VERSION "HNNBNNNYNNNNNNNNNNNNNNNNNNNNNNNNNNNNNNNNNN/4/%%%/4/'%**4NNN///"

NS_ :

BS_:

BU_: BAP_Tester CGS Gateway Gateway_PAG HUD Kombi Kombi_LB Kombi_PAG Waehlhebel_SB

BO_ 1640 Klima_12: 8 Gateway
 SG_ KL_LRH_Taster : 0|1@1+ (1.0,0.0) [0.0|1] ""  Vector__XXX
 SG_ KL_LRH_Stufe : 1|2@1+ (1.0,0.0) [0.0|3] ""  Kombi,Kombi_LB
 SG_ HSH_Taster : 3|2@1+ (1.0,0.0) [0.0|3] ""  Vector__XXX
 SG_ FSH_Taster : 5|1@1+ (1.0,0.0) [0.0|1] ""  Vector__XXX
 SG_ KL_Zuheizer_Freigabe : 6|1@1+ (1.0,0.0) [0.0|1] ""  Vector__XXX
 SG_ KL_Beschlagsgefahr : 7|1@1+ (1.0,0.0) [0.0|1] ""  Vector__XXX
 SG_ KL_SIH_Soll_li : 8|3@1+ (1,0) [0|6] ""  Vector__XXX
 SG_ KL_SIH_Soll_re : 11|3@1+ (1,0) [0|6] ""  Vector__XXX
 SG_ KRH_Soll_li : 14|2@1+ (1.0,0.0) [0.0|3] ""  Vector__XXX
 SG_ KL_SIL_Soll_li : 16|3@1+ (1,0) [0|6] ""  Vector__XXX
 SG_ KL_SIL_Soll_re : 19|3@1+ (1,0) [0|6] ""  Vector__XXX
 SG_ KRH_Soll_re : 22|2@1+ (1.0,0.0) [0.0|3] ""  Vector__XXX
 SG_ KL_Geblspng_Soll : 24|8@1+ (0.05,1.45) [1.50|14.00] "Unit_Volt"  Vector__XXX
 SG_ KL_Geblspng_Fond_Soll : 32|8@1+ (0.05,1.45) [1.50|14.00] "Unit_Volt"  Vector__XXX
 SG_ KL_I_Geblaese : 40|8@1+ (0.25,0) [0.00|63.50] "Unit_Amper"  Vector__XXX
 SG_ KL_Kompressorstrom_soll : 48|10@1+ (1,0) [0|1021] ""  Vector__XXX
 SG_ KL_Umluftklappe_Status : 58|4@1+ (1.0,0.0) [0.0|15] ""  Vector__XXX
 SG_ KL_PTC_Verbauinfo : 62|2@1+ (1.0,0.0) [0.0|3] ""  Vector__XXX

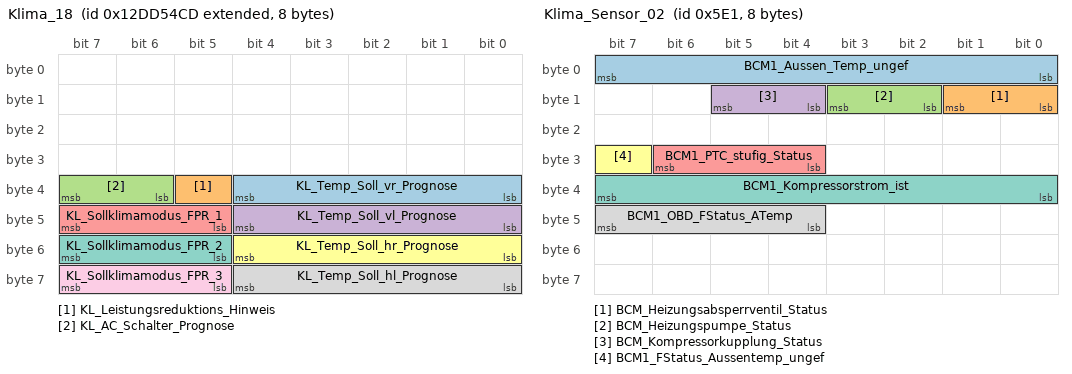
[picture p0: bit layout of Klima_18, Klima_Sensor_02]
BO_ 2463978701 Klima_18: 8 Gateway
 SG_ KL_Temp_Soll_vr_Prognose : 32|5@1+ (0.5,15.5) [15.5|30.0] "Unit_DegreCelsi"  Vector__XXX
 SG_ KL_Leistungsreduktions_Hinweis : 37|1@1+ (1.0,0.0) [0.0|1] ""  Kombi_PAG
 SG_ KL_AC_Schalter_Prognose : 38|2@1+ (1.0,0.0) [0.0|3] ""  Vector__XXX
 SG_ KL_Temp_Soll_vl_Prognose : 40|5@1+ (0.5,15.5) [15.5|30.0] "Unit_DegreCelsi"  Vector__XXX
 SG_ KL_Sollklimamodus_FPR_1 : 45|3@1+ (1.0,0.0) [0.0|7] ""  Vector__XXX
 SG_ KL_Temp_Soll_hr_Prognose : 48|5@1+ (0.5,15.5) [15.5|30.0] "Unit_DegreCelsi"  Vector__XXX
 SG_ KL_Sollklimamodus_FPR_2 : 53|3@1+ (1.0,0.0) [0.0|7] ""  Vector__XXX
 SG_ KL_Temp_Soll_hl_Prognose : 56|5@1+ (0.5,15.5) [15.5|30.0] "Unit_DegreCelsi"  Vector__XXX
 SG_ KL_Sollklimamodus_FPR_3 : 61|3@1+ (1.0,0.0) [0.0|7] ""  Vector__XXX

BO_ 1505 Klima_Sensor_02: 8 Gateway
 SG_ BCM1_Aussen_Temp_ungef : 0|8@1+ (0.5,-50) [-50.0|76.0] "Unit_DegreCelsi"  Kombi,Kombi_LB,Kombi_PAG
 SG_ BCM_Heizungsabsperrventil_Status : 8|2@1+ (1.0,0.0) [0.0|3] ""  Vector__XXX
 SG_ BCM_Heizungspumpe_Status : 10|2@1+ (1.0,0.0) [0.0|3] ""  Vector__XXX
 SG_ BCM_Kompressorkupplung_Status : 12|2@1+ (1.0,0.0) [0.0|3] ""  Vector__XXX
 SG_ BCM1_PTC_stufig_Status : 28|3@1+ (1.0,0.0) [0.0|7] ""  Vector__XXX
 SG_ BCM1_FStatus_Aussentemp_ungef : 31|1@1+ (1.0,0.0) [0.0|1] ""  Kombi,Kombi_LB,Kombi_PAG
 SG_ BCM1_Kompressorstrom_ist : 32|8@1+ (4,0) [0|1000] "Unit_MilliAmper"  Vector__XXX
 SG_ BCM1_OBD_FStatus_ATemp : 44|4@1+ (1.0,0.0) [0.0|15] ""  Vector__XXX

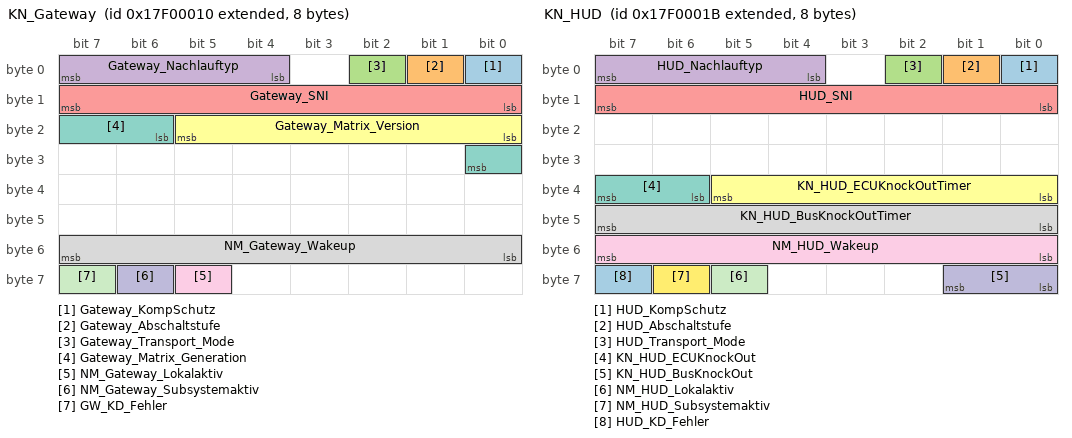
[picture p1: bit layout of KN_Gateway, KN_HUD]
BO_ 2549088272 KN_Gateway: 8 Gateway
 SG_ Gateway_KompSchutz : 0|1@1+ (1.0,0.0) [0.0|1] ""  Vector__XXX
 SG_ Gateway_Abschaltstufe : 1|1@1+ (1.0,0.0) [0.0|1] ""  Vector__XXX
 SG_ Gateway_Transport_Mode : 2|1@1+ (1.0,0.0) [0.0|1] ""  Vector__XXX
 SG_ Gateway_Nachlauftyp : 4|4@1+ (1.0,0.0) [0.0|15] ""  Vector__XXX
 SG_ Gateway_SNI : 8|8@1+ (1.0,0.0) [0.0|255] ""  Vector__XXX
 SG_ Gateway_Matrix_Version : 16|6@1+ (1,0) [0|63] "Unit_None"  Vector__XXX
 SG_ Gateway_Matrix_Generation : 22|3@1+ (1,0) [0|7] "Unit_None"  Vector__XXX
 SG_ NM_Gateway_Wakeup : 48|8@1+ (1.0,0.0) [0.0|255] ""  Vector__XXX
 SG_ NM_Gateway_Lokalaktiv : 61|1@1+ (1.0,0.0) [0.0|1] ""  Vector__XXX
 SG_ NM_Gateway_Subsystemaktiv : 62|1@1+ (1.0,0.0) [0.0|1] ""  Vector__XXX
 SG_ GW_KD_Fehler : 63|1@1+ (1.0,0.0) [0.0|1] ""  Vector__XXX

BO_ 2549088283 KN_HUD: 8 HUD
 SG_ HUD_KompSchutz : 0|1@1+ (1.0,0.0) [0.0|1] ""  Vector__XXX
 SG_ HUD_Abschaltstufe : 1|1@1+ (1.0,0.0) [0.0|1] ""  Vector__XXX
 SG_ HUD_Transport_Mode : 2|1@1+ (1.0,0.0) [0.0|1] ""  Vector__XXX
 SG_ HUD_Nachlauftyp : 4|4@1+ (1.0,0.0) [0.0|15] ""  Gateway,Gateway_PAG
 SG_ HUD_SNI : 8|8@1+ (1.0,0.0) [0.0|255] ""  Gateway,Gateway_PAG
 SG_ KN_HUD_ECUKnockOutTimer : 32|6@1+ (1,0) [0|62] "Unit_Minut"  Gateway,Gateway_PAG
 SG_ KN_HUD_ECUKnockOut : 38|2@1+ (1.0,0.0) [0.0|3] ""  Gateway,Gateway_PAG
 SG_ KN_HUD_BusKnockOutTimer : 40|8@1+ (1,0) [0|254] "Unit_Minut"  Gateway,Gateway_PAG
 SG_ NM_HUD_Wakeup : 48|8@1+ (1.0,0.0) [0.0|255] ""  Vector__XXX
 SG_ KN_HUD_BusKnockOut : 56|2@1+ (1.0,0.0) [0.0|3] ""  Gateway,Gateway_PAG
 SG_ NM_HUD_Lokalaktiv : 61|1@1+ (1.0,0.0) [0.0|1] ""  Gateway,Gateway_PAG
 SG_ NM_HUD_Subsystemaktiv : 62|1@1+ (1.0,0.0) [0.0|1] ""  Vector__XXX
 SG_ HUD_KD_Fehler : 63|1@1+ (1.0,0.0) [0.0|1] ""  Gateway,Gateway_PAG

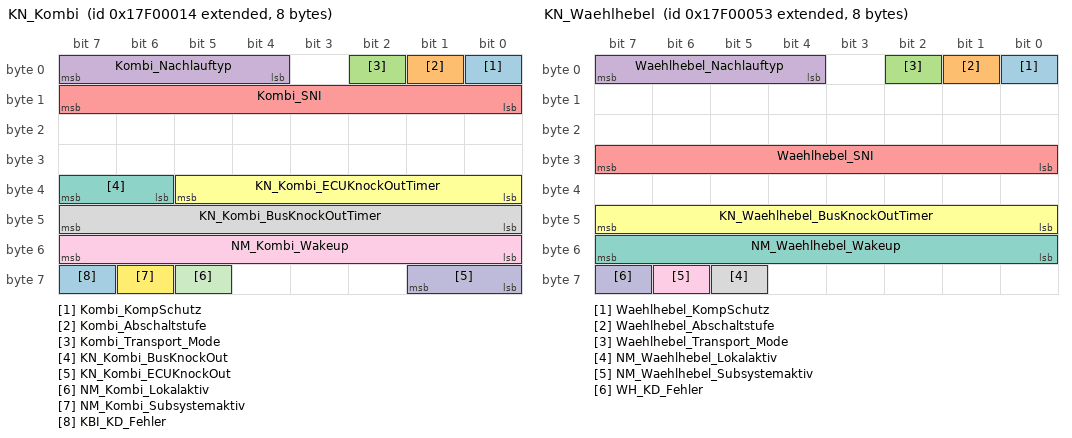
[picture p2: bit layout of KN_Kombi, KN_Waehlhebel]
BO_ 2549088276 KN_Kombi: 8 Kombi
 SG_ Kombi_KompSchutz : 0|1@1+ (1.0,0.0) [0.0|1] ""  Vector__XXX
 SG_ Kombi_Abschaltstufe : 1|1@1+ (1.0,0.0) [0.0|1] ""  Vector__XXX
 SG_ Kombi_Transport_Mode : 2|1@1+ (1.0,0.0) [0.0|1] ""  Vector__XXX
 SG_ Kombi_Nachlauftyp : 4|4@1+ (1.0,0.0) [0.0|15] ""  Gateway,Gateway_PAG
 SG_ Kombi_SNI : 8|8@1+ (1.0,0.0) [0.0|255] ""  Gateway,Gateway_PAG
 SG_ KN_Kombi_ECUKnockOutTimer : 32|6@1+ (1,0) [0|62] "Unit_Minut"  Gateway,Gateway_PAG
 SG_ KN_Kombi_BusKnockOut : 38|2@1+ (1.0,0.0) [0.0|3] ""  Gateway,Gateway_PAG
 SG_ KN_Kombi_BusKnockOutTimer : 40|8@1+ (1,0) [0|254] ""  Gateway,Gateway_PAG
 SG_ NM_Kombi_Wakeup : 48|8@1+ (1.0,0.0) [0.0|255] ""  Vector__XXX
 SG_ KN_Kombi_ECUKnockOut : 56|2@1+ (1.0,0.0) [0.0|3] ""  Gateway,Gateway_PAG
 SG_ NM_Kombi_Lokalaktiv : 61|1@1+ (1.0,0.0) [0.0|1] ""  Gateway,Gateway_PAG
 SG_ NM_Kombi_Subsystemaktiv : 62|1@1+ (1.0,0.0) [0.0|1] ""  Gateway,Gateway_PAG
 SG_ KBI_KD_Fehler : 63|1@1+ (1.0,0.0) [0.0|1] ""  Gateway,Gateway_PAG

BO_ 2549088339 KN_Waehlhebel: 8 CGS
 SG_ Waehlhebel_KompSchutz : 0|1@1+ (1.0,0.0) [0.0|1] ""  Vector__XXX
 SG_ Waehlhebel_Abschaltstufe : 1|1@1+ (1.0,0.0) [0.0|1] ""  Vector__XXX
 SG_ Waehlhebel_Transport_Mode : 2|1@1+ (1.0,0.0) [0.0|1] ""  Vector__XXX
 SG_ Waehlhebel_Nachlauftyp : 4|4@1+ (1.0,0.0) [0.0|15] ""  Gateway,Gateway_PAG
 SG_ Waehlhebel_SNI : 24|8@1+ (1.0,0.0) [0.0|255] ""  Gateway,Gateway_PAG
 SG_ KN_Waehlhebel_BusKnockOutTimer : 40|8@1+ (1,0) [0|254] ""  Gateway,Gateway_PAG
 SG_ NM_Waehlhebel_Wakeup : 48|8@1+ (1.0,0.0) [0.0|255] ""  Vector__XXX
 SG_ NM_Waehlhebel_Lokalaktiv : 61|1@1+ (1.0,0.0) [0.0|1] ""  Gateway,Gateway_PAG
 SG_ NM_Waehlhebel_Subsystemaktiv : 62|1@1+ (1.0,0.0) [0.0|1] ""  Vector__XXX
 SG_ WH_KD_Fehler : 63|1@1+ (1.0,0.0) [0.0|1] ""  Gateway,Gateway_PAG

BO_ 779 Kombi_01: 8 Kombi
 SG_ KBI_ABS_Lampe : 0|1@1+ (1.0,0.0) [0.0|1] ""  Gateway,Gateway_PAG
 SG_ KBI_ESP_Lampe : 1|1@1+ (1.0,0.0) [0.0|1] ""  Gateway,Gateway_PAG
 SG_ KBI_BKL_Lampe : 2|1@1+ (1.0,0.0) [0.0|1] ""  Gateway,Gateway_PAG
 SG_ KBI_Airbag_Lampe : 3|1@1+ (1.0,0.0) [0.0|1] ""  Gateway,Gateway_PAG
 SG_ KBI_SILA_gueltig : 4|1@1+ (1.0,0.0) [0.0|1] ""  Gateway,Gateway_PAG
 SG_ KBI_Lenkung_Lampe : 5|1@1+ (1,0) [0|1] ""  Gateway,Gateway_PAG
 SG_ KBI_Vorglueh_System_Lampe : 6|1@1+ (1.0,0.0) [0.0|1] ""  Gateway,Gateway_PAG
 SG_ KBI_NV_in_Anzeige : 7|1@1+ (1.0,0.0) [0.0|1] ""  Gateway,Gateway_PAG
 SG_ Kombi_01_BZ : 8|4@1+ (1,0) [0|15] ""  Gateway,Gateway_PAG
 SG_ KBI_Anzeigestatus_ACC : 12|1@1+ (1.0,0.0) [0.0|1] ""  Gateway,Gateway_PAG,HUD
 SG_ KBI_Anzeigestatus_GRA : 13|2@1+ (1.0,0.0) [0.0|3] ""  Gateway,Gateway_PAG
 SG_ KBI_Tankwarnung : 16|1@1+ (1.0,0.0) [0.0|1] ""  Gateway,Gateway_PAG
 SG_ KBI_MFA_v_Einheit_01 : 17|1@1+ (1.0,0.0) [0.0|1] ""  Gateway,Gateway_PAG,HUD
 SG_ KBI_im_Stellgliedtest : 18|1@1+ (1.0,0.0) [0.0|1] ""  Gateway,Gateway_PAG
 SG_ KBI_Anzeigefehler_LDW : 19|2@1+ (1.0,0.0) [0.0|3] ""  Gateway,Gateway_PAG
 SG_ KBI_Tankwarnung_ungueltig : 21|1@1+ (1.0,0.0) [0.0|1] ""  Gateway,Gateway_PAG
 SG_ KBI_Handbremse : 23|1@1+ (1.0,0.0) [0.0|1] ""  Gateway,Gateway_PAG
 SG_ KBI_V_Digital : 24|9@1+ (1,0) [0|511] ""  Gateway,Gateway_PAG,HUD
 SG_ KBI_PLA_in_Anzeige : 33|1@1+ (1.0,0.0) [0.0|1] ""  Gateway,Gateway_PAG
 SG_ KBI_Anzeigefehler_NV : 34|1@1+ (1.0,0.0) [0.0|1] ""  Gateway,Gateway_PAG
 SG_ KBI_Anzeigestatus_LIM : 35|2@1+ (1.0,0.0) [0.0|3] ""  Gateway,Gateway_PAG
 SG_ KBI_ARA_in_Anzeige : 37|1@1+ (1.0,0.0) [0.0|1] ""  Gateway,Gateway_PAG
 SG_ KBI_Taster_Lift : 38|1@1+ (1.0,0.0) [0.0|1] ""  Gateway,Gateway_PAG
 SG_ KBI_Taster_Fahrwerk : 39|1@1+ (1.0,0.0) [0.0|1] ""  Gateway,Gateway_PAG
 SG_ KBI_GRA_Hauptschalter : 40|2@1+ (1.0,0.0) [0.0|3] ""  Gateway,Gateway_PAG
 SG_ KBI_Bestaetigung_ESP_Off : 42|2@1+ (1.0,0.0) [0.0|3] ""  Gateway,Gateway_PAG
 SG_ KBI_angez_Geschw : 48|10@1+ (0.32,0) [0.00|325.12] "Unit_KiloMeterPerHour"  Gateway,Gateway_PAG
 SG_ KBI_Einheit_Tacho : 58|1@1+ (1.0,0.0) [0.0|1] ""  Gateway,Gateway_PAG
 SG_ KBI_Konsistenz_ACC : 59|1@1+ (1.0,0.0) [0.0|1] ""  Gateway,Gateway_PAG
 SG_ KBI_Fehler_Anzeige_ACC : 60|1@1+ (1.0,0.0) [0.0|1] ""  Gateway,Gateway_PAG
 SG_ KBI_Anzeigefehler_SWA : 61|2@1+ (1.0,0.0) [0.0|3] ""  Gateway,Gateway_PAG
 SG_ KBI_Systemstatus : 63|1@1+ (1.0,0.0) [0.0|1] ""  Gateway,Gateway_PAG

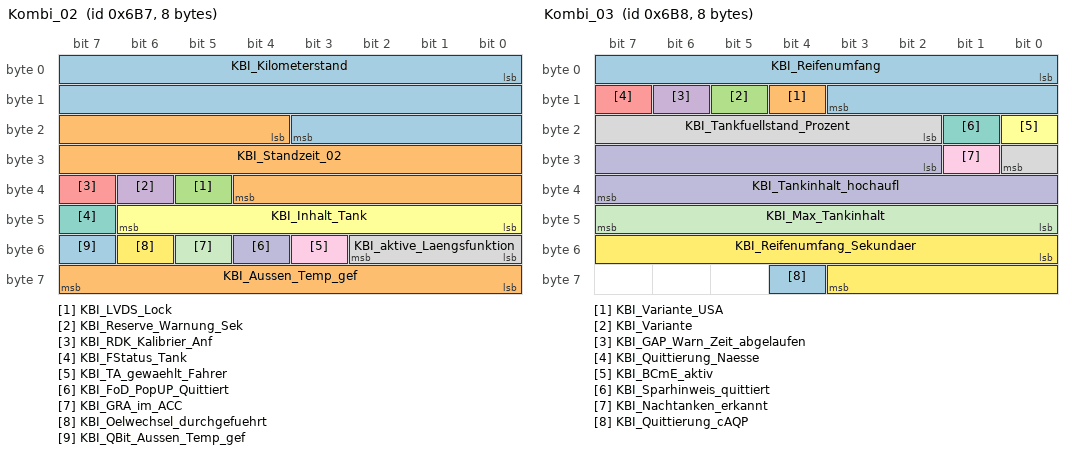
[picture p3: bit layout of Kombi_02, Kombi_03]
BO_ 1719 Kombi_02: 8 Kombi
 SG_ KBI_Kilometerstand : 0|20@1+ (1,0) [0|1048573] "Unit_KiloMeter"  Gateway,Gateway_PAG
 SG_ KBI_Standzeit_02 : 20|17@1+ (1,0) [0|131068] "Unit_Secon"  Gateway,Gateway_PAG
 SG_ KBI_LVDS_Lock : 37|1@1+ (1.0,0.0) [0.0|1] ""  Gateway,Gateway_PAG
 SG_ KBI_Reserve_Warnung_Sek : 38|1@1+ (1.0,0.0) [0.0|1] ""  Gateway,Gateway_PAG
 SG_ KBI_RDK_Kalibrier_Anf : 39|1@1+ (1.0,0.0) [0.0|1] ""  Gateway,Gateway_PAG
 SG_ KBI_Inhalt_Tank : 40|7@1+ (1,0) [0|125] "Unit_Liter"  Gateway,Gateway_PAG
 SG_ KBI_FStatus_Tank : 47|1@1+ (1.0,0.0) [0.0|1] ""  Gateway,Gateway_PAG
 SG_ KBI_aktive_Laengsfunktion : 48|3@1+ (1.0,0.0) [0.0|7] ""  Gateway,Gateway_PAG,HUD
 SG_ KBI_TA_gewaehlt_Fahrer : 51|1@1+ (1.0,0.0) [0.0|1] ""  Gateway,Gateway_PAG
 SG_ KBI_FoD_PopUP_Quittiert : 52|1@1+ (1.0,0.0) [0.0|1] ""  Gateway,Gateway_PAG
 SG_ KBI_GRA_im_ACC : 53|1@1+ (1.0,0.0) [0.0|1] ""  Gateway,Gateway_PAG
 SG_ KBI_Oelwechsel_durchgefuehrt : 54|1@1+ (1.0,0.0) [0.0|1] ""  Gateway,Gateway_PAG
 SG_ KBI_QBit_Aussen_Temp_gef : 55|1@1+ (1.0,0.0) [0.0|1] ""  Gateway,Gateway_PAG
 SG_ KBI_Aussen_Temp_gef : 56|8@1+ (0.5,-50) [-50.0|75.0] "Unit_DegreCelsi"  Gateway,Gateway_PAG

BO_ 1720 Kombi_03: 8 Kombi
 SG_ KBI_Reifenumfang : 0|12@1+ (1,0) [0|4095] "Unit_MilliMeter"  Gateway,Gateway_PAG
 SG_ KBI_Variante_USA : 12|1@1+ (1.0,0.0) [0.0|1] ""  Gateway,Gateway_PAG,HUD
 SG_ KBI_Variante : 13|1@1+ (1.0,0.0) [0.0|1] ""  Gateway,Gateway_PAG,HUD
 SG_ KBI_GAP_Warn_Zeit_abgelaufen : 14|1@1+ (1.0,0.0) [0.0|1] ""  Gateway,Gateway_PAG
 SG_ KBI_Quittierung_Naesse : 15|1@1+ (1.0,0.0) [0.0|1] ""  Gateway,Gateway_PAG
 SG_ KBI_BCmE_aktiv : 16|1@1+ (1.0,0.0) [0.0|1] ""  Gateway,Gateway_PAG
 SG_ KBI_Sparhinweis_quittiert : 17|1@1+ (1.0,0.0) [0.0|1] ""  Gateway,Gateway_PAG
 SG_ KBI_Tankfuellstand_Prozent : 18|7@1+ (1,0) [0|100] "Unit_PerCent"  Gateway,Gateway_PAG
 SG_ KBI_Nachtanken_erkannt : 25|1@1+ (1.0,0.0) [0.0|1] ""  Gateway,Gateway_PAG
 SG_ KBI_Tankinhalt_hochaufl : 26|14@1+ (0.01,0) [0.00|163.81] "Unit_Liter"  Gateway,Gateway_PAG
 SG_ KBI_Max_Tankinhalt : 40|8@1+ (0.5,0) [0.0|126.5] ""  Gateway,Gateway_PAG
 SG_ KBI_Reifenumfang_Sekundaer : 48|12@1+ (1,0) [0|4095] "Unit_MilliMeter"  Gateway,Gateway_PAG
 SG_ KBI_Quittierung_cAQP : 60|1@1+ (1.0,0.0) [0.0|1] ""  Gateway,Gateway_PAG

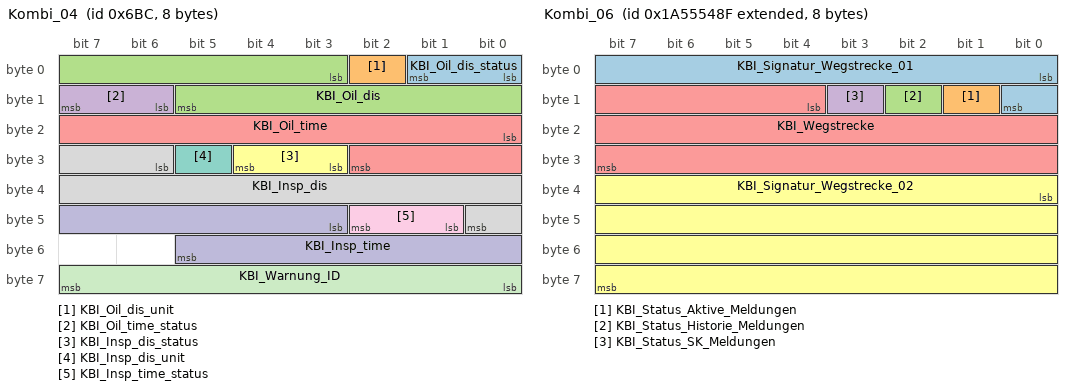
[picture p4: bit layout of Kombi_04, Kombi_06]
BO_ 1724 Kombi_04: 8 Kombi
 SG_ KBI_Oil_dis_status : 0|2@1+ (1.0,0.0) [0.0|3] ""  Gateway,Gateway_PAG
 SG_ KBI_Oil_dis_unit : 2|1@1+ (1.0,0.0) [0.0|1] ""  Gateway,Gateway_PAG
 SG_ KBI_Oil_dis : 3|11@1+ (100,0) [0|204700] ""  Gateway,Gateway_PAG
 SG_ KBI_Oil_time_status : 14|2@1+ (1.0,0.0) [0.0|3] ""  Gateway,Gateway_PAG
 SG_ KBI_Oil_time : 16|11@1+ (1,0) [0|2047] ""  Gateway,Gateway_PAG
 SG_ KBI_Insp_dis_status : 27|2@1+ (1.0,0.0) [0.0|3] ""  Gateway,Gateway_PAG
 SG_ KBI_Insp_dis_unit : 29|1@1+ (1.0,0.0) [0.0|1] ""  Gateway,Gateway_PAG
 SG_ KBI_Insp_dis : 30|11@1+ (100,0) [0|204700] ""  Gateway,Gateway_PAG
 SG_ KBI_Insp_time_status : 41|2@1+ (1.0,0.0) [0.0|3] ""  Gateway,Gateway_PAG
 SG_ KBI_Insp_time : 43|11@1+ (1,0) [0|2047] ""  Gateway,Gateway_PAG
 SG_ KBI_Warnung_ID : 56|8@1+ (1,0) [0|255] ""  Gateway,Gateway_PAG

BO_ 2589283471 Kombi_06: 8 Kombi
 SG_ KBI_Signatur_Wegstrecke_01 : 0|9@1+ (1.0,0.0) [0.0|511] ""  Gateway,Gateway_PAG
 SG_ KBI_Status_Aktive_Meldungen : 9|1@1+ (1.0,0.0) [0.0|1] ""  Gateway,Gateway_PAG
 SG_ KBI_Status_Historie_Meldungen : 10|1@1+ (1.0,0.0) [0.0|1] ""  Gateway,Gateway_PAG
 SG_ KBI_Status_SK_Meldungen : 11|1@1+ (1.0,0.0) [0.0|1] ""  Gateway,Gateway_PAG
 SG_ KBI_Wegstrecke : 12|20@1+ (1.0,0.0) [0.0|1048575] ""  Gateway,Gateway_PAG
 SG_ KBI_Signatur_Wegstrecke_02 : 32|32@1+ (1.0,0.0) [0.0|4294967295] ""  Gateway,Gateway_PAG

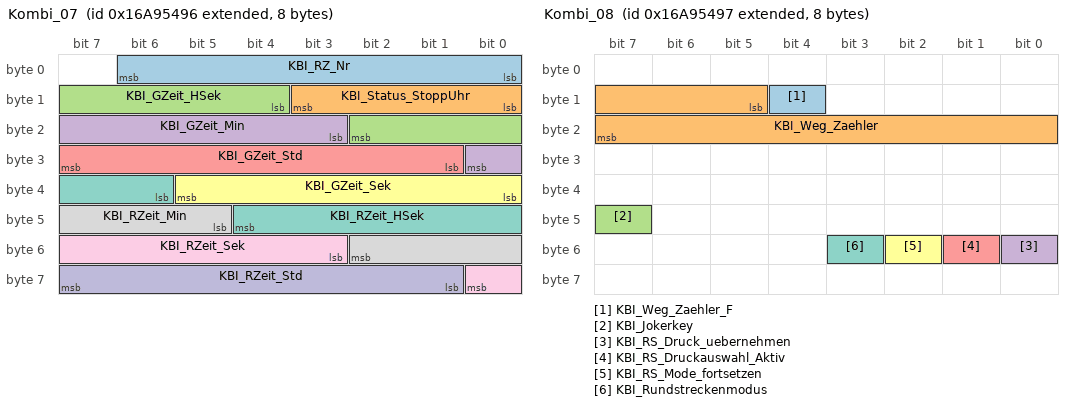
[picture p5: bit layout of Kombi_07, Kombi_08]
BO_ 2527679638 Kombi_07: 8 Kombi
 SG_ KBI_RZ_Nr : 0|7@1+ (1,0) [0|99] ""  Gateway,Gateway_PAG,HUD
 SG_ KBI_Status_StoppUhr : 8|4@1+ (1.0,0.0) [0.0|15] ""  Gateway,Gateway_PAG,HUD
 SG_ KBI_GZeit_HSek : 12|7@1+ (1,0) [0|99] "Unit_MilliSecon"  Gateway,Gateway_PAG,HUD
 SG_ KBI_GZeit_Min : 19|6@1+ (1,0) [0|59] "Unit_Minut"  Gateway,Gateway_PAG,HUD
 SG_ KBI_GZeit_Std : 25|7@1+ (1,0) [0|99] "Unit_Hours"  Gateway,Gateway_PAG,HUD
 SG_ KBI_GZeit_Sek : 32|6@1+ (1,0) [0|59] "Unit_Secon"  Gateway,Gateway_PAG,HUD
 SG_ KBI_RZeit_HSek : 38|7@1+ (1,0) [0|99] ""  Gateway,Gateway_PAG,HUD
 SG_ KBI_RZeit_Min : 45|6@1+ (1,0) [0|59] "Unit_Minut"  Gateway,Gateway_PAG,HUD
 SG_ KBI_RZeit_Sek : 51|6@1+ (1,0) [0|59] "Unit_Secon"  Gateway,Gateway_PAG,HUD
 SG_ KBI_RZeit_Std : 57|7@1+ (1,0) [0|99] "Unit_Hours"  Gateway,Gateway_PAG,HUD

BO_ 2527679639 Kombi_08: 8 Kombi
 SG_ KBI_Weg_Zaehler_F : 12|1@1+ (1.0,0.0) [0.0|1] ""  Gateway,Gateway_PAG
 SG_ KBI_Weg_Zaehler : 13|11@1+ (1,0) [0|2047] "Unit_Meter"  Gateway,Gateway_PAG
 SG_ KBI_Jokerkey : 47|1@1+ (1.0,0.0) [0.0|1] ""  Gateway,Gateway_PAG
 SG_ KBI_RS_Druck_uebernehmen : 48|1@1+ (1.0,0.0) [0.0|1] ""  Gateway,Gateway_PAG
 SG_ KBI_RS_Druckauswahl_Aktiv : 49|1@1+ (1.0,0.0) [0.0|1] ""  Gateway,Gateway_PAG
 SG_ KBI_RS_Mode_fortsetzen : 50|1@1+ (1.0,0.0) [0.0|1] ""  Gateway,Gateway_PAG
 SG_ KBI_Rundstreckenmodus : 51|1@1+ (1.0,0.0) [0.0|1] ""  Gateway,Gateway_PAG

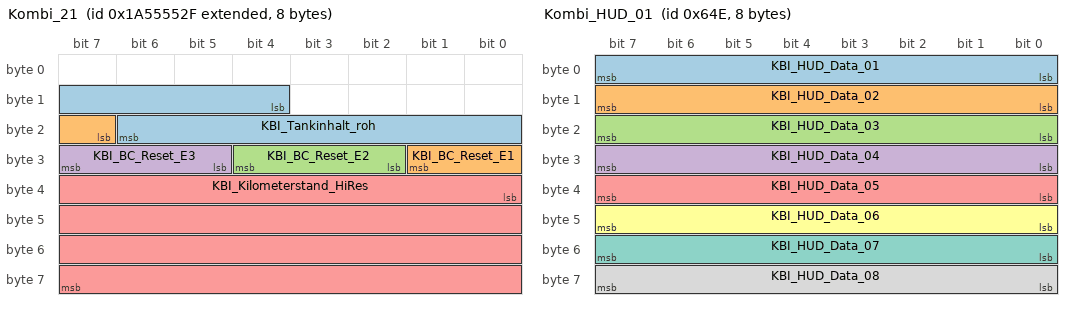
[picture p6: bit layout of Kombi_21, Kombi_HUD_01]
BO_ 2589283631 Kombi_21: 8 Kombi
 SG_ KBI_Tankinhalt_roh : 12|11@1+ (0.1,0) [0.0|204.5] "Unit_Liter"  Gateway,Gateway_PAG
 SG_ KBI_BC_Reset_E1 : 23|3@1+ (1.0,0.0) [0.0|7] ""  Gateway,Gateway_PAG
 SG_ KBI_BC_Reset_E2 : 26|3@1+ (1.0,0.0) [0.0|7] ""  Gateway,Gateway_PAG
 SG_ KBI_BC_Reset_E3 : 29|3@1+ (1.0,0.0) [0.0|7] ""  Gateway,Gateway_PAG
 SG_ KBI_Kilometerstand_HiRes : 32|32@1+ (0.1,0) [0.0|429496729.5] "Unit_KiloMeter"  Gateway,Gateway_PAG

BO_ 2527679656 Kombi_23: 8 Kombi
 SG_ KBI_StartupAnimation : 61|3@1+ (1.0,0.0) [0.0|7] ""  Gateway,Gateway_PAG

BO_ 1614 Kombi_HUD_01: 8 Kombi
 SG_ KBI_HUD_Data_01 : 0|8@1+ (1.0,0.0) [0.0|255] ""  Gateway,Gateway_PAG,HUD
 SG_ KBI_HUD_Data_02 : 8|8@1+ (1.0,0.0) [0.0|255] ""  Gateway,Gateway_PAG,HUD
 SG_ KBI_HUD_Data_03 : 16|8@1+ (1.0,0.0) [0.0|255] ""  Gateway,Gateway_PAG,HUD
 SG_ KBI_HUD_Data_04 : 24|8@1+ (1.0,0.0) [0.0|255] ""  Gateway,Gateway_PAG,HUD
 SG_ KBI_HUD_Data_05 : 32|8@1+ (1.0,0.0) [0.0|255] ""  Gateway,Gateway_PAG,HUD
 SG_ KBI_HUD_Data_06 : 40|8@1+ (1.0,0.0) [0.0|255] ""  Gateway,Gateway_PAG,HUD
 SG_ KBI_HUD_Data_07 : 48|8@1+ (1.0,0.0) [0.0|255] ""  Gateway,Gateway_PAG,HUD
 SG_ KBI_HUD_Data_08 : 56|8@1+ (1.0,0.0) [0.0|255] ""  Gateway,Gateway_PAG,HUD

BO_ 2549874964 KS_Kombi_Req: 8 Gateway
 SG_ KS_Kombi_Req_Data : 0|64@1+ (1.0,0.0) [0.0|18446744073709551615] ""  Kombi,Kombi_LB,Kombi_PAG

BO_ 2550006036 KS_Kombi_Resp: 8 Kombi
 SG_ KS_Kombi_Resp_Data : 0|64@1+ (1.0,0.0) [0.0|18446744073709551615] ""  Gateway,Gateway_PAG

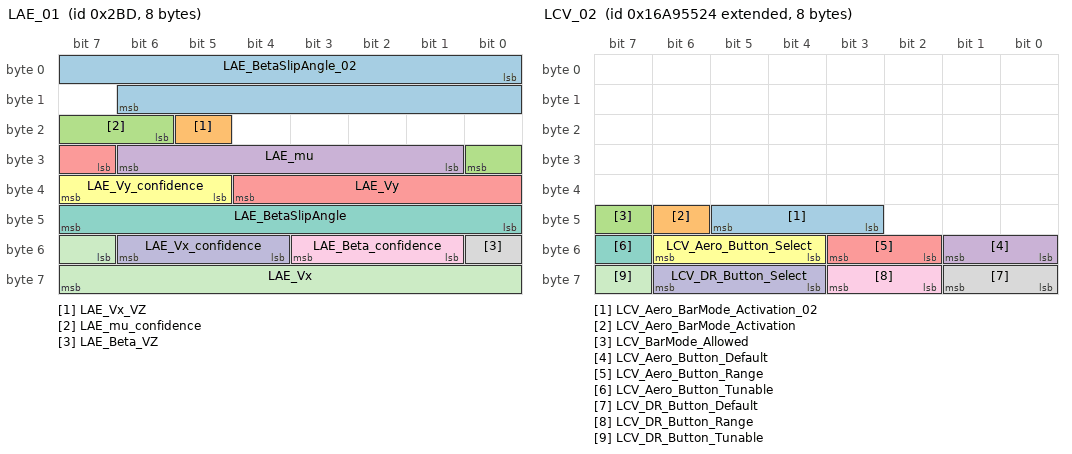
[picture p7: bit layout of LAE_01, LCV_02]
BO_ 701 LAE_01: 8 Gateway
 SG_ LAE_BetaSlipAngle_02 : 0|15@1+ (0.01,0) [0.00|327.65] "Unit_DegreOfArc"  Kombi_LB
 SG_ LAE_Vx_VZ : 21|1@1+ (1.0,0.0) [0.0|1] ""  Kombi_LB
 SG_ LAE_mu_confidence : 22|3@1+ (1.0,0.0) [0.0|7] ""  Kombi_LB
 SG_ LAE_mu : 25|6@1+ (0.05,0) [0.00|3.05] "Unit_None"  Kombi_LB
 SG_ LAE_Vy : 31|6@1+ (0.491803,0) [0.000000|29.999983] "Unit_MeterPerSecon"  Kombi_LB
 SG_ LAE_Vy_confidence : 37|3@1+ (1.0,0.0) [0.0|7] ""  Kombi_LB
 SG_ LAE_BetaSlipAngle : 40|8@1+ (0.711462451,0) [0E-9|180.000000103] "Unit_DegreOfArc"  Kombi_LB
 SG_ LAE_Beta_VZ : 48|1@1+ (1.0,0.0) [0.0|1] ""  Kombi_LB
 SG_ LAE_Beta_confidence : 49|3@1+ (1.0,0.0) [0.0|7] ""  Kombi_LB
 SG_ LAE_Vx_confidence : 52|3@1+ (1.0,0.0) [0.0|7] ""  Kombi_LB
 SG_ LAE_Vx : 55|9@1+ (0.25540275,0) [0E-8|129.99999975] "Unit_MeterPerSecon"  Kombi_LB

BO_ 2463978818 LCV_01: 8 Gateway
 SG_ LCV_01_CRC : 0|8@1+ (1,0) [0|255] ""  Kombi_LB
 SG_ LCV_01_BZ : 8|4@1+ (1,0) [0|15] ""  Kombi_LB
 SG_ LCV_ESP_Zuschaltung : 12|1@1+ (1.0,0.0) [0.0|1] ""  Kombi_LB
 SG_ LCV_BrakeGongTemp : 13|1@1+ (1.0,0.0) [0.0|1] ""  Kombi_LB
 SG_ BTM_BrakeSystem_Status : 14|4@1+ (1.0,0.0) [0.0|15] ""  Kombi_LB
 SG_ BTM_BrakeSystem_Text : 18|4@1+ (1.0,0.0) [0.0|15] ""  Kombi_LB
 SG_ BTM_BrakeSystem_Warnlampe : 22|1@1+ (1.0,0.0) [0.0|1] ""  Kombi_LB
 SG_ LCV_Aero_EngineBay_Cooling : 23|1@1+ (1.0,0.0) [0.0|1] ""  Kombi_LB
 SG_ LCV_Aero_Front_System_Status : 24|3@1+ (1.0,0.0) [0.0|7] ""  Kombi_LB
 SG_ LCV_Aero_Rear_System_Status : 27|3@1+ (1.0,0.0) [0.0|7] ""  Kombi_LB
 SG_ LCV_DR_Systemstatus : 30|3@1+ (1.0,0.0) [0.0|7] ""  Kombi_LB
 SG_ LCV_DR_Text : 33|3@1+ (1.0,0.0) [0.0|7] ""  Kombi_LB
 SG_ LCV_DR_Warnlampe : 36|2@1+ (1.0,0.0) [0.0|3] ""  Kombi_LB
 SG_ LCV_Lift_Status : 38|4@1+ (1.0,0.0) [0.0|15] ""  Kombi_LB
 SG_ LCV_Lift_Text : 42|3@1+ (1.0,0.0) [0.0|7] ""  Kombi_LB
 SG_ LCV_Lift_Warnlampe_Status : 45|2@1+ (1.0,0.0) [0.0|3] ""  Kombi_LB
 SG_ LCV_Aero_Perf_Limit_Speed : 47|8@1+ (1,100) [100|353] "Unit_KiloMeterPerHour"  Kombi_LB
 SG_ LCV_Aero_Perf_Limit : 55|1@1+ (1.0,0.0) [0.0|1] ""  Kombi_LB
 SG_ LCV_HD_offen : 56|1@1+ (1.0,0.0) [0.0|1] ""  Kombi_LB
 SG_ LCV_Aero_Text : 57|3@1+ (1.0,0.0) [0.0|7] ""  Kombi_LB

BO_ 2527679780 LCV_02: 8 Gateway
 SG_ LCV_Aero_BarMode_Activation_02 : 43|3@1+ (1.0,0.0) [0.0|7] ""  Kombi_LB
 SG_ LCV_Aero_BarMode_Activation : 46|1@1+ (1.0,0.0) [0.0|1] ""  Vector__XXX
 SG_ LCV_BarMode_Allowed : 47|1@1+ (1.0,0.0) [0.0|1] ""  Kombi_LB
 SG_ LCV_Aero_Button_Default : 48|2@1+ (1.0,0.0) [0.0|3] ""  Kombi_LB
 SG_ LCV_Aero_Button_Range : 50|2@1+ (1.0,0.0) [0.0|3] ""  Kombi_LB
 SG_ LCV_Aero_Button_Select : 52|3@1+ (1.0,0.0) [0.0|7] ""  Kombi_LB
 SG_ LCV_Aero_Button_Tunable : 55|1@1+ (1.0,0.0) [0.0|1] ""  Kombi_LB
 SG_ LCV_DR_Button_Default : 56|2@1+ (1.0,0.0) [0.0|3] ""  Kombi_LB
 SG_ LCV_DR_Button_Range : 58|2@1+ (1.0,0.0) [0.0|3] ""  Kombi_LB
 SG_ LCV_DR_Button_Select : 60|3@1+ (1.0,0.0) [0.0|7] ""  Kombi_LB
 SG_ LCV_DR_Button_Tunable : 63|1@1+ (1.0,0.0) [0.0|1] ""  Kombi_LB

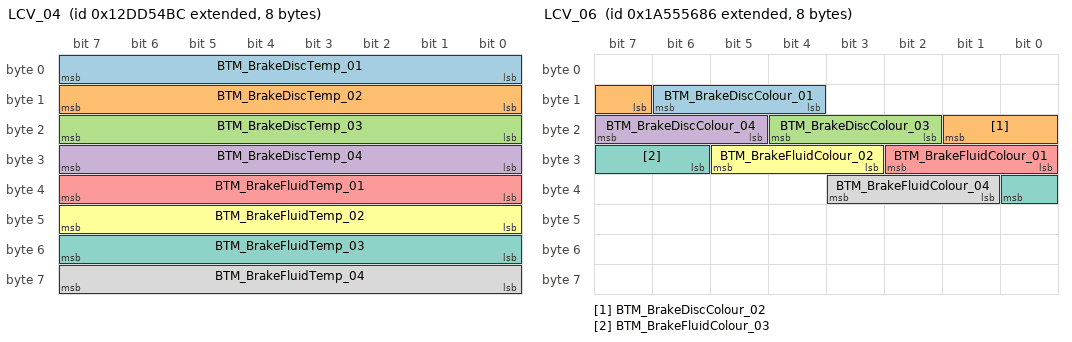
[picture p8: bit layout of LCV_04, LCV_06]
BO_ 2463978684 LCV_04: 8 Gateway
 SG_ BTM_BrakeDiscTemp_01 : 0|8@1+ (10,-30) [-30|2500] "Unit_DegreCelsi"  Kombi_LB
 SG_ BTM_BrakeDiscTemp_02 : 8|8@1+ (10,-30) [-30|2500] "Unit_DegreCelsi"  Kombi_LB
 SG_ BTM_BrakeDiscTemp_03 : 16|8@1+ (10,-30) [-30|2500] "Unit_DegreCelsi"  Kombi_LB
 SG_ BTM_BrakeDiscTemp_04 : 24|8@1+ (10,-30) [-30|2500] "Unit_DegreCelsi"  Kombi_LB
 SG_ BTM_BrakeFluidTemp_01 : 32|8@1+ (2,-30) [-30|476] "Unit_DegreCelsi"  Kombi_LB
 SG_ BTM_BrakeFluidTemp_02 : 40|8@1+ (2,-30) [-30|476] "Unit_DegreCelsi"  Kombi_LB
 SG_ BTM_BrakeFluidTemp_03 : 48|8@1+ (2,-30) [-30|476] "Unit_DegreCelsi"  Kombi_LB
 SG_ BTM_BrakeFluidTemp_04 : 56|8@1+ (2,-30) [-30|476] "Unit_DegreCelsi"  Kombi_LB

BO_ 548 LCV_05: 8 Gateway
 SG_ LCV_Aero_Front_Ratio : 12|7@1+ (1,0) [0|125] "Unit_None"  Kombi_LB
 SG_ LCV_Aero_Long_Ratio : 19|7@1+ (1,0) [0|125] "Unit_None"  Kombi_LB

BO_ 2589283974 LCV_06: 8 Gateway
 SG_ BTM_BrakeDiscColour_01 : 12|3@1+ (1.0,0.0) [0.0|7] ""  Kombi_LB
 SG_ BTM_BrakeDiscColour_02 : 15|3@1+ (1.0,0.0) [0.0|7] ""  Kombi_LB
 SG_ BTM_BrakeDiscColour_03 : 18|3@1+ (1.0,0.0) [0.0|7] ""  Kombi_LB
 SG_ BTM_BrakeDiscColour_04 : 21|3@1+ (1.0,0.0) [0.0|7] ""  Kombi_LB
 SG_ BTM_BrakeFluidColour_01 : 24|3@1+ (1.0,0.0) [0.0|7] ""  Kombi_LB
 SG_ BTM_BrakeFluidColour_02 : 27|3@1+ (1.0,0.0) [0.0|7] ""  Kombi_LB
 SG_ BTM_BrakeFluidColour_03 : 30|3@1+ (1.0,0.0) [0.0|7] ""  Kombi_LB
 SG_ BTM_BrakeFluidColour_04 : 33|3@1+ (1.0,0.0) [0.0|7] ""  Kombi_LB

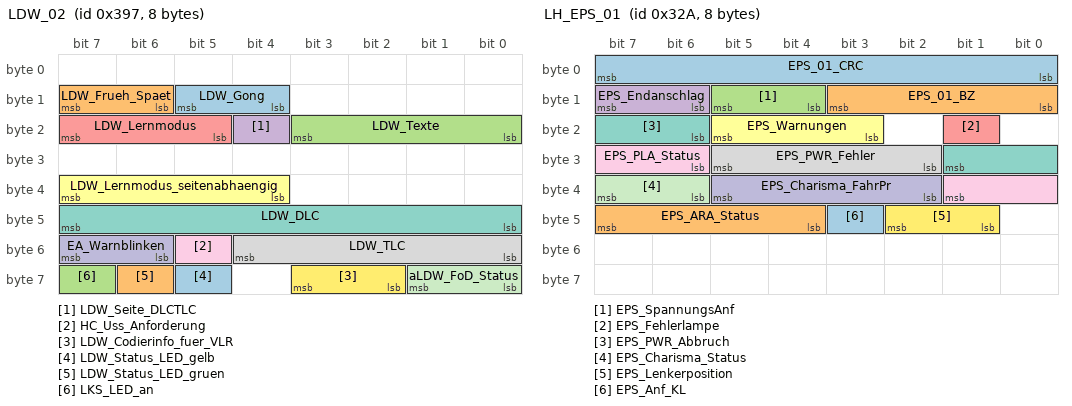
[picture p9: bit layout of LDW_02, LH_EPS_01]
BO_ 919 LDW_02: 8 Gateway
 SG_ LDW_Gong : 12|2@1+ (1.0,0.0) [0.0|3] ""  Kombi,Kombi_LB,Kombi_PAG
 SG_ LDW_Frueh_Spaet : 14|2@1+ (1.0,0.0) [0.0|3] ""  Vector__XXX
 SG_ LDW_Texte : 16|4@1+ (1.0,0.0) [0.0|15] ""  HUD,Kombi,Kombi_LB,Kombi_PAG
 SG_ LDW_Seite_DLCTLC : 20|1@1+ (1.0,0.0) [0.0|1] ""  Vector__XXX
 SG_ LDW_Lernmodus : 21|3@1+ (1.0,0.0) [0.0|7] ""  HUD,Kombi,Kombi_LB,Kombi_PAG
 SG_ LDW_Lernmodus_seitenabhaengig : 36|4@1+ (1.0,0.0) [0.0|15] ""  HUD,Kombi,Kombi_LB,Kombi_PAG
 SG_ LDW_DLC : 40|8@1+ (0.01,-1.25) [-1.25|1.25] "Unit_Meter"  Vector__XXX
 SG_ LDW_TLC : 48|5@1+ (0.1,0) [0.0|3.0] "Unit_Secon"  Vector__XXX
 SG_ HC_Uss_Anforderung : 53|1@1+ (1.0,0.0) [0.0|1] ""  Vector__XXX
 SG_ EA_Warnblinken : 54|2@1+ (1.0,0.0) [0.0|3] ""  Vector__XXX
 SG_ aLDW_FoD_Status : 56|2@1+ (1.0,0.0) [0.0|3] ""  HUD,Kombi,Kombi_LB
 SG_ LDW_Codierinfo_fuer_VLR : 58|2@1+ (1.0,0.0) [0.0|3] ""  Vector__XXX
 SG_ LDW_Status_LED_gelb : 61|1@1+ (1.0,0.0) [0.0|1] ""  HUD,Kombi,Kombi_LB,Kombi_PAG
 SG_ LDW_Status_LED_gruen : 62|1@1+ (1.0,0.0) [0.0|1] ""  HUD,Kombi,Kombi_LB,Kombi_PAG
 SG_ LKS_LED_an : 63|1@1+ (1.0,0.0) [0.0|1] ""  Vector__XXX

BO_ 810 LH_EPS_01: 8 Gateway
 SG_ EPS_01_CRC : 0|8@1+ (1,0) [0|255] ""  Kombi,Kombi_LB,Kombi_PAG
 SG_ EPS_01_BZ : 8|4@1+ (1,0) [0|15] ""  Kombi,Kombi_LB,Kombi_PAG
 SG_ EPS_SpannungsAnf : 12|2@1+ (1.0,0.0) [0.0|3] ""  Vector__XXX
 SG_ EPS_Endanschlag : 14|2@1+ (1.0,0.0) [0.0|3] ""  Vector__XXX
 SG_ EPS_Fehlerlampe : 17|1@1+ (1.0,0.0) [0.0|1] ""  Vector__XXX
 SG_ EPS_Warnungen : 19|3@1+ (1.0,0.0) [0.0|7] ""  Kombi,Kombi_LB,Kombi_PAG
 SG_ EPS_PWR_Abbruch : 22|4@1+ (1.0,0.0) [0.0|15] ""  Vector__XXX
 SG_ EPS_PWR_Fehler : 26|4@1+ (1.0,0.0) [0.0|15] ""  Vector__XXX
 SG_ EPS_PLA_Status : 30|4@1+ (1.0,0.0) [0.0|15] ""  Vector__XXX
 SG_ EPS_Charisma_FahrPr : 34|4@1+ (1.0,0.0) [0.0|15] ""  Kombi_LB
 SG_ EPS_Charisma_Status : 38|2@1+ (1.0,0.0) [0.0|3] ""  Vector__XXX
 SG_ EPS_Lenkerposition : 41|2@1+ (1.0,0.0) [0.0|3] ""  Vector__XXX
 SG_ EPS_Anf_KL : 43|1@1+ (1.0,0.0) [0.0|1] ""  Vector__XXX
 SG_ EPS_ARA_Status : 44|4@1+ (1.0,0.0) [0.0|15] ""  Vector__XXX

BO_ 981 Licht_Anf_01: 8 Gateway
 SG_ Licht_Anf_01_CRC : 0|8@1+ (1,0) [0|255] ""  Kombi_PAG
 SG_ Licht_Anf_01_BZ : 8|4@1+ (1,0) [0|15] ""  Kombi_PAG
 SG_ BCM1_Kurvenlicht_links_Anf : 12|1@1+ (1.0,0.0) [0.0|1] ""  Vector__XXX
 SG_ BCM1_Kurvenlicht_rechts_Anf : 13|1@1+ (1.0,0.0) [0.0|1] ""  Vector__XXX
 SG_ BCM1_Standlicht_Anf : 14|1@1+ (1.0,0.0) [0.0|1] ""  Kombi_PAG
 SG_ BCM1_Abblendlicht_Anf : 15|1@1+ (1.0,0.0) [0.0|1] ""  Kombi_PAG
 SG_ BCM1_Fernlicht_Anf : 16|1@1+ (1.0,0.0) [0.0|1] ""  Vector__XXX
 SG_ BCM1_Nebellicht_Anf : 17|1@1+ (1.0,0.0) [0.0|1] ""  Vector__XXX
 SG_ BCM1_Parklicht_li_Anf : 18|1@1+ (1.0,0.0) [0.0|1] ""  Vector__XXX
 SG_ BCM1_Parklicht_re_Anf : 19|1@1+ (1.0,0.0) [0.0|1] ""  Vector__XXX
 SG_ BCM1_Nebelschluss_Ahg_Anf : 20|1@1+ (1.0,0.0) [0.0|1] ""  Vector__XXX
 SG_ BCM1_Nebelschluss_Fzg_Anf : 21|1@1+ (1.0,0.0) [0.0|1] ""  Kombi
 SG_ BCM1_Schlusslicht_Anf : 22|1@1+ (1.0,0.0) [0.0|1] ""  Kombi
 SG_ BCM_Rueckfahrlicht_Anf : 23|1@1+ (1.0,0.0) [0.0|1] ""  Kombi
 SG_ BCM1_Signaturlicht_Anf : 24|1@1+ (1.0,0.0) [0.0|1] ""  Vector__XXX
 SG_ BCM1_Umfeldleuchten_Anf : 25|1@1+ (1.0,0.0) [0.0|1] ""  Vector__XXX
 SG_ BCM1_Tagfahrlicht_Anf : 26|1@1+ (1.0,0.0) [0.0|1] ""  Kombi
 SG_ BCM1_Regenlicht_Anf : 27|1@1+ (1.0,0.0) [0.0|1] ""  Vector__XXX
 SG_ BCM1_Autobahnlicht_Anf : 28|1@1+ (1.0,0.0) [0.0|1] ""  Vector__XXX
 SG_ BCM1_Touristen_Licht_Anf : 29|1@1+ (1.0,0.0) [0.0|1] ""  Vector__XXX
 SG_ BCM1_CH_aktiv : 30|1@1+ (1.0,0.0) [0.0|1] ""  Vector__XXX
 SG_ BCM1_LH_aktiv : 31|1@1+ (1.0,0.0) [0.0|1] ""  Vector__XXX
 SG_ BCM1_Gleitende_Leuchtw_Anf : 32|1@1+ (1.0,0.0) [0.0|1] ""  Vector__XXX
 SG_ BCM1_GLW_Fernlicht_Anf : 33|1@1+ (1.0,0.0) [0.0|1] ""  Vector__XXX
 SG_ BCM1_Adaptive_Lichtvert_Anf : 34|1@1+ (1.0,0.0) [0.0|1] ""  Vector__XXX
 SG_ BCM1_FoD_Sperrung_WiBli : 35|2@1+ (1.0,0.0) [0.0|3] ""  Vector__XXX
 SG_ BCM1_FOD_Sperrung_Animationen_HL : 37|2@1+ (1.0,0.0) [0.0|3] ""  Vector__XXX
 SG_ BCM1_Animationssperrung : 39|1@1+ (1.0,0.0) [0.0|1] ""  Vector__XXX
 SG_ BCM1_CH_LH_aktiv : 40|1@1+ (1.0,0.0) [0.0|1] ""  Vector__XXX
 SG_ BCM1_Allwetterlicht_Anf : 41|1@1+ (1.0,0.0) [0.0|1] ""  Kombi
 SG_ BCM1_Schlusslicht_Signatur : 60|4@1+ (1.0,0.0) [0.0|15] ""  Vector__XXX

BO_ 982 Licht_hinten_01: 8 Gateway
 SG_ BCM2_Bremsl_durch_ECD : 5|1@1+ (1.0,0.0) [0.0|1] ""  Vector__XXX
 SG_ LH_Aussenlicht_def : 7|1@1+ (1.0,0.0) [0.0|1] ""  Kombi,Kombi_LB,Kombi_PAG
 SG_ LH_Standlicht_H_aktiv : 8|1@1+ (1.0,0.0) [0.0|1] ""  Vector__XXX
 SG_ LH_Parklicht_HL_aktiv : 9|1@1+ (1.0,0.0) [0.0|1] ""  Vector__XXX
 SG_ LH_Parklicht_HR_aktiv : 10|1@1+ (1.0,0.0) [0.0|1] ""  Vector__XXX
 SG_ LH_Bremslicht_H_aktiv : 11|1@1+ (1.0,0.0) [0.0|1] ""  Kombi,Kombi_PAG
 SG_ LH_Nebelschluss_aktiv : 12|1@1+ (1.0,0.0) [0.0|1] ""  Vector__XXX
 SG_ LH_Rueckfahrlicht_aktiv : 13|1@1+ (1.0,0.0) [0.0|1] ""  Vector__XXX
 SG_ LH_Blinker_HL_akt : 14|1@1+ (1.0,0.0) [0.0|1] ""  Vector__XXX
 SG_ LH_Blinker_HR_akt : 15|1@1+ (1.0,0.0) [0.0|1] ""  Kombi,Kombi_LB
 SG_ LH_Blinker_li_def : 16|1@1+ (1.0,0.0) [0.0|1] ""  Kombi,Kombi_LB,Kombi_PAG
 SG_ LH_Bremsl_li_def : 17|1@1+ (1.0,0.0) [0.0|1] ""  Kombi,Kombi_LB,Kombi_PAG
 SG_ LH_Schlusslicht_li_def : 18|1@1+ (1.0,0.0) [0.0|1] ""  Kombi,Kombi_LB,Kombi_PAG
 SG_ LH_Rueckf_li_def : 19|1@1+ (1.0,0.0) [0.0|1] ""  Kombi,Kombi_LB,Kombi_PAG
 SG_ LH_Nebel_li_def : 20|1@1+ (1.0,0.0) [0.0|1] ""  Kombi,Kombi_LB,Kombi_PAG
 SG_ LH_Schluss_Brems_Nebel_li_def : 21|1@1+ (1.0,0.0) [0.0|1] ""  Kombi,Kombi_LB,Kombi_PAG
 SG_ LH_Schluss_Brems_Nebel_re_def : 22|1@1+ (1.0,0.0) [0.0|1] ""  Kombi,Kombi_LB,Kombi_PAG
 SG_ LH_Zusatzschlussl_def : 23|1@1+ (1.0,0.0) [0.0|1] ""  Kombi,Kombi_LB,Kombi_PAG
 SG_ LH_Schluss_Brems_li_def : 24|1@1+ (1.0,0.0) [0.0|1] ""  Kombi,Kombi_LB,Kombi_PAG
 SG_ LH_Schluss_Nebel_li_def : 25|1@1+ (1.0,0.0) [0.0|1] ""  Kombi,Kombi_LB,Kombi_PAG
 SG_ LH_SL_BRL_BLK_li_def : 26|1@1+ (1.0,0.0) [0.0|1] ""  Kombi,Kombi_LB,Kombi_PAG
 SG_ LH_Brems_Blk_li_def : 27|1@1+ (1.0,0.0) [0.0|1] ""  Kombi,Kombi_LB,Kombi_PAG
 SG_ LH_Diag_Status_re_def : 28|1@1+ (1.0,0.0) [0.0|1] ""  Kombi,Kombi_LB,Kombi_PAG
 SG_ LH_Diag_Status_li_def : 29|1@1+ (1.0,0.0) [0.0|1] ""  Kombi,Kombi_LB,Kombi_PAG
 SG_ LH_Diag_LED_li_def : 30|1@1+ (1.0,0.0) [0.0|1] ""  Kombi,Kombi_LB,Kombi_PAG
 SG_ LH_Diag_LED_re_def : 31|1@1+ (1.0,0.0) [0.0|1] ""  Kombi,Kombi_LB,Kombi_PAG
 SG_ LH_Blinker_re_def : 32|1@1+ (1.0,0.0) [0.0|1] ""  Kombi,Kombi_LB,Kombi_PAG
 SG_ LH_Bremsl_re_def : 33|1@1+ (1.0,0.0) [0.0|1] ""  Kombi,Kombi_LB,Kombi_PAG
 SG_ LH_Schlusslicht_re_def : 34|1@1+ (1.0,0.0) [0.0|1] ""  Kombi,Kombi_LB,Kombi_PAG
 SG_ LH_Rueckf_re_def : 35|1@1+ (1.0,0.0) [0.0|1] ""  Kombi,Kombi_LB,Kombi_PAG
 SG_ LH_Nebel_re_def : 36|1@1+ (1.0,0.0) [0.0|1] ""  Kombi,Kombi_LB,Kombi_PAG
 SG_ LH_Schluss_Brems_mi_def : 37|1@1+ (1.0,0.0) [0.0|1] ""  Kombi,Kombi_LB
 SG_ LH_Schluss_Brems_re_def : 40|1@1+ (1.0,0.0) [0.0|1] ""  Kombi,Kombi_LB,Kombi_PAG
 SG_ LH_Schluss_Nebel_re_def : 41|1@1+ (1.0,0.0) [0.0|1] ""  Kombi,Kombi_LB,Kombi_PAG
 SG_ LH_SL_BRL_BLK_re_def : 42|1@1+ (1.0,0.0) [0.0|1] ""  Kombi,Kombi_LB,Kombi_PAG
 SG_ LH_Brems_Blk_re_def : 43|1@1+ (1.0,0.0) [0.0|1] ""  Kombi,Kombi_LB,Kombi_PAG
 SG_ LH_Kennzl_def : 48|1@1+ (1.0,0.0) [0.0|1] ""  Kombi,Kombi_LB,Kombi_PAG
 SG_ LH_3_Bremsl_def : 49|1@1+ (1.0,0.0) [0.0|1] ""  Kombi,Kombi_LB,Kombi_PAG
 SG_ LH_Nebel_mi_def : 50|1@1+ (1.0,0.0) [0.0|1] ""  Kombi,Kombi_LB,Kombi_PAG
 SG_ LH_Rueckf_mi_def : 51|1@1+ (1.0,0.0) [0.0|1] ""  Kombi,Kombi_LB,Kombi_PAG
 SG_ LH_Schlusslicht_mi_def : 52|1@1+ (1.0,0.0) [0.0|1] ""  Kombi,Kombi_LB
 SG_ LH_Bremsl_mi_def : 53|1@1+ (1.0,0.0) [0.0|1] ""  Kombi,Kombi_LB
 SG_ LH_Bremsl_li_ges_def : 54|1@1+ (1.0,0.0) [0.0|1] ""  Kombi,Kombi_LB,Kombi_PAG
 SG_ LH_Bremsl_re_ges_def : 55|1@1+ (1.0,0.0) [0.0|1] ""  Kombi,Kombi_LB,Kombi_PAG

BO_TX_BU_ 1640 :Gateway,Gateway_PAG;
BO_TX_BU_ 2463978701 :Gateway,Gateway_PAG;
BO_TX_BU_ 1505 :Gateway,Gateway_PAG;
BO_TX_BU_ 2549088272 :Gateway,Gateway_PAG;
BO_TX_BU_ 2549088276 :Kombi,Kombi_LB,Kombi_PAG;
BO_TX_BU_ 2549088339 :CGS,Waehlhebel_SB;
BO_TX_BU_ 779 :Kombi,Kombi_LB,Kombi_PAG;
BO_TX_BU_ 1719 :Kombi,Kombi_LB,Kombi_PAG;
BO_TX_BU_ 1720 :Kombi,Kombi_LB,Kombi_PAG;
BO_TX_BU_ 1724 :Kombi,Kombi_LB,Kombi_PAG;
BO_TX_BU_ 2589283471 :Kombi,Kombi_LB,Kombi_PAG;
BO_TX_BU_ 2527679638 :Kombi,Kombi_PAG;
BO_TX_BU_ 2527679639 :Kombi,Kombi_PAG;
BO_TX_BU_ 2589283631 :Kombi,Kombi_LB,Kombi_PAG;
BO_TX_BU_ 2527679656 :Kombi,Kombi_LB,Kombi_PAG;
BO_TX_BU_ 1614 :Kombi,Kombi_PAG;
BO_TX_BU_ 2549874964 :Gateway,Gateway_PAG;
BO_TX_BU_ 2550006036 :Kombi,Kombi_LB,Kombi_PAG;
BO_TX_BU_ 2589283974 :Gateway,Gateway_PAG;
BO_TX_BU_ 919 :Gateway,Gateway_PAG;
BO_TX_BU_ 810 :Gateway,Gateway_PAG;
BO_TX_BU_ 981 :Gateway,Gateway_PAG;
BO_TX_BU_ 982 :Gateway,Gateway_PAG;
CM_ BO_ 1640 "ab MQB IS-4";
CM_ BO_ 1505 "ab MQB 7.3";
CM_ BO_ 779 "MQB";
CM_ BO_ 919 "ab MQB ohne CHK/BZ, LDW_SW_Warnung_links/rechts, KD-Fehler und mit Zyklus 100ms";
CM_ BO_ 810 "MQB: 50ms (für CAN-SG), geändertes Charisma, Entfall KD-Fehler";
CM_ BO_ 982 "MQB";

CM_ SG_ 1640 FSH_Taster "Tasterbetätigung Frontscheibenheizung
";
CM_ SG_ 1640 HSH_Taster "An-/Abforderung Heckscheibenheizung über spezielles Tastersignal
";
CM_ SG_ 1640 KL_Beschlagsgefahr "Beschlagsgefahr auf der Frontscheibe im Bereich des Spiegelfusses. Dient zur präventiven Ansteuerung der  Kamera-Scheibenheizung, um Kamera-Blindheit zu vermeiden
PHEV: volle Leistungsfreigabe 
HV Heizer und HV EKK bei Scheibenbeschlag ";
CM_ SG_ 1640 KL_Geblspng_Fond_Soll "Ausgabe des Sollwertes für die Spannung des Klimagebläsemotores hinten.






";
CM_ SG_ 1640 KL_Geblspng_Soll "Ausgabe des Sollwertes für die Spannung des Klimagebläsemotores vorne.







";
CM_ SG_ 1640 KL_I_Geblaese "Stromaufnahme Gebläse";
CM_ SG_ 1640 KL_Kompressorstrom_soll "Sollvorgabe Klima-Kompressorstrom";
CM_ SG_ 1640 KL_LRH_Stufe "Eingestellte Temperaturstufe der Lenkradheizung";
CM_ SG_ 1640 KL_LRH_Taster "Tasterbetätigung Lenkradheizung";
CM_ SG_ 1640 KL_PTC_Verbauinfo "Im Klima- bzw. Heizungsbedienteil wird der Verbau eines PTCs und dessen elektr. Leistungsklasse codiert";
CM_ SG_ 1640 KL_SIH_Soll_li "Einstellung Sitzheizung Fahrer (0...6)";
CM_ SG_ 1640 KL_SIH_Soll_re "Einstellung Sitzheizung Beifahrer (0...6)";
CM_ SG_ 1640 KL_SIL_Soll_li "Einstellung Sitzlüftung Fahrer (0...6)";
CM_ SG_ 1640 KL_SIL_Soll_re "Einstellung Sitzlüftung Beifahrer (0...6)";
CM_ SG_ 1640 KL_Umluftklappe_Status "Status Umluftklappe";
CM_ SG_ 1640 KL_Zuheizer_Freigabe "Freigabe Zuheizer
";
CM_ SG_ 1640 KRH_Soll_li "Ausgabe des Sollwertes für die Kopfraumheizung links.";
CM_ SG_ 1640 KRH_Soll_re "Ausgabe des Sollwertes für die Kopfraumheizung rechts.";

CM_ SG_ 2463978701 KL_AC_Schalter_Prognose "Erwarteter Zustand des Klimakompressorwunschs bei einem Fahrprogramm-Wechsel";
CM_ SG_ 2463978701 KL_Leistungsreduktions_Hinweis "Signal zum Auslösen der Kombi-Meldung das bei einem Klima Defizit die Leistung der Klimatisierung reduziert wird.";
CM_ SG_ 2463978701 KL_Sollklimamodus_FPR_1 "Ziel Modus der Klimatisierung für ein definierbares Fahrprogramm.";
CM_ SG_ 2463978701 KL_Sollklimamodus_FPR_2 "Ziel Modus der Klimatisierung für ein definierbares Fahrprogramm.";
CM_ SG_ 2463978701 KL_Sollklimamodus_FPR_3 "Ziel Modus der Klimatisierung für ein definierbares Fahrprogramm.";
CM_ SG_ 2463978701 KL_Temp_Soll_hl_Prognose "Solltemperatur (Kundenwunsch) für die Prognose bei einem Fahrprogrammwechsel im BEV";
CM_ SG_ 2463978701 KL_Temp_Soll_hr_Prognose "Solltemperatur hinten rechts (Kundenwunsch) für die Prognose bei einem Fahrprogrammwechsel im BEV";
CM_ SG_ 2463978701 KL_Temp_Soll_vl_Prognose "Solltemperatur vorne links (Kundenwunsch) für die Prognose bei einem Fahrprogrammwechsel im BEV";
CM_ SG_ 2463978701 KL_Temp_Soll_vr_Prognose "Solltemperatur vorne rechts (Kundenwunsch) für die Prognose bei einem Fahrprogrammwechsel im BEV";

CM_ SG_ 1505 BCM1_Aussen_Temp_ungef "ungefilterter Wert des Aussentemperatursensors
";
CM_ SG_ 1505 BCM1_FStatus_Aussentemp_ungef "Fehlerstatus für Aussentemperatur (Kombianzeige)";
CM_ SG_ 1505 BCM1_Kompressorstrom_ist "IST-Strom vom Klima-Kompressor";
CM_ SG_ 1505 BCM1_OBD_FStatus_ATemp "Fehlerstatus Umgebungstemperatursensor (OBD relevanter Sensor)
";
CM_ SG_ 1505 BCM1_PTC_stufig_Status "Status des BCM1-Heizverbrauchers PTC (stufig)";
CM_ SG_ 1505 BCM_Heizungsabsperrventil_Status "Das Signal beschreibt den Zustand des Heizungsabsperrventils, welches als Portexpander vom BCM1 elektrisch angesteuert wird.";
CM_ SG_ 1505 BCM_Heizungspumpe_Status "Das Signal beschreibt den Zustand der Heizungspumpe, welche als Portexpander vom BCM1 elektrisch angesteuert wird.";
CM_ SG_ 1505 BCM_Kompressorkupplung_Status "Das Signal beschreibt den Zustand der Klimakompressorkupplung, welche als Portexpander vom BCM1 elektrisch angesteuert wird.";

CM_ SG_ 2549088272 Gateway_Abschaltstufe "Funktionseinschränkung aufgrund aktiver Abschaltstufe";
CM_ SG_ 2549088272 Gateway_KompSchutz "Funktionseinschränkung aufgrund Komponentenschutz aktiv";
CM_ SG_ 2549088272 Gateway_Matrix_Generation "Signal gibt an welche Matrix-Generation umgesetzt ist";
CM_ SG_ 2549088272 Gateway_Matrix_Version "Signal gibt an welche Matrix-Version des Baukasten umgesetzt ist.
z.B. V.08.xx, das Signal gibt den Wert für xx an";
CM_ SG_ 2549088272 Gateway_Nachlauftyp "Abgebildet wird die von der Hardware vorgegebene Möglichkeit, die Kommunikation nach Klemme 15 = AUS aufrecht zu erhalten. Es wird ein Init-Wert gesendet.";
CM_ SG_ 2549088272 Gateway_SNI "Das Signal beinhaltet den Source Node Identifier (Knotenadresse, die auch in der Abbildungsvorschrift zur CAN-ID für die NM-High Botschaft verwendet wird).";
CM_ SG_ 2549088272 Gateway_Transport_Mode "Funktionseinschränkung aufgrund aktivem Transport Mode und/oder Transport Schutz";
CM_ SG_ 2549088272 GW_KD_Fehler "Kundendienstfehlerbit Gateway zur Anzeige eines im Gateway abgelegten Fehlerspeichereintrages.";
CM_ SG_ 2549088272 NM_Gateway_Lokalaktiv "Zeigt an ob das SG nach Klemme15 AUS und nach entsprechender MAX Aktivzeit noch aktiv war.";
CM_ SG_ 2549088272 NM_Gateway_Subsystemaktiv "Zeigt an ob ein Subsystem des SGs nach Klemme15 AUS und nach entsprechender MAX Aktivzeit noch aktiv war";
CM_ SG_ 2549088272 NM_Gateway_Wakeup "enthält die Weckursache; stehen mehrere Weckursachen parallel an, dann muss der kleinste Wert übertragen werden";

CM_ SG_ 2549088283 HUD_Abschaltstufe "Funktionseinschränkung aufgrund aktiver Abschaltstufe";
CM_ SG_ 2549088283 HUD_KD_Fehler "Bei gesetztem Bit ist mindestens ein Kundendienstfehler eingetragen";
CM_ SG_ 2549088283 HUD_KompSchutz "Funktionseinschränkung aufgrund Komponentenschutz aktiv";
CM_ SG_ 2549088283 HUD_Nachlauftyp "Abgebildet wird die von der Hardware vorgegebene Möglichkeit, die Kommunikation nach Klemme 15 = AUS aufrecht zu erhalten. Es wird ein Init-Wert gesendet.";
CM_ SG_ 2549088283 HUD_SNI "Source Node-Identifier (SNI) identifiziert den Sender der NM-Botschaft (Knotenadresse) eindeutig im Fahrzeug";
CM_ SG_ 2549088283 HUD_Transport_Mode "Funktionseinschränkung aufgrund aktivem Transport Mode und/oder Transport Schutz
";
CM_ SG_ 2549088283 KN_HUD_BusKnockOut "Ausgabe des BusKnockout-Status";
CM_ SG_ 2549088283 KN_HUD_BusKnockOutTimer "Ausgabe des BusKnockOut-Timer";
CM_ SG_ 2549088283 KN_HUD_ECUKnockOut "Ausgabe des ECUKnockout-Status";
CM_ SG_ 2549088283 KN_HUD_ECUKnockOutTimer "Ausgabe des ECUKnockOut-Timer";
CM_ SG_ 2549088283 NM_HUD_Lokalaktiv "Zeigt an ob das SG nach Klemme15 AUS und nach entsprechender MAX Aktivzeit noch aktiv war.";
CM_ SG_ 2549088283 NM_HUD_Subsystemaktiv "Zeigt an ob ein Subsystem des SGs nach Klemme15 AUS und nach entsprechender MAX Aktivzeit noch aktiv war";
CM_ SG_ 2549088283 NM_HUD_Wakeup "enthält die Weckursache; stehen mehrere Weckursachen parallel an, dann muss der kleinste Wert übertragen werden";

CM_ SG_ 2549088276 KN_Kombi_BusKnockOut "Ausgabe des BusKnockout-Status in der Knotenbotschaft";
CM_ SG_ 2549088276 KN_Kombi_BusKnockOutTimer "Ausgabe des BusKnockOut-Timer in der Knotenbotschaft";
CM_ SG_ 2549088276 KN_Kombi_ECUKnockOut "Ausgabe des ECUKnockout-Status in der Knotenbotschaft";
CM_ SG_ 2549088276 KN_Kombi_ECUKnockOutTimer "Ausgabe des ECUKnockOut-Timer in der Knotenbotschaft";
CM_ SG_ 2549088276 Kombi_Abschaltstufe "Funktionseinschränkung aufgrund aktiver Abschaltstufe";
CM_ SG_ 2549088276 Kombi_KompSchutz "Funktionseinschränkung aufgrund Komponentenschutz aktiv";
CM_ SG_ 2549088276 Kombi_Nachlauftyp "Abgebildet wird die von der Hardware vorgegebene Möglichkeit, die Kommunikation nach Klemme 15 = AUS aufrecht zu erhalten. Es wird ein Init-Wert gesendet.";
CM_ SG_ 2549088276 Kombi_SNI "Das Signal beinhaltet den Source Node Identifier (Knotenadresse, die auch in der Abbildungsvorschrift zur CAN-ID für die NM-High Botschaft verwendet wird).";
CM_ SG_ 2549088276 Kombi_Transport_Mode "Funktionseinschränkung aufgrund aktivem Transport Mode und/oder Transport Schutz";
CM_ SG_ 2549088276 NM_Kombi_Lokalaktiv "Zeigt an ob das SG nach Klemme15 AUS und nach entsprechender MAX Aktivzeit noch aktiv war";
CM_ SG_ 2549088276 NM_Kombi_Subsystemaktiv "Zeigt an ob ein Subsystem des SGs nach Klemme15 AUS und nach entsprechender MAX Aktivzeit noch aktiv war";
CM_ SG_ 2549088276 NM_Kombi_Wakeup "enthält die Weckursache; stehen mehrere Weckursachen parallel an, dann muss der kleinste Wert übertragen werden";

CM_ SG_ 2549088339 KN_Waehlhebel_BusKnockOutTimer "Ausgabe des BusKnockOut-Timer";
CM_ SG_ 2549088339 NM_Waehlhebel_Lokalaktiv "Zeigt an ob das SG nach Klemme15 AUS und nach entsprechender MAX Aktivzeit noch aktiv war.";
CM_ SG_ 2549088339 NM_Waehlhebel_Subsystemaktiv "Zeigt an ob ein Subsystem des SGs nach Klemme15 AUS und nach entsprechender MAX Aktivzeit noch aktiv war";
CM_ SG_ 2549088339 NM_Waehlhebel_Wakeup "enthält die Weckursache; stehen mehrere Weckursachen parallel an, dann muss der kleinste Wert übertragen werden";
CM_ SG_ 2549088339 Waehlhebel_Abschaltstufe "Funktionseinschränkung aufgrund aktiver Abschaltstufe";
CM_ SG_ 2549088339 Waehlhebel_KompSchutz "Funktionseinschränkung aufgrund Komponentenschutz aktiv";
CM_ SG_ 2549088339 Waehlhebel_Nachlauftyp "Abgebildet wird die von der Hardware vorgegebene Möglichkeit, die Kommunikation nach Klemme 15 = AUS aufrecht zu erhalten. Es wird ein Init-Wert gesendet.";
CM_ SG_ 2549088339 Waehlhebel_SNI "Source Node-Identifier (SNI) identifiziert den Sender der NM-Botschaft (Knotenadresse) eindeutig im Fahrzeug";
CM_ SG_ 2549088339 Waehlhebel_Transport_Mode "Funktionseinschränkung aufgrund aktivem Transport Mode und/oder Transport Schutz";
CM_ SG_ 2549088339 WH_KD_Fehler "Wählhebel-SG Status Kundendienstfehlerspeichereinträge
";

CM_ SG_ 779 KBI_ABS_Lampe "ABS-Sicherheits-Lampe wurde eingeschaltet.";
CM_ SG_ 779 KBI_Airbag_Lampe "Airbag Sicherheits-Lampe wurde eingeschaltet ";
CM_ SG_ 779 KBI_angez_Geschw "Im Tacho angezeigte Geschwindigkeit inklusive der Voreilung

";
CM_ SG_ 779 KBI_Anzeigefehler_NV "Über dieses Signal teilt das Kombiinstrument dem Nightvision-Steuergerät mit, dass ein Fehler vom Kombiinstrument diagnostiziert wurde, der zur Abschaltung der Nightvision-Funktion führen muss.";
CM_ SG_ 779 KBI_Anzeigefehler_SWA "Signal bezieht sich nur auf die SWA-Lampe, Vorhalt für Kombis mit SWA-Lampe. ";
CM_ SG_ 779 KBI_Anzeigestatus_ACC "Status der ACC-Anzeige im nicht permanenten Displaybereich";
CM_ SG_ 779 KBI_Anzeigestatus_GRA "Anzeigestatus der GRA High Wunschgeschwindigkeitsanzeige im Kombiinstrument.
Bei VW bedeutet 'nicht vorhanden' GRA-low fähig (LED immer verbaut).
0 = nicht vorhanden
1 = Wunschgeschwindigkeits-Anzeigemöglichkeit vorhanden
2 = reserviert
3 = Fehler (B";
CM_ SG_ 779 KBI_Anzeigestatus_LIM "Anzeigestatus der Speedlimiter Wunschgeschwindigkeitsanzeige im Kombiinstrument (permanenter Anzeigebereich)
0 = nicht vorhanden
1 = Wunschgeschwindigkeits-Anzeigemöglichkeit vorhanden
2 = reserviert
3 = Fehler (Botschaftsüberwachung, Timeout, Akustik";
CM_ SG_ 779 KBI_ARA_in_Anzeige "Anzeige von ARA im Kombi aktiv";
CM_ SG_ 779 KBI_Bestaetigung_ESP_Off "ESP Off Bestätigung vom Kombi ans ESC";
CM_ SG_ 779 KBI_BKL_Lampe "Sicherheits-Lampe Bremskontrolle wurde eingeschaltet;
";
CM_ SG_ 779 KBI_Einheit_Tacho "Information, ob es sich um Meilen- oder Kmh-Kombi handelt, Einheit des Tachos entspricht dem Zifferblatt, Grösse ist nicht veränderlich";
CM_ SG_ 779 KBI_ESP_Lampe "ESP-Sicherheits-Lampe wurde eingeschaltet ";
CM_ SG_ 779 KBI_Fehler_Anzeige_ACC "Rückmeldung an ACC, dass mindestens eine der ACC-relevanten Anzeigen -rote Fahrerübernahme, Mitteldisplay, Gong - fehlerhaft sind.";
CM_ SG_ 779 KBI_GRA_Hauptschalter "Hauptschalter der Fahrerassistenzsysteme basierend auf dem FAS-Menu im Kombi.";
CM_ SG_ 779 KBI_Handbremse "Handbremsen-Information vom Kombi.
Das Signal bezieht sich ausschließlich auf den Zustand der konventionellen Handbremse.";
CM_ SG_ 779 KBI_im_Stellgliedtest "Kombi im Stellgliedtest, Signal muss eingelesen werden, um Fehlfunktion aufgrund der Bewegung der Stellglieder (Drehzahlmesser, Tacho) des Kombis zu verhindern";
CM_ SG_ 779 KBI_Konsistenz_ACC "Rückmeldung an ACC, dass die Botschaften zur Ansteuerung von Anzeigen nicht bzw. nicht konsistent empfangen wurden (Timeout-, BZ-, CHK- und DLC-Fehler)                                                                                                        ";
CM_ SG_ 779 KBI_Lenkung_Lampe "Sicherheits-Lampe der Lenkung (Lenkhilfe EPS, Audi-Dynamic-Steering ...) wurde eingeschaltet.

0x0 = Lenkungs-Lampe aus
0x1 = Lenkungs-Lampe ein";
CM_ SG_ 779 KBI_MFA_v_Einheit_01 "Einheit der Geschwindigkeit, die vom Fahrer im Car-Menü gewählt wurde. Veränderliche Grösse, im Gegensatz zur Einheit des Tachokranzes.";
CM_ SG_ 779 KBI_NV_in_Anzeige "Das Bit gibt dem NV die Information, ob NV-Bild im Kombi in der Anzeige ist. (Information ist notwendig um Kontrasverstellungen nur dann zuzulassen, wenn der Fahrer das Feedback über das  Kombidisplay bekommt.)";
CM_ SG_ 779 KBI_PLA_in_Anzeige "Das Signal wird als aktive Rückmeldung genutzt, ob die Info des PLA im Kombi angezeigt wird. Wenn nach Anforderung des Displays das Signal zweimal auf 0 ist, wird der Parkvorgang abgebrochen.
Ein Kombi, dass PLA Anzeige nicht unterstützt, schickt dauerha";
CM_ SG_ 779 KBI_SILA_gueltig "Rückmeldeinformation (Bit 1-6) ist gültig";
CM_ SG_ 779 KBI_Systemstatus "Signalisiert erkannte FuSi-relevante Fehler im Kombi
(keinen Ausfall der Akustik oder des Displays)";
CM_ SG_ 779 KBI_Tankwarnung "Fahrer wird gewarnt, dass er den Reservebereich erreicht hat. Fzg.spezifische Warnschwelle";
CM_ SG_ 779 KBI_Tankwarnung_ungueltig "Validiert den Inhalt des Signales KBI_Tankwarnung";
CM_ SG_ 779 KBI_Taster_Fahrwerk "Betätigung Taster 'Fahrwerk' im Kombi";
CM_ SG_ 779 KBI_Taster_Lift "Betätigung Taster 'Lift' im Kombi J1 zur Verarbeitung im Porsche EFP Steuergerät";
CM_ SG_ 779 KBI_V_Digital "Ausgabe der im Kombi angezeigten digitalen Geschwindigkeit.

Einheit ist im KBI_MFA_v_Einheit_01 definiert";
CM_ SG_ 779 KBI_Vorglueh_System_Lampe "Rückmeldung der Vorglühlampe bzw. Motor Systemlampe (MO_Systemlampe) an den Motor (bei Diesel und Otto!). Hardwaremässig gleiche LED im Kombi (EPC- oder Glühwendel), Unterscheidung nur über Ziffernblatt.";

CM_ SG_ 1719 KBI_aktive_Laengsfunktion "Auswahl, der vom Fahrer gewünschten Laengsregelfunktion";
CM_ SG_ 1719 KBI_FoD_PopUP_Quittiert "Angezeigte FoD-Warnung im Kombi wurde vom Fahrer quittiert; 
Signal wird für die Dauer von 2 Sekunden gesendet";
CM_ SG_ 1719 KBI_FStatus_Tank "Signal wird gesetzt:

a) Während der Fehlerentprellzeit (20 s Entprellung)

b) Bei erkanntem Fehler wird der Tankinhalt während der laufenden KL15-Phase über den 
    Verbrauch zurückgerechnet. In dieser Zeit ist das Bit ebenfalls gesetzt. Nach einem";
CM_ SG_ 1719 KBI_GRA_im_ACC "Gibt den vom Fahrer ausgewählten Modus (ACC oder GRA_im_ACC) an.";
CM_ SG_ 1719 KBI_Inhalt_Tank "Restmenge 2 bzw. 2,5l nicht auflösbar

";
CM_ SG_ 1719 KBI_Kilometerstand "Fehler wird ausgegeben, falls Kilometerstand nicht restaurierbar
";
CM_ SG_ 1719 KBI_LVDS_Lock "Dient zur Synchronisation der Anzeige zwischen Kombi und ZR";
CM_ SG_ 1719 KBI_Oelwechsel_durchgefuehrt "Nach einen Ölwechsel (Service) ist die Ethanol Warmfahrwarnung zu unterdrücken.";
CM_ SG_ 1719 KBI_QBit_Aussen_Temp_gef "0x0 = gültiger Wert
0x1 = Ersatz-, Init- oder Fehlerwert";
CM_ SG_ 1719 KBI_RDK_Kalibrier_Anf "Bei gesetztem Bit soll die RDK die aktuellen Istdrücke zu Solldrücken übernehmen (nur bei Nichtverbau einer Headunit erforderlich).";
CM_ SG_ 1719 KBI_Reserve_Warnung_Sek "Signalisiert die Reservewarnung für die Energiespeicher CNG, LPG, HV-Batterie.
Fahrer wird gewarnt, dass er den Reservebereich erreicht hat. Fzg.spezifische Warnschwelle.";
CM_ SG_ 1719 KBI_Standzeit_02 "Zähler welcher die Standzeit des Motors wiedergibt.
Das Signal beschreibt den Anteil der Motor-Standzeit zwischen Zündung aus und nächstem Motorstart.";
CM_ SG_ 1719 KBI_TA_gewaehlt_Fahrer "Rueckmeldung, dass der TA vom Fahrer gewaehlt wurde";

CM_ SG_ 1720 KBI_BCmE_aktiv "Anzeige BCmE aktiv (BCmE-Screen oder Einsparhinweis in der Anzeige)";
CM_ SG_ 1720 KBI_GAP_Warn_Zeit_abgelaufen "Die Zeit, z.B. 1460 Tage, bis zur finalen Warnstufe der Gasanlagenprüfung wurde berechnet. Berechnung erfolgt auf Basis der aktuellen Uhrzeit mit einem Tageszähler. Keine Berechnung des Zählers bei Kl.30 AUS.";
CM_ SG_ 1720 KBI_Max_Tankinhalt "Mitteilung des maximalen Tankinhalts an das Reichweitenmodul";
CM_ SG_ 1720 KBI_Nachtanken_erkannt "Statusinformation Nachtankmodus";
CM_ SG_ 1720 KBI_Quittierung_cAQP "Quittierungsbestätigung vom Fahrer für Funktion cAQP";
CM_ SG_ 1720 KBI_Quittierung_Naesse "Quittierungsbestätigung vom Fahrer";
CM_ SG_ 1720 KBI_Reifenumfang "Mittlerer Radumfang aus der K-Zahl gerechnet in Millimeter.  Byte 2 Bit 5,4 reserviert, Byte 2 Bit 3..0 und Byte 1 Bit 7..0; Wertebereich 0..4096 mm
";
CM_ SG_ 1720 KBI_Reifenumfang_Sekundaer "Fahrzeuge mit unterschiedlichen Reifenumfängen Vorderachse / Hinterachse:

Primärachse: KBI_Reifenumfang
Sekundärachse: KBI_Reifenumfang_Sekundaer
";
CM_ SG_ 1720 KBI_Sparhinweis_quittiert "angezeigter Sparhinweis ist quittiert. Signal wird nach zwei Sendebotschaften wieder auf '0' gesetzt.";
CM_ SG_ 1720 KBI_Tankfuellstand_Prozent "Tankfüllstand in %";
CM_ SG_ 1720 KBI_Tankinhalt_hochaufl "angezeigter Tankinhalt hochauflösend zur Restreichweitenberechnung";
CM_ SG_ 1720 KBI_Variante "Zeigt an ob es sich um ein konventionelles Zeiger-Kombiinstrument handelt oder um eine Volldisplay-Kombiinstrument";
CM_ SG_ 1720 KBI_Variante_USA "In diesem Signal wird die HW-Variante des Kombis ausgegeben, ACC plausibilisiert auf dieses Signal hin seine US-Codierung";

CM_ SG_ 1724 KBI_Insp_dis "Distanz bis zur Inspektion:

Einheitenloser Wert. Einheit im Signal 'KBI_Inspection_distance_unit'";
CM_ SG_ 1724 KBI_Insp_dis_status "Einheit Distanz bis zur Inspektion:";
CM_ SG_ 1724 KBI_Insp_dis_unit "Einheit Distanz bis zur Inspektion:";
CM_ SG_ 1724 KBI_Insp_time "Zeit bis zur Inspektion:

Angabe in Tagen";
CM_ SG_ 1724 KBI_Insp_time_status "Inspektionsstatus Zeit:";
CM_ SG_ 1724 KBI_Oil_dis "Distanz bis zum Ölwechsel:

Einheitenloser Wert. Einheit im Signal 'KBI_Oil_distance_unit'";
CM_ SG_ 1724 KBI_Oil_dis_status "Ölwechselstatus Distanz:";
CM_ SG_ 1724 KBI_Oil_dis_unit "Einheit Distanz bis zum Ölwechsel:";
CM_ SG_ 1724 KBI_Oil_time "Zeit bis zum Ölwechsel:

Angabe in Tagen";
CM_ SG_ 1724 KBI_Oil_time_status "Ölwechselstatus Zeit:";
CM_ SG_ 1724 KBI_Warnung_ID "ID, die einer Warnung im Kombi entspricht und entsprechend der Anzeige im Kombi gesetzt wird.";

CM_ SG_ 2589283471 KBI_Signatur_Wegstrecke_01 "Signatur_01 der Wegstreckendaten des Kombiinstruments";
CM_ SG_ 2589283471 KBI_Signatur_Wegstrecke_02 "Signatur_02 der Wegstreckendaten des Kombiinstruments";
CM_ SG_ 2589283471 KBI_Status_Aktive_Meldungen "Signalisiert im Kombi eine Änderung im Servicekey 3 Messwerteblock für aktive Meldungen  ";
CM_ SG_ 2589283471 KBI_Status_Historie_Meldungen "Signalisiert im Kombi eine Änderung im Servicekey 3 Messwerteblock für Historie Meldungen  ";
CM_ SG_ 2589283471 KBI_Status_SK_Meldungen "Signalisiert im Kombi eine Änderung im Servicekey 3 Messwerteblock für Servicekey Meldungen  ";
CM_ SG_ 2589283471 KBI_Wegstrecke "Kilometerstand des Kombis zu Wegstreckensicherheitszwecken";

CM_ SG_ 2527679638 KBI_GZeit_HSek "Stoppuhr-Gesamtzeit laufend - 1/100 Sekunden


PAG-Plattform:
Sendeart: Cyclic
Zykluszeit: 20ms

MLBevo_Konzern:
Sendeart: OnChange
Zykluszeit: 1000ms
Inhibitzeit: 100ms";
CM_ SG_ 2527679638 KBI_GZeit_Min "Stoppuhr-Gesamtzeit laufend Minuten

PAG-Plattform:
Sendeart: Cyclic
Zykluszeit: 20ms

MLBevo_Konzern:
Sendeart: OnChange
Zykluszeit: 1000ms
Inhibitzeit: 100ms";
CM_ SG_ 2527679638 KBI_GZeit_Sek "Stoppuhr-Gesamtzeit laufend - Sekunden

PAG-Plattform:
Sendeart: Cyclic
Zykluszeit: 20ms

MLBevo_Konzern:
Sendeart: OnChange
Zykluszeit: 1000ms
Inhibitzeit: 100ms";
CM_ SG_ 2527679638 KBI_GZeit_Std "Stoppuhr-Gesamtzeit laufend - Stunden

PAG-Plattform:
Sendeart: Cyclic
Zykluszeit: 20ms

MLBevo_Konzern:
Sendeart: OnChange
Zykluszeit: 1000ms
Inhibitzeit: 100ms
";
CM_ SG_ 2527679638 KBI_RZ_Nr "Nr. der aktuellen Runde

PAG-Plattform:
Sendeart: Cyclic
Zykluszeit: 250ms

MLBevo_Konzern:
Sendeart: OnChange
Zykluszeit: 1000ms
Inhibitzeit: 100ms";
CM_ SG_ 2527679638 KBI_RZeit_HSek "Stoppuhr -Rundenzeit - 1/100 Sekunden

PAG-Plattform:
Sendeart: Cyclic
Zykluszeit: 250ms

MLBevo_Konzern:
Sendeart: OnChange
Zykluszeit: 1000ms
Inhibitzeit: 100ms
";
CM_ SG_ 2527679638 KBI_RZeit_Min "Stoppuhr - Rundenzeit - Minuten

PAG-Plattform:
Sendeart: Cyclic
Zykluszeit: 250ms

MLBevo_Konzern:
Sendeart: OnChange
Zykluszeit: 1000ms
Inhibitzeit: 100ms
";
CM_ SG_ 2527679638 KBI_RZeit_Sek "Stoppuhr - Rundenzeit - Sekunden

PAG-Plattform:
Sendeart: Cyclic
Zykluszeit: 250ms

MLBevo_Konzern:
Sendeart: OnChange
Zykluszeit: 1000ms
Inhibitzeit: 100ms";
CM_ SG_ 2527679638 KBI_RZeit_Std "Stoppuhr - Rundenzeit - Stunden

PAG-Plattform:
Sendeart: Cyclic
Zykluszeit: 250ms

MLBevo_Konzern:
Sendeart: OnChange
Zykluszeit: 1000ms
Inhibitzeit: 100ms
";
CM_ SG_ 2527679638 KBI_Status_StoppUhr "This signal contains the status of the laptimer.";

CM_ SG_ 2527679639 KBI_Jokerkey "Betaetigung KBI Jokertaste";
CM_ SG_ 2527679639 KBI_RS_Druck_uebernehmen "Druck für Rundstreckenmodus übernehmen";
CM_ SG_ 2527679639 KBI_RS_Druckauswahl_Aktiv "Menue Druckauswahl aktiv";
CM_ SG_ 2527679639 KBI_RS_Mode_fortsetzen "Kombi fordert Fortsetzung des Rundstreckenmodus";
CM_ SG_ 2527679639 KBI_Rundstreckenmodus "Rundstreckenmodus Anforderung";
CM_ SG_ 2527679639 KBI_Weg_Zaehler "Inkrementaler Zähler des Kombis

PAG-Plattform:
Sendeart: Cyclic
Zykluszeit: 100ms

MLBevo_Konzern:
Sendeart: OnChange
Zykluszeit: 1000ms
Inhibitzeit: 100ms
";
CM_ SG_ 2527679639 KBI_Weg_Zaehler_F "Fehlerbit für den Inkrementalzähler Weg

PAG-Plattform:
Sendeart: Cyclic
Zykluszeit: 100ms

MLBevo_Konzern:
Sendeart: OnChange
Zykluszeit: 1000ms
Inhibitzeit: 100ms";

CM_ SG_ 2589283631 KBI_BC_Reset_E1 "Signalisierung BC Reset. Bei jedem BC Reset wird um 1 hochgezaehlt, bei 0x6 erfolgt Ueberlauf auf 0x1. Bei SG-Reset und Datenverlust vom BC wird der Wert SG_Reset angenommen. Während der Init-Phase wird Init gesendet, nach der Init-Phase der letzte gültig";
CM_ SG_ 2589283631 KBI_BC_Reset_E2 "Signalisierung BC Reset. Bei jedem BC Reset wird um 1 hochgezaehlt, 
bei 0x6 erfolgt Ueberlauf auf 0x1. Bei SG-Reset und Datenverlust vom 
BC wird der Wert SG_Reset angenommen. Während der Init-Phase wird Init gesendet, nach der Init-Phase der letzte gü";
CM_ SG_ 2589283631 KBI_BC_Reset_E3 "Signalisierung BC Reset. Bei jedem BC Reset wird um 1 hochgezaehlt, 
bei 0x6 erfolgt Ueberlauf auf 0x1. Bei SG-Reset und Datenverlust vom 
BC wird der Wert SG_Reset angenommen. Während der Init-Phase wird Init gesendet, nach der Init-Phase der letzte gü";
CM_ SG_ 2589283631 KBI_Kilometerstand_HiRes "Aufgrund gesetzlicher Anforderung muß Motor-SG den Kilometerstand an GST Mode$01 ausgeben.
Vgl. SAEJ1979 Festlegung zum PID$A6: Auflösung 0,1km / Bit
4 Byte länge (Doubleword)";
CM_ SG_ 2589283631 KBI_Tankinhalt_roh "Überträgt den ungefilterten und kalibrierten Tankinhalt (incl. Überhub im Vollbereich). Die Bereitstellung des Signale erfolgt nicht nach OBD Richtlinien. Die OBD konforme Verarbeitung erfolgt im Empfänger";

CM_ SG_ 2527679656 KBI_StartupAnimation "Synchronisierung der StartupAnimation zwischen Kombi und MMI.";

CM_ SG_ 1614 KBI_HUD_Data_01 "Kommunikation Kombi zu HUD. Prio.texte zur gleichzeitigen Anzeige im Kombi und HUD.";
CM_ SG_ 1614 KBI_HUD_Data_02 "Kommunikation Kombi zu HUD. Prio.texte zur gleichzeitigen Anzeige im Kombi und HUD.";
CM_ SG_ 1614 KBI_HUD_Data_03 "Kommunikation Kombi zu HUD. Prio.texte zur gleichzeitigen Anzeige im Kombi und HUD.";
CM_ SG_ 1614 KBI_HUD_Data_04 "Kommunikation Kombi zu HUD. Prio.texte zur gleichzeitigen Anzeige im Kombi und HUD.";
CM_ SG_ 1614 KBI_HUD_Data_05 "Kommunikation Kombi zu HUD. Prio.texte zur gleichzeitigen Anzeige im Kombi und HUD.";
CM_ SG_ 1614 KBI_HUD_Data_06 "Kommunikation Kombi zu HUD. Prio.texte zur gleichzeitigen Anzeige im Kombi und HUD.";
CM_ SG_ 1614 KBI_HUD_Data_07 "Kommunikation Kombi zu HUD. Prio.texte zur gleichzeitigen Anzeige im Kombi und HUD.";
CM_ SG_ 1614 KBI_HUD_Data_08 "Kommunikation Kombi zu HUD. Prio.texte zur gleichzeitigen Anzeige im Kombi und HUD.";

CM_ SG_ 2549874964 KS_Kombi_Req_Data "Komponentenschutz (Funktion 01h). Request mit NA des Slaves.";

CM_ SG_ 2550006036 KS_Kombi_Resp_Data "Komponentenschutz (Funktion 01h). Response mit eigener NA.";

CM_ SG_ 701 LAE_Beta_confidence "Confidence factor for Beta";
CM_ SG_ 701 LAE_Beta_VZ "Sign of Beta angle";
CM_ SG_ 701 LAE_BetaSlipAngle "Estimated vehicle side slip angle
by LAE controller";
CM_ SG_ 701 LAE_BetaSlipAngle_02 "Estimated side slip angle by LAE controller";
CM_ SG_ 701 LAE_mu "Estimated grip coefficient
unsigned value";
CM_ SG_ 701 LAE_mu_confidence "Confidence factor for estimated grip
unsigned Value";
CM_ SG_ 701 LAE_Vx "Estimated longitudinal vehicle speed (m/s)";
CM_ SG_ 701 LAE_Vx_confidence "Confidence factor for longitudinal vehicle speed";
CM_ SG_ 701 LAE_Vx_VZ "Sign of longitudinal vehicle speed";
CM_ SG_ 701 LAE_Vy "Estimated lateral vehicle speed (m/s)";
CM_ SG_ 701 LAE_Vy_confidence "Confidence factor for lateral vehicle speed";

CM_ SG_ 2463978818 BTM_BrakeSystem_Status "Brake_system_status for Brake temperature estimation function:
includes status of brake disc and fluid overheating and aged fluid status";
CM_ SG_ 2463978818 BTM_BrakeSystem_Text "Brake temperature management text message to be visualized on kombi";
CM_ SG_ 2463978818 BTM_BrakeSystem_Warnlampe "Activation of warning lamp for brake temperature management";
CM_ SG_ 2463978818 LCV_01_BZ "4bit Botschaftszähler, wird mit jeder Sendebotschaft inkrementiert";
CM_ SG_ 2463978818 LCV_01_CRC "Für MLB:
Berechnung siehe Lastenheft 'Kommunikationsabsicherung für FlexRay und CAN'
Ab MQB und MLBevo:
Berechnung siehe Lastenheft 'End-to-End Kommunikationsabsicherung'

Endwerte siehe Begleitdokument 'S-PDU Kennungsfolgen'";
CM_ SG_ 2463978818 LCV_Aero_EngineBay_Cooling "Status of Engine Bay Cooling strategy";
CM_ SG_ 2463978818 LCV_Aero_Front_System_Status "Status of the front active aerodinamic system";
CM_ SG_ 2463978818 LCV_Aero_Perf_Limit "Status of Performance Limiter strategy";
CM_ SG_ 2463978818 LCV_Aero_Perf_Limit_Speed "Speed value for Performance Limiter strategy";
CM_ SG_ 2463978818 LCV_Aero_Rear_System_Status "Status of the rear active aerodinamic system";
CM_ SG_ 2463978818 LCV_Aero_Text "Display message for Aero LB 74X";
CM_ SG_ 2463978818 LCV_BrakeGongTemp "Brake temperature management gong activation";
CM_ SG_ 2463978818 LCV_DR_Systemstatus "Status of Damper Control system";
CM_ SG_ 2463978818 LCV_DR_Text "Pop-Up Text on Kombi for Damper Control";
CM_ SG_ 2463978818 LCV_DR_Warnlampe "Operative and warning lamps on the Kombi for Damper Control";
CM_ SG_ 2463978818 LCV_ESP_Zuschaltung "Zwangsweise Aktivierung ESP-Funktionalität durch die Dämpferregelung, Anforderung erfolgt auch bei Passivtastung.";
CM_ SG_ 2463978818 LCV_HD_offen "Status Heckdeckel";
CM_ SG_ 2463978818 LCV_Lift_Status "Status of Lifting System";
CM_ SG_ 2463978818 LCV_Lift_Text "Pop-Up Text on Kombi for Lifting System";
CM_ SG_ 2463978818 LCV_Lift_Warnlampe_Status "Operative and warning lamps on the Kombi for Lifting System";

CM_ SG_ 2527679780 LCV_Aero_BarMode_Activation "Status of the Aero Bar Mode";
CM_ SG_ 2527679780 LCV_Aero_BarMode_Activation_02 "Bar Mode Activation Status";
CM_ SG_ 2527679780 LCV_Aero_Button_Default "Default value for aero tuning switch";
CM_ SG_ 2527679780 LCV_Aero_Button_Range "Number of available choices of the Aero switch that shall be active";
CM_ SG_ 2527679780 LCV_Aero_Button_Select "Feedback from LCV to LIMU for button selection of Aero";
CM_ SG_ 2527679780 LCV_Aero_Button_Tunable "Aero Tuning switch active or not";
CM_ SG_ 2527679780 LCV_BarMode_Allowed "Bar Mode button availability";
CM_ SG_ 2527679780 LCV_DR_Button_Default "Default value for damper tuning switch";
CM_ SG_ 2527679780 LCV_DR_Button_Range "Number of available choices of the DC switch that shall be active";
CM_ SG_ 2527679780 LCV_DR_Button_Select "Feedback from LCV to LIMU for button selection of Damper Control";
CM_ SG_ 2527679780 LCV_DR_Button_Tunable "DC Tuning switch active or not";

CM_ SG_ 2463978684 BTM_BrakeDiscTemp_01 "Brake disc temperature 01 estimation.";
CM_ SG_ 2463978684 BTM_BrakeDiscTemp_02 "Brake disc temperature 02 estimation.";
CM_ SG_ 2463978684 BTM_BrakeDiscTemp_03 "Brake disc temperature 03 estimation.";
CM_ SG_ 2463978684 BTM_BrakeDiscTemp_04 "Brake disc temperature 04 estimation.";
CM_ SG_ 2463978684 BTM_BrakeFluidTemp_01 "Brake fluid temperature 01 estimation.";
CM_ SG_ 2463978684 BTM_BrakeFluidTemp_02 "Brake fluid temperature 02 estimation.";
CM_ SG_ 2463978684 BTM_BrakeFluidTemp_03 "Brake fluid temperature 03 estimation.";
CM_ SG_ 2463978684 BTM_BrakeFluidTemp_04 "Brake fluid temperature 04 estimation.";

CM_ SG_ 548 LCV_Aero_Front_Ratio "Front ratio of the aerodynamic load distribution ( value indicates the percentage of front left/right)";
CM_ SG_ 548 LCV_Aero_Long_Ratio "Longitudinal ratio of the aerodynamic load distribution ( value indicates the percentage of rear )";

CM_ SG_ 2589283974 BTM_BrakeDiscColour_01 "Brake disc visualization colour";
CM_ SG_ 2589283974 BTM_BrakeDiscColour_02 "Brake disc visualization colour";
CM_ SG_ 2589283974 BTM_BrakeDiscColour_03 "Brake disc visualization colour";
CM_ SG_ 2589283974 BTM_BrakeDiscColour_04 "Brake disc visualization colour";
CM_ SG_ 2589283974 BTM_BrakeFluidColour_01 "Brake fluid visualization colour";
CM_ SG_ 2589283974 BTM_BrakeFluidColour_02 "Brake fluid visualization colour";
CM_ SG_ 2589283974 BTM_BrakeFluidColour_03 "Brake fluid visualization colour";
CM_ SG_ 2589283974 BTM_BrakeFluidColour_04 "Brake fluid visualization colour";

CM_ SG_ 919 aLDW_FoD_Status "Im CBEV wird aLDW durch FoD geschützt sein und so reicht für Kombi und HUd die PR/Zieldatencontainer basierte Codierung nicht mehr aus.

Aus diesem Grund brauch wir ein separates Signal, dass uns den Freischaltezustand mitteilt.";
CM_ SG_ 919 EA_Warnblinken "Anforderung Warnblinken durch Funktion Emergency Alert";
CM_ SG_ 919 HC_Uss_Anforderung "Ansteuerung der vorderen PLA (VLS, VRS) und APS Sensoren (VL, VR)
0 = Ultraschallsensoren Aus
1 = Ultraschallsensoren An";
CM_ SG_ 919 LDW_Codierinfo_fuer_VLR "Vorhalt LDW-Codierinfo";
CM_ SG_ 919 LDW_DLC "distance to line, Abstand vom Fahrzeug zur Fahrbahnmarkierung
Der Wert gibt die Breite der Restspur zur Linie wieder (Abstand vom Fahrzeugäußerem zur Linie) (Wert POSITIV wenn Fahrzeug in der Spur - Wert NEGATIV wenn Fahrzeug über der Linie)";
CM_ SG_ 919 LDW_Frueh_Spaet "Im MMI eingestellter, aktiver Lenkeingriffszeitpunkt:
0: frueh, frueh aktiv
1: frueh, spaet aktiv
2: spaet, spaet aktiv
3: Fehler";
CM_ SG_ 919 LDW_Gong "Löst ein definiertes akustisches Signal aus.";
CM_ SG_ 919 LDW_Lernmodus "Signal dient zur Ansteuerung von Funktionsanzeigen im Mitteldisplay des Kombiinstruments (neue Funktion im MLB)";
CM_ SG_ 919 LDW_Lernmodus_seitenabhaengig "Signal dient zur Ansteuerung von Funktionsanzeigen im Mitteldisplay des Kombiinstruments für die Seitenabhänige Liniendetektion (neue Funktion ab D4)";
CM_ SG_ 919 LDW_Seite_DLCTLC "Zuordnung auf welche Seite sich LDW_DLC bzw. LDW_TLC beziehen";
CM_ SG_ 919 LDW_Status_LED_gruen " ";
CM_ SG_ 919 LDW_Texte "Bei Anzeige eines Fehlertextes im Kombi ertönt ein akustisches Signal";
CM_ SG_ 919 LDW_TLC "time to line, Zeit bis das Fahrzeug die Fahrbahnmarkierung überquert";
CM_ SG_ 919 LKS_LED_an "Ansteuerung LED auf LKS-Taste im Lichtassistenzmodul";

CM_ SG_ 810 EPS_01_CRC "Für MLB:
'Berechnung siehe Lastenheft 'Kommunikationsabsicherung für FlexRay und CAN''

Ab MQB und MLBevo:
'Berechnung siehe Lastenheft 'End-to-End Kommunikationsabsicherung''

Endwerte siehe Begleitdokument 'S-PDU Kennungsfolgen'
";
CM_ SG_ 810 EPS_Anf_KL "Nach Überschreiten einer oberen Grenztemperatur innerhalb des Steuergerätes der Lenkhilfe fordert die EPS die Zuschaltung einer externen Kühlung durch den Kühlerlüfter an.
Es besteht kein technischer Zusammenhang mit einer Batterie_ab - Erkennung in der ";
CM_ SG_ 810 EPS_ARA_Status "Anforderung vom Anhängerrangierassistent. 
16 Statuswerte";
CM_ SG_ 810 EPS_Charisma_FahrPr "MLBevo: Aktuelles Fahrprogramm des Charisma-Teilnehmers (siehe Systemlastenheft Drive Select)
MQB: Istwert der Kennlinie (siehe Systemlastenheft MQB FPA)";
CM_ SG_ 810 EPS_Charisma_Status "Rückmeldung an den Charisma-Master

Wert 0x3 ist nur für Fahrzeuge ab MQB relevant";
CM_ SG_ 810 EPS_Endanschlag "Die EPS muss applikativ ein Lenkhubmapping umsetzen. Das Lenkhubmapping muss für jeden NR-Reglerstatus den Defaultendanschlag oder die Lenkhubaufweitung zuordnen.";
CM_ SG_ 810 EPS_Fehlerlampe "Steuert direkt die Fehlerlampe Lenkhilfe (gelb); kein Aufprüfen bei Neustart, keine Rückleseinformation in Kombi-Botschaft (nur für VW526 Hybrid)";
CM_ SG_ 810 EPS_Lenkerposition "Position des Lenkers im Fahrzeug";
CM_ SG_ 810 EPS_PLA_Status "Zustand der Statusmaschine der EPS für die korrespondierenden Statusmaschine im PLA.";
CM_ SG_ 810 EPS_PWR_Abbruch "Dieses Signal gibt das Abbruchkriterium für PLA und ARA an.";
CM_ SG_ 810 EPS_PWR_Fehler "Gibt den Fehler aus wenn eine Lenkwinkelanforderung nicht ausgeführt werden konnte.";
CM_ SG_ 810 EPS_SpannungsAnf "Forderung des EPS-SG's zur Spannungsanhebung.";
CM_ SG_ 810 EPS_Warnungen "Diese Bits werden verwendet, um im Kombi Texte, Lampen oder Bilder für die Lenkhilfe darzustellen
Audi MLB/RSe:
Text_1: Lenkung defekt (Prio 1)
Text_2: Lenkung Systemstörung (Prio 2)
VW526:
Text_1 (ID_TXT_1026.1): Ausfall Lenkunterstützung
Text_2 (I";

CM_ SG_ 981 BCM1_Abblendlicht_Anf "Anforderung Abblendlicht
";
CM_ SG_ 981 BCM1_Adaptive_Lichtvert_Anf "Funktion 'Adaptive Lichtverteilung' im AFS-SG  Ein- und Ausschalten";
CM_ SG_ 981 BCM1_Allwetterlicht_Anf "Anforderung eines Allwetterlichts (über AFS-SG realisiert): Licht für schlechte Sichtverhältnisse";
CM_ SG_ 981 BCM1_Animationssperrung "Sperrung der Scheinwerfer- und Heckleuchten-Animationen. Grund für Sperrung sind allgemeine Rahmenbedingungen, wie beispielseweise eine LDS-Stellung ungleich 'Auto'";
CM_ SG_ 981 BCM1_Autobahnlicht_Anf "Anforderung Autobahnlicht
";
CM_ SG_ 981 BCM1_CH_aktiv "Coming Home (zusätzlich zum Signal 'BCM1_CH_LH_aktiv' in der Botschaft BCM1_01)";
CM_ SG_ 981 BCM1_CH_LH_aktiv "Status Comming / Leaving Home
";
CM_ SG_ 981 BCM1_Fernlicht_Anf "Anforderung Fernlicht
";
CM_ SG_ 981 BCM1_FOD_Sperrung_Animationen_HL "Sperrung Heckleuchten-Animationen durch FoD.";
CM_ SG_ 981 BCM1_FoD_Sperrung_WiBli "Sperrung Wischeffekt des dynamischen Blinkers (Front & Heck) durch FoD";
CM_ SG_ 981 BCM1_Gleitende_Leuchtw_Anf "Funktion 'Gleitende Leuchtweite' im AFS-SG  freischalten";
CM_ SG_ 981 BCM1_GLW_Fernlicht_Anf "Harte Fernlichtanforderung von BCM1 an die Funktion 'gleitende Leuchtweite' im AFS-SG";
CM_ SG_ 981 BCM1_Kurvenlicht_links_Anf "Ansteuerung linkes Kurvenlicht/Abbiegelicht duch BCM1";
CM_ SG_ 981 BCM1_Kurvenlicht_rechts_Anf "Ansteuerung rechtes Kurvenlicht/Abbiegelicht duch BCM1";
CM_ SG_ 981 BCM1_LH_aktiv "Leaving Home (zusätzlich zum Signal 'BCM1_CH_LH_aktiv' in der Botschaft BCM1_01)";
CM_ SG_ 981 BCM1_Nebellicht_Anf "Anforderung Nebellicht
";
CM_ SG_ 981 BCM1_Nebelschluss_Ahg_Anf "Anforderung: Nebelschlusslicht Anhänger (Sollzustand)
";
CM_ SG_ 981 BCM1_Nebelschluss_Fzg_Anf "Anforderung: Nebelschlusslicht Fahrzeug (Sollzustand)";
CM_ SG_ 981 BCM1_Parklicht_li_Anf "Anforderung: Parklicht links (Sollzustand)
";
CM_ SG_ 981 BCM1_Parklicht_re_Anf "Anforderung: Parklicht rechts (Sollzustand)
";
CM_ SG_ 981 BCM1_Regenlicht_Anf "Anforderung: Regenlicht (Sollzustand)
";
CM_ SG_ 981 BCM1_Schlusslicht_Anf "Anforderung: Schlusslicht Fahrzeug (Sollzustand)
";
CM_ SG_ 981 BCM1_Schlusslicht_Signatur "Anforderung der Umschaltung der Schlusslicht-Signatur";
CM_ SG_ 981 BCM1_Signaturlicht_Anf "Signal zur Anforderung des Signaturlichts";
CM_ SG_ 981 BCM1_Standlicht_Anf "Anforderung: Schlusslicht (Sollzustand)";
CM_ SG_ 981 BCM1_Tagfahrlicht_Anf "Anforderung: Tagfahrlicht (Sollzustand)";
CM_ SG_ 981 BCM1_Touristen_Licht_Anf "Anforderung: Touristenlicht (Sollzustand)";
CM_ SG_ 981 BCM1_Umfeldleuchten_Anf "Anforderung für Umfeldleuchten";
CM_ SG_ 981 BCM_Rueckfahrlicht_Anf "Anforderung Rückfahrlicht (Sollzustand). 
Das Signal wird entprellt (typisch 400ms) und bei KL15EIN gesendet. Das Signal ist unabhängig von der Position des Heckdeckels (kein Überhitzungsschutz).";
CM_ SG_ 981 Licht_Anf_01_BZ "4bit Botschaftszaehler, wird mit jeder Sendebotschaft inkrementiert
Botschaft asynchron geroutet. Zählerwert kann springen.";
CM_ SG_ 981 Licht_Anf_01_CRC "Für MLB:
'Berechnung siehe Lastenheft 'Kommunikationsabsicherung für FlexRay und CAN''

Ab MQB und MLBevo:
'Berechnung siehe Lastenheft 'End-to-End Kommunikationsabsicherung''

Endwerte siehe Begleitdokument 'S-PDU Kennungsfolgen'";

CM_ SG_ 982 BCM2_Bremsl_durch_ECD "Bremslicht (ECD-Bremsung)
";
CM_ SG_ 982 LH_3_Bremsl_def "Fehlerstatus 3. Bremsleuchte
";
CM_ SG_ 982 LH_Aussenlicht_def "Aussenlicht kann nicht mehr korrekt angesteuert werden (EEPROM Codierung kann nicht mehr ausgelesen werden)
";
CM_ SG_ 982 LH_Blinker_HL_akt "Blinker hinten links
";
CM_ SG_ 982 LH_Blinker_HR_akt "Blinker hinten rechts
";
CM_ SG_ 982 LH_Blinker_li_def "Fehlerstatus Blinker hinten links
";
CM_ SG_ 982 LH_Blinker_re_def "Fehlerstatus Blinker hinten rechts
";
CM_ SG_ 982 LH_Brems_Blk_li_def "Konfiguration BRL + BLK links 
";
CM_ SG_ 982 LH_Brems_Blk_re_def "Konfiguration BRL + BLK rechts
";
CM_ SG_ 982 LH_Bremsl_li_def "Fehlerstatus Bremslicht hinten links (Detektion Einzelausfall)
";
CM_ SG_ 982 LH_Bremsl_li_ges_def "Fehlerstatus Bremslicht hinten links (Detektion Totalausfall)
";
CM_ SG_ 982 LH_Bremsl_mi_def "Fehlerstatus Bremslicht mitte oder Gepäckraumklappe  (Detektion Einzelausfall)";
CM_ SG_ 982 LH_Bremsl_re_def "Fehlerstatus Bremslicht hinten rechts  (Detektion Einzelausfall)
";
CM_ SG_ 982 LH_Bremsl_re_ges_def "Fehlerstatus Bremslicht hinten rechts (Detektion Totalausfall)";
CM_ SG_ 982 LH_Bremslicht_H_aktiv "Bremslicht hinten
";
CM_ SG_ 982 LH_Diag_LED_li_def "Heckleuchte links defekt";
CM_ SG_ 982 LH_Diag_LED_re_def "Heckleuchte rechts defekt";
CM_ SG_ 982 LH_Diag_Status_li_def "Außenlicht Diagnose 
Systemstörung links";
CM_ SG_ 982 LH_Diag_Status_re_def "Außenlicht Diagnose Systemstörung rechts ";
CM_ SG_ 982 LH_Kennzl_def "Fehlerstatus Kennzeichenbeleuchtung hinten
";
CM_ SG_ 982 LH_Nebel_li_def "Fehlererkennung Nebelschlusslicht hinten links
";
CM_ SG_ 982 LH_Nebel_mi_def "Fehlererkennung Nebelschlusslicht hinten Mitte


";
CM_ SG_ 982 LH_Nebel_re_def "Fehlererkennung Nebelschlusslicht hinten rechts
";
CM_ SG_ 982 LH_Nebelschluss_aktiv "Nebelschlusslicht
";
CM_ SG_ 982 LH_Parklicht_HL_aktiv "Parklicht hinten links 
";
CM_ SG_ 982 LH_Parklicht_HR_aktiv "Parklicht hinten rechts 
";
CM_ SG_ 982 LH_Rueckf_li_def "Fehlererkennung Rückfahrlicht hinten links
";
CM_ SG_ 982 LH_Rueckf_mi_def "Fehlererkennung Rückfahrlicht Mitte
";
CM_ SG_ 982 LH_Rueckf_re_def "Fehlererkennung Rückfahrlicht hinten rechts
";
CM_ SG_ 982 LH_Rueckfahrlicht_aktiv "Rueckfahrlicht";
CM_ SG_ 982 LH_Schluss_Brems_li_def "Konfiguration SL+ BRL + PL links und SL+ BRL  links
";
CM_ SG_ 982 LH_Schluss_Brems_mi_def "Fehlerstatus Schluss + Bremslicht mitte defekt (Detektion Einzelausfall)";
CM_ SG_ 982 LH_Schluss_Brems_Nebel_li_def "Signal wird gesetzt, wenn eine Unterbrechung oder  ein Kurzschluss am Lampenausgang für Schluss_Brems_Nebelschlusslicht erkannt wird.";
CM_ SG_ 982 LH_Schluss_Brems_Nebel_re_def "Signal wird gesetzt, wenn eine Unterbrechung oder  ein Kurzschluss am Lampenausgang für Schluss_Brems_Nebelschlusslicht erkannt wird.";
CM_ SG_ 982 LH_Schluss_Brems_re_def "Konfiguration SL+ BRL + PL rechts und SL+ BRL  rechts
";
CM_ SG_ 982 LH_Schluss_Nebel_li_def "Konfiguration SL + NSL links oder SL + NSL + PL links
";
CM_ SG_ 982 LH_Schluss_Nebel_re_def "Konfiguration SL + NSL rechts oder SL + NSL + PL rechts
";
CM_ SG_ 982 LH_Schlusslicht_li_def "Fehlererkennung Schlusslicht hinten links
";
CM_ SG_ 982 LH_Schlusslicht_mi_def "Fehlererkennung Schlusslicht hinten Mitte";
CM_ SG_ 982 LH_Schlusslicht_re_def "Fehlererkennung Schlusslicht hinten rechts
";
CM_ SG_ 982 LH_SL_BRL_BLK_li_def "Konfiguration SL + BRL + BLK links oder SL + BRL + BLK + PL links
";
CM_ SG_ 982 LH_SL_BRL_BLK_re_def "Konfiguration SL + BRL + BLK rechts oder SL + BRL + BLK + PL rechts
";
CM_ SG_ 982 LH_Standlicht_H_aktiv "Standlicht hinten
";
CM_ SG_ 982 LH_Zusatzschlussl_def "mindestens ein Zusatzschlusslicht in der Heckbeleuchtung defekt.";
BA_DEF_REL_ BU_SG_REL_  "GenSigTimeoutTime" INT 0 65535;
BA_DEF_ BO_  "DiagRequest" ENUM "No", "Yes";
BA_DEF_ BO_  "DiagResponse" ENUM "No", "Yes";
BA_DEF_ BO_  "DiagState" ENUM "No", "Yes";
BA_DEF_ BO_  "GenMsgChkConstant" HEX 0 4095;
BA_DEF_ BO_  "GenMsgCycleTime" INT 0 65535;
BA_DEF_ BO_  "GenMsgCycleTimeFast" INT 0 65535;
BA_DEF_ BO_  "GenMsgDelayTime" INT 0 100000;
BA_DEF_ BO_  "GenMsgILSupport" ENUM "No", "Yes";
BA_DEF_ BO_  "GenMsgNrOfRepetition" INT 0 100;
BA_DEF_ BO_  "GenMsgPDUConstants" STRING;
BA_DEF_ BO_  "GenMsgSendType" ENUM "Cyclic", "not_used", "not_used", "not_used", "not_used", "not_used", "not_used", "IfActive", "NoMsgSendType";
BA_DEF_ BO_  "GenMsgStartDelayTime" INT 0 100000;
BA_DEF_ BO_  "NmMessage" ENUM "No", "Yes";
BA_DEF_ BO_  "NmhMessage" ENUM "No", "Yes";
BA_DEF_ BO_  "MsgType" ENUM "Application", "NM ", "NMH", "TP2.0", "ISO-TP ", "BAP", "EID", "KS", "XCP_PRE_CONFIGURED", "XCP_RUNTIME_CONFIGURED";
BA_DEF_ BO_  "VAGTP20_API" HEX 0 255;
BA_DEF_ BO_  "VAGTP20_DynConnection" ENUM "No", "Yes";
BA_DEF_ BO_  "VAGTP20_DynSetup" ENUM "No", "Yes";
BA_DEF_ BO_  "VAGTP20_StatConnection" ENUM "No", "Yes";
BA_DEF_ SG_  "GenSigActiveRepetitions" INT -2147483648 2147483647;
BA_DEF_ SG_  "GenSigInactiveValue" INT -2147483648 2147483647;
BA_DEF_ SG_  "GenSigSendType" ENUM "Cyclic", "OnWrite", "OnWriteWithRepetition", "OnChange", "OnChangeWithRepetition", "IfActive", "IfActiveWithRepetition", "NoSigSendType", "OnChangeAndIfActive", "OnChangeAndIfActiveWithRepetition";
BA_DEF_ SG_  "GenSigStartValue" INT -2147483648 2147483647;
BA_DEF_ SG_  "NWM-WakeupAllowed" ENUM "No", "Yes";
BA_DEF_ SG_  "GenSigFuncType" ENUM "NoFunction", "MsgCounter", "CRC-8", "XOR", "XOR-2", "DatedBit", "SW-Kl15", "CHK", "Constant", "Protocol", "CRC-8-SAE_J1850", "CRC-32", "DataLength", "DataID", "MsgCounter16", "SOK-Signatur", "Cluster";
BA_DEF_ SG_  "GenSigSwitchedByIgnition" ENUM "No", "Yes";
BA_DEF_ SG_  "Fehlerwert" HEX 0 2147483647;
BA_DEF_ SG_  "GenSigMissingSourceValue" HEX 0 2147483647;
BA_DEF_DEF_REL_  "GenSigTimeoutTime" 0;
BA_DEF_DEF_  "DiagRequest" "No";
BA_DEF_DEF_  "DiagResponse" "No";
BA_DEF_DEF_  "DiagState" "No";
BA_DEF_DEF_  "GenMsgChkConstant" 0;
BA_DEF_DEF_  "GenMsgCycleTime" 0;
BA_DEF_DEF_  "GenMsgCycleTimeFast" 0;
BA_DEF_DEF_  "GenMsgDelayTime" 0;
BA_DEF_DEF_  "GenMsgILSupport" "No";
BA_DEF_DEF_  "GenMsgNrOfRepetition" 0;
BA_DEF_DEF_  "GenMsgPDUConstants" "";
BA_DEF_DEF_  "GenMsgSendType" "NoMsgSendType";
BA_DEF_DEF_  "GenMsgStartDelayTime" 0;
BA_DEF_DEF_  "NmMessage" "No";
BA_DEF_DEF_  "NmhMessage" "No";
BA_DEF_DEF_  "MsgType" "Application";
BA_DEF_DEF_  "VAGTP20_API" 0;
BA_DEF_DEF_  "VAGTP20_DynConnection" "No";
BA_DEF_DEF_  "VAGTP20_DynSetup" "No";
BA_DEF_DEF_  "VAGTP20_StatConnection" "No";
BA_DEF_DEF_  "GenSigActiveRepetitions" 0;
BA_DEF_DEF_  "GenSigInactiveValue" 0;
BA_DEF_DEF_  "GenSigSendType" "NoSigSendType";
BA_DEF_DEF_  "GenSigStartValue" 0;
BA_DEF_DEF_  "NWM-WakeupAllowed" "No";
BA_DEF_DEF_  "GenSigFuncType" "NoFunction";
BA_DEF_DEF_  "GenSigSwitchedByIgnition" "Yes";
BA_DEF_DEF_  "Fehlerwert" 0;
BA_DEF_DEF_  "GenSigMissingSourceValue" 0;
BA_ "GenMsgCycleTime" BO_ 1640 200;
BA_ "GenMsgILSupport" BO_ 1640 1;
BA_ "GenMsgSendType" BO_ 1640 0;
BA_ "GenMsgCycleTime" BO_ 2463978701 100;
BA_ "GenMsgILSupport" BO_ 2463978701 1;
BA_ "GenMsgSendType" BO_ 2463978701 0;
BA_ "GenMsgCycleTime" BO_ 1505 200;
BA_ "GenMsgILSupport" BO_ 1505 1;
BA_ "GenMsgSendType" BO_ 1505 0;
BA_ "GenMsgCycleTime" BO_ 2549088272 500;
BA_ "GenMsgILSupport" BO_ 2549088272 1;
BA_ "GenMsgSendType" BO_ 2549088272 0;
BA_ "GenMsgStartDelayTime" BO_ 2549088272 75;
BA_ "GenMsgCycleTime" BO_ 2549088283 500;
BA_ "GenMsgILSupport" BO_ 2549088283 1;
BA_ "GenMsgSendType" BO_ 2549088283 0;
BA_ "GenMsgCycleTime" BO_ 2549088276 500;
BA_ "GenMsgILSupport" BO_ 2549088276 1;
BA_ "GenMsgSendType" BO_ 2549088276 0;
BA_ "GenMsgCycleTime" BO_ 2549088339 500;
BA_ "GenMsgILSupport" BO_ 2549088339 1;
BA_ "GenMsgSendType" BO_ 2549088339 0;
BA_ "GenMsgCycleTime" BO_ 779 50;
BA_ "GenMsgILSupport" BO_ 779 1;
BA_ "GenMsgSendType" BO_ 779 0;
BA_ "GenMsgCycleTime" BO_ 1719 1000;
BA_ "GenMsgDelayTime" BO_ 1719 100;
BA_ "GenMsgILSupport" BO_ 1719 1;
BA_ "GenMsgSendType" BO_ 1719 0;
BA_ "GenMsgCycleTime" BO_ 1720 500;
BA_ "GenMsgILSupport" BO_ 1720 1;
BA_ "GenMsgSendType" BO_ 1720 0;
BA_ "GenMsgCycleTime" BO_ 1724 1000;
BA_ "GenMsgILSupport" BO_ 1724 1;
BA_ "GenMsgSendType" BO_ 1724 0;
BA_ "GenMsgCycleTime" BO_ 2589283471 1000;
BA_ "GenMsgDelayTime" BO_ 2589283471 100;
BA_ "GenMsgILSupport" BO_ 2589283471 1;
BA_ "GenMsgSendType" BO_ 2589283471 0;
BA_ "GenMsgCycleTime" BO_ 2527679638 1000;
BA_ "GenMsgDelayTime" BO_ 2527679638 100;
BA_ "GenMsgILSupport" BO_ 2527679638 1;
BA_ "GenMsgSendType" BO_ 2527679638 0;
BA_ "GenMsgCycleTime" BO_ 2527679639 1000;
BA_ "GenMsgCycleTimeFast" BO_ 2527679639 100;
BA_ "GenMsgDelayTime" BO_ 2527679639 100;
BA_ "GenMsgILSupport" BO_ 2527679639 1;
BA_ "GenMsgSendType" BO_ 2527679639 0;
BA_ "GenMsgCycleTime" BO_ 2589283631 500;
BA_ "GenMsgILSupport" BO_ 2589283631 1;
BA_ "GenMsgSendType" BO_ 2589283631 0;
BA_ "GenMsgCycleTime" BO_ 2527679656 1000;
BA_ "GenMsgDelayTime" BO_ 2527679656 50;
BA_ "GenMsgILSupport" BO_ 2527679656 1;
BA_ "GenMsgSendType" BO_ 2527679656 0;
BA_ "GenMsgCycleTime" BO_ 1614 1000;
BA_ "GenMsgDelayTime" BO_ 1614 20;
BA_ "GenMsgILSupport" BO_ 1614 1;
BA_ "GenMsgSendType" BO_ 1614 0;
BA_ "MsgType" BO_ 2549874964 4;
BA_ "MsgType" BO_ 2550006036 4;
BA_ "GenMsgCycleTime" BO_ 701 40;
BA_ "GenMsgILSupport" BO_ 701 1;
BA_ "GenMsgSendType" BO_ 701 0;
BA_ "GenMsgCycleTime" BO_ 2463978818 320;
BA_ "GenMsgDelayTime" BO_ 2463978818 20;
BA_ "GenMsgILSupport" BO_ 2463978818 1;
BA_ "GenMsgPDUConstants" BO_ 2463978818 "0x96,0xb2,0xc5,0x01,0x2d,0x0c,0xe0,0xf8,0x50,0x8a,0x08,0xd7,0x62,0xf2,0xf5,0x33";
BA_ "GenMsgSendType" BO_ 2463978818 0;
BA_ "GenMsgCycleTime" BO_ 2527679780 1000;
BA_ "GenMsgDelayTime" BO_ 2527679780 50;
BA_ "GenMsgILSupport" BO_ 2527679780 1;
BA_ "GenMsgSendType" BO_ 2527679780 0;
BA_ "GenMsgCycleTime" BO_ 2463978684 100;
BA_ "GenMsgILSupport" BO_ 2463978684 1;
BA_ "GenMsgSendType" BO_ 2463978684 0;
BA_ "GenMsgCycleTime" BO_ 548 20;
BA_ "GenMsgILSupport" BO_ 548 1;
BA_ "GenMsgSendType" BO_ 548 0;
BA_ "GenMsgCycleTime" BO_ 2589283974 1000;
BA_ "GenMsgILSupport" BO_ 2589283974 1;
BA_ "GenMsgSendType" BO_ 2589283974 0;
BA_ "GenMsgCycleTime" BO_ 919 80;
BA_ "GenMsgDelayTime" BO_ 919 40;
BA_ "GenMsgILSupport" BO_ 919 1;
BA_ "GenMsgSendType" BO_ 919 0;
BA_ "GenMsgChkConstant" BO_ 810 41;
BA_ "GenMsgCycleTime" BO_ 810 40;
BA_ "GenMsgILSupport" BO_ 810 1;
BA_ "GenMsgPDUConstants" BO_ 810 "0x29,0x29,0x29,0x29,0x29,0x29,0x29,0x29,0x29,0x29,0x29,0x29,0x29,0x29,0x29,0x29";
BA_ "GenMsgSendType" BO_ 810 0;
BA_ "GenMsgCycleTime" BO_ 981 500;
BA_ "GenMsgDelayTime" BO_ 981 50;
BA_ "GenMsgILSupport" BO_ 981 1;
BA_ "GenMsgPDUConstants" BO_ 981 "0xc5,0x39,0xc7,0xf9,0x92,0xd8,0x24,0xce,0xf1,0xb5,0x7a,0xc4,0xbc,0x60,0xe3,0xd1";
BA_ "GenMsgSendType" BO_ 981 0;
BA_ "GenMsgCycleTime" BO_ 982 100;
BA_ "GenMsgILSupport" BO_ 982 1;
BA_ "GenMsgPDUConstants" BO_ 982 "0xc5,0x8e,0x64,0x95,0x9e,0xed,0x60,0x45,0x5d,0x8d,0xb2,0x80,0xa1,0x23,0x7d,0x35";
BA_ "GenMsgSendType" BO_ 982 0;
BA_ "GenSigSendType" SG_ 1640 FSH_Taster 0;
BA_ "GenSigSwitchedByIgnition" SG_ 1640 FSH_Taster 0;
BA_ "GenSigSendType" SG_ 1640 HSH_Taster 0;
BA_ "GenSigSwitchedByIgnition" SG_ 1640 HSH_Taster 0;
BA_ "GenSigSendType" SG_ 1640 KL_Beschlagsgefahr 0;
BA_ "GenSigSwitchedByIgnition" SG_ 1640 KL_Beschlagsgefahr 0;
BA_ "GenSigSendType" SG_ 1640 KL_Geblspng_Fond_Soll 0;
BA_ "GenSigSwitchedByIgnition" SG_ 1640 KL_Geblspng_Fond_Soll 0;
BA_ "Fehlerwert" SG_ 1640 KL_Geblspng_Fond_Soll 255;
BA_ "GenSigSendType" SG_ 1640 KL_Geblspng_Soll 0;
BA_ "GenSigSwitchedByIgnition" SG_ 1640 KL_Geblspng_Soll 0;
BA_ "Fehlerwert" SG_ 1640 KL_Geblspng_Soll 255;
BA_ "GenSigSendType" SG_ 1640 KL_I_Geblaese 0;
BA_ "GenSigSwitchedByIgnition" SG_ 1640 KL_I_Geblaese 0;
BA_ "Fehlerwert" SG_ 1640 KL_I_Geblaese 255;
BA_ "GenSigSendType" SG_ 1640 KL_Kompressorstrom_soll 0;
BA_ "GenSigStartValue" SG_ 1640 KL_Kompressorstrom_soll 1022;
BA_ "GenSigSwitchedByIgnition" SG_ 1640 KL_Kompressorstrom_soll 0;
BA_ "Fehlerwert" SG_ 1640 KL_Kompressorstrom_soll 1023;
BA_ "GenSigSendType" SG_ 1640 KL_LRH_Stufe 0;
BA_ "GenSigStartValue" SG_ 1640 KL_LRH_Stufe 1;
BA_ "GenSigSwitchedByIgnition" SG_ 1640 KL_LRH_Stufe 0;
BA_ "GenSigSendType" SG_ 1640 KL_LRH_Taster 0;
BA_ "GenSigSwitchedByIgnition" SG_ 1640 KL_LRH_Taster 0;
BA_ "GenSigSendType" SG_ 1640 KL_PTC_Verbauinfo 0;
BA_ "GenSigSwitchedByIgnition" SG_ 1640 KL_PTC_Verbauinfo 0;
BA_ "GenSigSendType" SG_ 1640 KL_SIH_Soll_li 0;
BA_ "GenSigSwitchedByIgnition" SG_ 1640 KL_SIH_Soll_li 0;
BA_ "GenSigSendType" SG_ 1640 KL_SIH_Soll_re 0;
BA_ "GenSigSwitchedByIgnition" SG_ 1640 KL_SIH_Soll_re 0;
BA_ "GenSigSendType" SG_ 1640 KL_SIL_Soll_li 0;
BA_ "GenSigSwitchedByIgnition" SG_ 1640 KL_SIL_Soll_li 0;
BA_ "GenSigSendType" SG_ 1640 KL_SIL_Soll_re 0;
BA_ "GenSigSwitchedByIgnition" SG_ 1640 KL_SIL_Soll_re 0;
BA_ "GenSigSendType" SG_ 1640 KL_Umluftklappe_Status 0;
BA_ "GenSigStartValue" SG_ 1640 KL_Umluftklappe_Status 14;
BA_ "GenSigSwitchedByIgnition" SG_ 1640 KL_Umluftklappe_Status 0;
BA_ "Fehlerwert" SG_ 1640 KL_Umluftklappe_Status 15;
BA_ "GenSigSendType" SG_ 1640 KL_Zuheizer_Freigabe 0;
BA_ "GenSigSwitchedByIgnition" SG_ 1640 KL_Zuheizer_Freigabe 0;
BA_ "GenSigSendType" SG_ 1640 KRH_Soll_li 0;
BA_ "GenSigSwitchedByIgnition" SG_ 1640 KRH_Soll_li 0;
BA_ "GenSigSendType" SG_ 1640 KRH_Soll_re 0;
BA_ "GenSigSwitchedByIgnition" SG_ 1640 KRH_Soll_re 0;
BA_ "GenSigSendType" SG_ 2463978701 KL_AC_Schalter_Prognose 0;
BA_ "GenSigSwitchedByIgnition" SG_ 2463978701 KL_AC_Schalter_Prognose 0;
BA_ "GenSigSendType" SG_ 2463978701 KL_Leistungsreduktions_Hinweis 0;
BA_ "GenSigSwitchedByIgnition" SG_ 2463978701 KL_Leistungsreduktions_Hinweis 0;
BA_ "GenSigSendType" SG_ 2463978701 KL_Sollklimamodus_FPR_1 0;
BA_ "GenSigStartValue" SG_ 2463978701 KL_Sollklimamodus_FPR_1 1;
BA_ "GenSigSwitchedByIgnition" SG_ 2463978701 KL_Sollklimamodus_FPR_1 0;
BA_ "GenSigSendType" SG_ 2463978701 KL_Sollklimamodus_FPR_2 0;
BA_ "GenSigStartValue" SG_ 2463978701 KL_Sollklimamodus_FPR_2 1;
BA_ "GenSigSwitchedByIgnition" SG_ 2463978701 KL_Sollklimamodus_FPR_2 0;
BA_ "GenSigSendType" SG_ 2463978701 KL_Sollklimamodus_FPR_3 0;
BA_ "GenSigStartValue" SG_ 2463978701 KL_Sollklimamodus_FPR_3 1;
BA_ "GenSigSwitchedByIgnition" SG_ 2463978701 KL_Sollklimamodus_FPR_3 0;
BA_ "GenSigSendType" SG_ 2463978701 KL_Temp_Soll_hl_Prognose 0;
BA_ "GenSigStartValue" SG_ 2463978701 KL_Temp_Soll_hl_Prognose 31;
BA_ "GenSigSwitchedByIgnition" SG_ 2463978701 KL_Temp_Soll_hl_Prognose 0;
BA_ "GenSigSendType" SG_ 2463978701 KL_Temp_Soll_hr_Prognose 0;
BA_ "GenSigStartValue" SG_ 2463978701 KL_Temp_Soll_hr_Prognose 31;
BA_ "GenSigSwitchedByIgnition" SG_ 2463978701 KL_Temp_Soll_hr_Prognose 0;
BA_ "GenSigSendType" SG_ 2463978701 KL_Temp_Soll_vl_Prognose 0;
BA_ "GenSigStartValue" SG_ 2463978701 KL_Temp_Soll_vl_Prognose 31;
BA_ "GenSigSwitchedByIgnition" SG_ 2463978701 KL_Temp_Soll_vl_Prognose 0;
BA_ "GenSigSendType" SG_ 2463978701 KL_Temp_Soll_vr_Prognose 0;
BA_ "GenSigStartValue" SG_ 2463978701 KL_Temp_Soll_vr_Prognose 31;
BA_ "GenSigSwitchedByIgnition" SG_ 2463978701 KL_Temp_Soll_vr_Prognose 0;
BA_ "GenSigSendType" SG_ 1505 BCM1_Aussen_Temp_ungef 0;
BA_ "GenSigStartValue" SG_ 1505 BCM1_Aussen_Temp_ungef 254;
BA_ "GenSigSwitchedByIgnition" SG_ 1505 BCM1_Aussen_Temp_ungef 0;
BA_ "Fehlerwert" SG_ 1505 BCM1_Aussen_Temp_ungef 255;
BA_ "GenSigSendType" SG_ 1505 BCM1_FStatus_Aussentemp_ungef 0;
BA_ "GenSigStartValue" SG_ 1505 BCM1_FStatus_Aussentemp_ungef 1;
BA_ "GenSigSwitchedByIgnition" SG_ 1505 BCM1_FStatus_Aussentemp_ungef 0;
BA_ "GenSigSendType" SG_ 1505 BCM1_Kompressorstrom_ist 0;
BA_ "GenSigStartValue" SG_ 1505 BCM1_Kompressorstrom_ist 254;
BA_ "GenSigSwitchedByIgnition" SG_ 1505 BCM1_Kompressorstrom_ist 0;
BA_ "Fehlerwert" SG_ 1505 BCM1_Kompressorstrom_ist 255;
BA_ "GenSigSendType" SG_ 1505 BCM1_OBD_FStatus_ATemp 0;
BA_ "GenSigSwitchedByIgnition" SG_ 1505 BCM1_OBD_FStatus_ATemp 0;
BA_ "GenSigSendType" SG_ 1505 BCM1_PTC_stufig_Status 0;
BA_ "GenSigStartValue" SG_ 1505 BCM1_PTC_stufig_Status 6;
BA_ "GenSigSwitchedByIgnition" SG_ 1505 BCM1_PTC_stufig_Status 0;
BA_ "Fehlerwert" SG_ 1505 BCM1_PTC_stufig_Status 7;
BA_ "GenSigSendType" SG_ 1505 BCM_Heizungsabsperrventil_Status 0;
BA_ "GenSigStartValue" SG_ 1505 BCM_Heizungsabsperrventil_Status 2;
BA_ "GenSigSwitchedByIgnition" SG_ 1505 BCM_Heizungsabsperrventil_Status 0;
BA_ "Fehlerwert" SG_ 1505 BCM_Heizungsabsperrventil_Status 3;
BA_ "GenSigSendType" SG_ 1505 BCM_Heizungspumpe_Status 0;
BA_ "GenSigStartValue" SG_ 1505 BCM_Heizungspumpe_Status 2;
BA_ "GenSigSwitchedByIgnition" SG_ 1505 BCM_Heizungspumpe_Status 0;
BA_ "Fehlerwert" SG_ 1505 BCM_Heizungspumpe_Status 3;
BA_ "GenSigSendType" SG_ 1505 BCM_Kompressorkupplung_Status 0;
BA_ "GenSigStartValue" SG_ 1505 BCM_Kompressorkupplung_Status 2;
BA_ "GenSigSwitchedByIgnition" SG_ 1505 BCM_Kompressorkupplung_Status 0;
BA_ "Fehlerwert" SG_ 1505 BCM_Kompressorkupplung_Status 3;
BA_ "GenSigSendType" SG_ 2549088272 Gateway_Abschaltstufe 0;
BA_ "GenSigSwitchedByIgnition" SG_ 2549088272 Gateway_Abschaltstufe 0;
BA_ "GenSigSendType" SG_ 2549088272 Gateway_KompSchutz 0;
BA_ "GenSigSwitchedByIgnition" SG_ 2549088272 Gateway_KompSchutz 0;
BA_ "GenSigSendType" SG_ 2549088272 Gateway_Matrix_Generation 0;
BA_ "GenSigSwitchedByIgnition" SG_ 2549088272 Gateway_Matrix_Generation 0;
BA_ "GenSigSendType" SG_ 2549088272 Gateway_Matrix_Version 0;
BA_ "GenSigSwitchedByIgnition" SG_ 2549088272 Gateway_Matrix_Version 0;
BA_ "GenSigSendType" SG_ 2549088272 Gateway_Nachlauftyp 0;
BA_ "GenSigStartValue" SG_ 2549088272 Gateway_Nachlauftyp 2;
BA_ "GenSigSwitchedByIgnition" SG_ 2549088272 Gateway_Nachlauftyp 0;
BA_ "GenSigSendType" SG_ 2549088272 Gateway_SNI 0;
BA_ "GenSigStartValue" SG_ 2549088272 Gateway_SNI 16;
BA_ "GenSigSwitchedByIgnition" SG_ 2549088272 Gateway_SNI 0;
BA_ "GenSigSendType" SG_ 2549088272 Gateway_Transport_Mode 0;
BA_ "GenSigSwitchedByIgnition" SG_ 2549088272 Gateway_Transport_Mode 0;
BA_ "GenSigSendType" SG_ 2549088272 GW_KD_Fehler 0;
BA_ "GenSigSendType" SG_ 2549088272 NM_Gateway_Lokalaktiv 0;
BA_ "GenSigSwitchedByIgnition" SG_ 2549088272 NM_Gateway_Lokalaktiv 0;
BA_ "GenSigSendType" SG_ 2549088272 NM_Gateway_Subsystemaktiv 0;
BA_ "GenSigSendType" SG_ 2549088272 NM_Gateway_Wakeup 0;
BA_ "NWM-WakeupAllowed" SG_ 2549088272 NM_Gateway_Wakeup 1;
BA_ "GenSigSwitchedByIgnition" SG_ 2549088272 NM_Gateway_Wakeup 0;
BA_ "GenSigSendType" SG_ 2549088283 HUD_Abschaltstufe 0;
BA_ "GenSigSendType" SG_ 2549088283 HUD_KD_Fehler 0;
BA_ "GenSigSwitchedByIgnition" SG_ 2549088283 HUD_KD_Fehler 0;
BA_ "GenSigSendType" SG_ 2549088283 HUD_KompSchutz 0;
BA_ "GenSigSwitchedByIgnition" SG_ 2549088283 HUD_KompSchutz 0;
BA_ "GenSigSendType" SG_ 2549088283 HUD_Nachlauftyp 0;
BA_ "GenSigStartValue" SG_ 2549088283 HUD_Nachlauftyp 2;
BA_ "GenSigSwitchedByIgnition" SG_ 2549088283 HUD_Nachlauftyp 0;
BA_ "GenSigSendType" SG_ 2549088283 HUD_SNI 0;
BA_ "GenSigStartValue" SG_ 2549088283 HUD_SNI 27;
BA_ "GenSigSwitchedByIgnition" SG_ 2549088283 HUD_SNI 0;
BA_ "GenSigSendType" SG_ 2549088283 HUD_Transport_Mode 0;
BA_ "GenSigSwitchedByIgnition" SG_ 2549088283 HUD_Transport_Mode 0;
BA_ "GenSigSendType" SG_ 2549088283 KN_HUD_BusKnockOut 0;
BA_ "GenSigSwitchedByIgnition" SG_ 2549088283 KN_HUD_BusKnockOut 0;
BA_ "GenSigSendType" SG_ 2549088283 KN_HUD_BusKnockOutTimer 0;
BA_ "GenSigSwitchedByIgnition" SG_ 2549088283 KN_HUD_BusKnockOutTimer 0;
BA_ "GenSigSendType" SG_ 2549088283 KN_HUD_ECUKnockOut 0;
BA_ "GenSigSwitchedByIgnition" SG_ 2549088283 KN_HUD_ECUKnockOut 0;
BA_ "GenSigSendType" SG_ 2549088283 KN_HUD_ECUKnockOutTimer 0;
BA_ "GenSigSwitchedByIgnition" SG_ 2549088283 KN_HUD_ECUKnockOutTimer 0;
BA_ "GenSigSendType" SG_ 2549088283 NM_HUD_Lokalaktiv 0;
BA_ "GenSigSwitchedByIgnition" SG_ 2549088283 NM_HUD_Lokalaktiv 0;
BA_ "GenSigSendType" SG_ 2549088283 NM_HUD_Subsystemaktiv 0;
BA_ "GenSigSwitchedByIgnition" SG_ 2549088283 NM_HUD_Subsystemaktiv 0;
BA_ "GenSigSendType" SG_ 2549088283 NM_HUD_Wakeup 0;
BA_ "NWM-WakeupAllowed" SG_ 2549088283 NM_HUD_Wakeup 1;
BA_ "GenSigSwitchedByIgnition" SG_ 2549088283 NM_HUD_Wakeup 0;
BA_ "GenSigSendType" SG_ 2549088276 KBI_KD_Fehler 0;
BA_ "GenSigSwitchedByIgnition" SG_ 2549088276 KBI_KD_Fehler 0;
BA_ "GenSigSendType" SG_ 2549088276 KN_Kombi_BusKnockOut 0;
BA_ "GenSigSwitchedByIgnition" SG_ 2549088276 KN_Kombi_BusKnockOut 0;
BA_ "GenSigSendType" SG_ 2549088276 KN_Kombi_BusKnockOutTimer 0;
BA_ "GenSigSwitchedByIgnition" SG_ 2549088276 KN_Kombi_BusKnockOutTimer 0;
BA_ "GenSigSendType" SG_ 2549088276 KN_Kombi_ECUKnockOut 0;
BA_ "GenSigSwitchedByIgnition" SG_ 2549088276 KN_Kombi_ECUKnockOut 0;
BA_ "GenSigSendType" SG_ 2549088276 KN_Kombi_ECUKnockOutTimer 0;
BA_ "GenSigSwitchedByIgnition" SG_ 2549088276 KN_Kombi_ECUKnockOutTimer 0;
BA_ "GenSigSendType" SG_ 2549088276 Kombi_Abschaltstufe 0;
BA_ "GenSigSwitchedByIgnition" SG_ 2549088276 Kombi_Abschaltstufe 0;
BA_ "GenSigSendType" SG_ 2549088276 Kombi_KompSchutz 0;
BA_ "GenSigSwitchedByIgnition" SG_ 2549088276 Kombi_KompSchutz 0;
BA_ "GenSigSendType" SG_ 2549088276 Kombi_Nachlauftyp 0;
BA_ "GenSigStartValue" SG_ 2549088276 Kombi_Nachlauftyp 2;
BA_ "GenSigSwitchedByIgnition" SG_ 2549088276 Kombi_Nachlauftyp 0;
BA_ "GenSigSendType" SG_ 2549088276 Kombi_SNI 0;
BA_ "GenSigStartValue" SG_ 2549088276 Kombi_SNI 20;
BA_ "GenSigSwitchedByIgnition" SG_ 2549088276 Kombi_SNI 0;
BA_ "GenSigSendType" SG_ 2549088276 Kombi_Transport_Mode 0;
BA_ "GenSigSwitchedByIgnition" SG_ 2549088276 Kombi_Transport_Mode 0;
BA_ "GenSigSendType" SG_ 2549088276 NM_Kombi_Lokalaktiv 0;
BA_ "GenSigSwitchedByIgnition" SG_ 2549088276 NM_Kombi_Lokalaktiv 0;
BA_ "GenSigSendType" SG_ 2549088276 NM_Kombi_Subsystemaktiv 0;
BA_ "GenSigSwitchedByIgnition" SG_ 2549088276 NM_Kombi_Subsystemaktiv 0;
BA_ "GenSigSendType" SG_ 2549088276 NM_Kombi_Wakeup 0;
BA_ "NWM-WakeupAllowed" SG_ 2549088276 NM_Kombi_Wakeup 1;
BA_ "GenSigSwitchedByIgnition" SG_ 2549088276 NM_Kombi_Wakeup 0;
BA_ "GenSigSendType" SG_ 2549088339 KN_Waehlhebel_BusKnockOutTimer 0;
BA_ "GenSigSwitchedByIgnition" SG_ 2549088339 KN_Waehlhebel_BusKnockOutTimer 0;
BA_ "GenSigSendType" SG_ 2549088339 NM_Waehlhebel_Lokalaktiv 0;
BA_ "GenSigSwitchedByIgnition" SG_ 2549088339 NM_Waehlhebel_Lokalaktiv 0;
BA_ "GenSigSendType" SG_ 2549088339 NM_Waehlhebel_Subsystemaktiv 0;
BA_ "GenSigSwitchedByIgnition" SG_ 2549088339 NM_Waehlhebel_Subsystemaktiv 0;
BA_ "GenSigSendType" SG_ 2549088339 NM_Waehlhebel_Wakeup 0;
BA_ "NWM-WakeupAllowed" SG_ 2549088339 NM_Waehlhebel_Wakeup 1;
BA_ "GenSigSwitchedByIgnition" SG_ 2549088339 NM_Waehlhebel_Wakeup 0;
BA_ "GenSigSendType" SG_ 2549088339 Waehlhebel_Abschaltstufe 0;
BA_ "GenSigSwitchedByIgnition" SG_ 2549088339 Waehlhebel_Abschaltstufe 0;
BA_ "GenSigSendType" SG_ 2549088339 Waehlhebel_KompSchutz 0;
BA_ "GenSigSendType" SG_ 2549088339 Waehlhebel_Nachlauftyp 0;
BA_ "GenSigStartValue" SG_ 2549088339 Waehlhebel_Nachlauftyp 2;
BA_ "GenSigSwitchedByIgnition" SG_ 2549088339 Waehlhebel_Nachlauftyp 0;
BA_ "GenSigSendType" SG_ 2549088339 Waehlhebel_SNI 0;
BA_ "GenSigStartValue" SG_ 2549088339 Waehlhebel_SNI 83;
BA_ "GenSigSwitchedByIgnition" SG_ 2549088339 Waehlhebel_SNI 0;
BA_ "GenSigSendType" SG_ 2549088339 Waehlhebel_Transport_Mode 0;
BA_ "GenSigSwitchedByIgnition" SG_ 2549088339 Waehlhebel_Transport_Mode 0;
BA_ "GenSigSendType" SG_ 2549088339 WH_KD_Fehler 0;
BA_ "GenSigSwitchedByIgnition" SG_ 2549088339 WH_KD_Fehler 0;
BA_ "GenSigSendType" SG_ 779 KBI_ABS_Lampe 0;
BA_ "GenSigSwitchedByIgnition" SG_ 779 KBI_ABS_Lampe 0;
BA_ "GenSigSendType" SG_ 779 KBI_Airbag_Lampe 0;
BA_ "GenSigSwitchedByIgnition" SG_ 779 KBI_Airbag_Lampe 0;
BA_ "GenSigSendType" SG_ 779 KBI_angez_Geschw 0;
BA_ "GenSigSwitchedByIgnition" SG_ 779 KBI_angez_Geschw 0;
BA_ "GenSigSendType" SG_ 779 KBI_Anzeigefehler_LDW 0;
BA_ "GenSigSwitchedByIgnition" SG_ 779 KBI_Anzeigefehler_LDW 0;
BA_ "GenSigSendType" SG_ 779 KBI_Anzeigefehler_NV 0;
BA_ "GenSigSwitchedByIgnition" SG_ 779 KBI_Anzeigefehler_NV 0;
BA_ "GenSigSendType" SG_ 779 KBI_Anzeigefehler_SWA 0;
BA_ "GenSigSwitchedByIgnition" SG_ 779 KBI_Anzeigefehler_SWA 0;
BA_ "GenSigSendType" SG_ 779 KBI_Anzeigestatus_ACC 0;
BA_ "GenSigSwitchedByIgnition" SG_ 779 KBI_Anzeigestatus_ACC 0;
BA_ "GenSigSendType" SG_ 779 KBI_Anzeigestatus_GRA 0;
BA_ "GenSigSwitchedByIgnition" SG_ 779 KBI_Anzeigestatus_GRA 0;
BA_ "Fehlerwert" SG_ 779 KBI_Anzeigestatus_GRA 3;
BA_ "GenSigSendType" SG_ 779 KBI_Anzeigestatus_LIM 0;
BA_ "GenSigSwitchedByIgnition" SG_ 779 KBI_Anzeigestatus_LIM 0;
BA_ "Fehlerwert" SG_ 779 KBI_Anzeigestatus_LIM 3;
BA_ "GenSigSendType" SG_ 779 KBI_ARA_in_Anzeige 0;
BA_ "GenSigSwitchedByIgnition" SG_ 779 KBI_ARA_in_Anzeige 0;
BA_ "GenSigSendType" SG_ 779 KBI_Bestaetigung_ESP_Off 3;
BA_ "GenSigSwitchedByIgnition" SG_ 779 KBI_Bestaetigung_ESP_Off 0;
BA_ "GenSigSendType" SG_ 779 KBI_BKL_Lampe 0;
BA_ "GenSigSwitchedByIgnition" SG_ 779 KBI_BKL_Lampe 0;
BA_ "GenSigSendType" SG_ 779 KBI_Einheit_Tacho 0;
BA_ "GenSigSwitchedByIgnition" SG_ 779 KBI_Einheit_Tacho 0;
BA_ "GenSigSendType" SG_ 779 KBI_ESP_Lampe 0;
BA_ "GenSigSwitchedByIgnition" SG_ 779 KBI_ESP_Lampe 0;
BA_ "GenSigSendType" SG_ 779 KBI_Fehler_Anzeige_ACC 0;
BA_ "GenSigSwitchedByIgnition" SG_ 779 KBI_Fehler_Anzeige_ACC 0;
BA_ "GenSigSendType" SG_ 779 KBI_GRA_Hauptschalter 0;
BA_ "GenSigSwitchedByIgnition" SG_ 779 KBI_GRA_Hauptschalter 0;
BA_ "Fehlerwert" SG_ 779 KBI_GRA_Hauptschalter 3;
BA_ "GenSigSendType" SG_ 779 KBI_Handbremse 0;
BA_ "GenSigSwitchedByIgnition" SG_ 779 KBI_Handbremse 0;
BA_ "GenSigSendType" SG_ 779 KBI_im_Stellgliedtest 0;
BA_ "GenSigSwitchedByIgnition" SG_ 779 KBI_im_Stellgliedtest 0;
BA_ "GenSigSendType" SG_ 779 KBI_Konsistenz_ACC 0;
BA_ "GenSigSwitchedByIgnition" SG_ 779 KBI_Konsistenz_ACC 0;
BA_ "GenSigSendType" SG_ 779 KBI_Lenkung_Lampe 0;
BA_ "GenSigSwitchedByIgnition" SG_ 779 KBI_Lenkung_Lampe 0;
BA_ "GenSigSendType" SG_ 779 KBI_MFA_v_Einheit_01 0;
BA_ "GenSigSwitchedByIgnition" SG_ 779 KBI_MFA_v_Einheit_01 0;
BA_ "GenSigSendType" SG_ 779 KBI_NV_in_Anzeige 0;
BA_ "GenSigSwitchedByIgnition" SG_ 779 KBI_NV_in_Anzeige 0;
BA_ "GenSigSendType" SG_ 779 KBI_PLA_in_Anzeige 0;
BA_ "GenSigSwitchedByIgnition" SG_ 779 KBI_PLA_in_Anzeige 0;
BA_ "GenSigSendType" SG_ 779 KBI_SILA_gueltig 0;
BA_ "GenSigSwitchedByIgnition" SG_ 779 KBI_SILA_gueltig 0;
BA_ "GenSigSendType" SG_ 779 KBI_Systemstatus 0;
BA_ "GenSigSwitchedByIgnition" SG_ 779 KBI_Systemstatus 0;
BA_ "GenSigSendType" SG_ 779 KBI_Tankwarnung 0;
BA_ "GenSigSwitchedByIgnition" SG_ 779 KBI_Tankwarnung 0;
BA_ "GenSigSendType" SG_ 779 KBI_Tankwarnung_ungueltig 0;
BA_ "GenSigStartValue" SG_ 779 KBI_Tankwarnung_ungueltig 1;
BA_ "GenSigSwitchedByIgnition" SG_ 779 KBI_Tankwarnung_ungueltig 0;
BA_ "GenSigSendType" SG_ 779 KBI_Taster_Fahrwerk 0;
BA_ "GenSigSwitchedByIgnition" SG_ 779 KBI_Taster_Fahrwerk 0;
BA_ "GenSigSendType" SG_ 779 KBI_Taster_Lift 0;
BA_ "GenSigSwitchedByIgnition" SG_ 779 KBI_Taster_Lift 0;
BA_ "GenSigSendType" SG_ 779 KBI_V_Digital 0;
BA_ "GenSigSwitchedByIgnition" SG_ 779 KBI_V_Digital 0;
BA_ "GenSigSendType" SG_ 779 KBI_Vorglueh_System_Lampe 0;
BA_ "GenSigSwitchedByIgnition" SG_ 779 KBI_Vorglueh_System_Lampe 0;
BA_ "GenSigSendType" SG_ 779 Kombi_01_BZ 0;
BA_ "GenSigFuncType" SG_ 779 Kombi_01_BZ 1;
BA_ "GenSigSwitchedByIgnition" SG_ 779 Kombi_01_BZ 0;
BA_ "GenSigSendType" SG_ 1719 KBI_aktive_Laengsfunktion 3;
BA_ "GenSigSendType" SG_ 1719 KBI_Aussen_Temp_gef 0;
BA_ "GenSigStartValue" SG_ 1719 KBI_Aussen_Temp_gef 254;
BA_ "GenSigSwitchedByIgnition" SG_ 1719 KBI_Aussen_Temp_gef 0;
BA_ "Fehlerwert" SG_ 1719 KBI_Aussen_Temp_gef 255;
BA_ "GenSigSendType" SG_ 1719 KBI_FoD_PopUP_Quittiert 3;
BA_ "GenSigSendType" SG_ 1719 KBI_FStatus_Tank 0;
BA_ "GenSigSwitchedByIgnition" SG_ 1719 KBI_FStatus_Tank 0;
BA_ "GenSigSendType" SG_ 1719 KBI_GRA_im_ACC 3;
BA_ "GenSigSwitchedByIgnition" SG_ 1719 KBI_GRA_im_ACC 0;
BA_ "GenSigSendType" SG_ 1719 KBI_Inhalt_Tank 0;
BA_ "GenSigStartValue" SG_ 1719 KBI_Inhalt_Tank 126;
BA_ "GenSigSwitchedByIgnition" SG_ 1719 KBI_Inhalt_Tank 0;
BA_ "Fehlerwert" SG_ 1719 KBI_Inhalt_Tank 127;
BA_ "GenSigSendType" SG_ 1719 KBI_Kilometerstand 0;
BA_ "GenSigStartValue" SG_ 1719 KBI_Kilometerstand 1048574;
BA_ "GenSigSwitchedByIgnition" SG_ 1719 KBI_Kilometerstand 0;
BA_ "Fehlerwert" SG_ 1719 KBI_Kilometerstand 1048575;
BA_ "GenSigSendType" SG_ 1719 KBI_LVDS_Lock 3;
BA_ "GenSigSwitchedByIgnition" SG_ 1719 KBI_LVDS_Lock 0;
BA_ "GenSigSendType" SG_ 1719 KBI_Oelwechsel_durchgefuehrt 0;
BA_ "GenSigSwitchedByIgnition" SG_ 1719 KBI_Oelwechsel_durchgefuehrt 0;
BA_ "GenSigSendType" SG_ 1719 KBI_QBit_Aussen_Temp_gef 0;
BA_ "GenSigStartValue" SG_ 1719 KBI_QBit_Aussen_Temp_gef 1;
BA_ "GenSigSwitchedByIgnition" SG_ 1719 KBI_QBit_Aussen_Temp_gef 0;
BA_ "GenSigSendType" SG_ 1719 KBI_RDK_Kalibrier_Anf 3;
BA_ "GenSigSwitchedByIgnition" SG_ 1719 KBI_RDK_Kalibrier_Anf 0;
BA_ "GenSigSendType" SG_ 1719 KBI_Reserve_Warnung_Sek 3;
BA_ "GenSigSwitchedByIgnition" SG_ 1719 KBI_Reserve_Warnung_Sek 0;
BA_ "GenSigSendType" SG_ 1719 KBI_Standzeit_02 0;
BA_ "GenSigStartValue" SG_ 1719 KBI_Standzeit_02 131070;
BA_ "GenSigSwitchedByIgnition" SG_ 1719 KBI_Standzeit_02 0;
BA_ "Fehlerwert" SG_ 1719 KBI_Standzeit_02 131071;
BA_ "GenSigSendType" SG_ 1719 KBI_TA_gewaehlt_Fahrer 0;
BA_ "GenSigSendType" SG_ 1720 KBI_BCmE_aktiv 0;
BA_ "GenSigSwitchedByIgnition" SG_ 1720 KBI_BCmE_aktiv 0;
BA_ "GenSigSendType" SG_ 1720 KBI_GAP_Warn_Zeit_abgelaufen 0;
BA_ "GenSigSwitchedByIgnition" SG_ 1720 KBI_GAP_Warn_Zeit_abgelaufen 0;
BA_ "GenSigSendType" SG_ 1720 KBI_Max_Tankinhalt 0;
BA_ "GenSigStartValue" SG_ 1720 KBI_Max_Tankinhalt 254;
BA_ "GenSigSwitchedByIgnition" SG_ 1720 KBI_Max_Tankinhalt 0;
BA_ "Fehlerwert" SG_ 1720 KBI_Max_Tankinhalt 255;
BA_ "GenSigSendType" SG_ 1720 KBI_Nachtanken_erkannt 0;
BA_ "GenSigSwitchedByIgnition" SG_ 1720 KBI_Nachtanken_erkannt 0;
BA_ "GenSigSendType" SG_ 1720 KBI_Quittierung_cAQP 0;
BA_ "GenSigSwitchedByIgnition" SG_ 1720 KBI_Quittierung_cAQP 0;
BA_ "GenSigSendType" SG_ 1720 KBI_Quittierung_Naesse 0;
BA_ "GenSigSwitchedByIgnition" SG_ 1720 KBI_Quittierung_Naesse 0;
BA_ "GenSigSendType" SG_ 1720 KBI_Reifenumfang 0;
BA_ "GenSigFuncType" SG_ 1720 KBI_Reifenumfang 8;
BA_ "GenSigSwitchedByIgnition" SG_ 1720 KBI_Reifenumfang 0;
BA_ "GenSigSendType" SG_ 1720 KBI_Reifenumfang_Sekundaer 0;
BA_ "GenSigSwitchedByIgnition" SG_ 1720 KBI_Reifenumfang_Sekundaer 0;
BA_ "GenSigSendType" SG_ 1720 KBI_Sparhinweis_quittiert 0;
BA_ "GenSigSwitchedByIgnition" SG_ 1720 KBI_Sparhinweis_quittiert 0;
BA_ "GenSigSendType" SG_ 1720 KBI_Tankfuellstand_Prozent 0;
BA_ "GenSigStartValue" SG_ 1720 KBI_Tankfuellstand_Prozent 126;
BA_ "GenSigSwitchedByIgnition" SG_ 1720 KBI_Tankfuellstand_Prozent 0;
BA_ "Fehlerwert" SG_ 1720 KBI_Tankfuellstand_Prozent 127;
BA_ "GenSigSendType" SG_ 1720 KBI_Tankinhalt_hochaufl 0;
BA_ "GenSigStartValue" SG_ 1720 KBI_Tankinhalt_hochaufl 16382;
BA_ "GenSigSwitchedByIgnition" SG_ 1720 KBI_Tankinhalt_hochaufl 0;
BA_ "Fehlerwert" SG_ 1720 KBI_Tankinhalt_hochaufl 16383;
BA_ "GenSigSendType" SG_ 1720 KBI_Variante 0;
BA_ "GenSigSwitchedByIgnition" SG_ 1720 KBI_Variante 0;
BA_ "GenSigSendType" SG_ 1720 KBI_Variante_USA 0;
BA_ "GenSigSwitchedByIgnition" SG_ 1720 KBI_Variante_USA 0;
BA_ "GenSigSendType" SG_ 1724 KBI_Insp_dis 0;
BA_ "GenSigSwitchedByIgnition" SG_ 1724 KBI_Insp_dis 0;
BA_ "GenSigSendType" SG_ 1724 KBI_Insp_dis_status 0;
BA_ "GenSigSwitchedByIgnition" SG_ 1724 KBI_Insp_dis_status 0;
BA_ "GenSigSendType" SG_ 1724 KBI_Insp_dis_unit 0;
BA_ "GenSigSwitchedByIgnition" SG_ 1724 KBI_Insp_dis_unit 0;
BA_ "GenSigSendType" SG_ 1724 KBI_Insp_time 0;
BA_ "GenSigSwitchedByIgnition" SG_ 1724 KBI_Insp_time 0;
BA_ "GenSigSendType" SG_ 1724 KBI_Insp_time_status 0;
BA_ "GenSigSwitchedByIgnition" SG_ 1724 KBI_Insp_time_status 0;
BA_ "GenSigSendType" SG_ 1724 KBI_Oil_dis 0;
BA_ "GenSigSwitchedByIgnition" SG_ 1724 KBI_Oil_dis 0;
BA_ "GenSigSendType" SG_ 1724 KBI_Oil_dis_status 0;
BA_ "GenSigSwitchedByIgnition" SG_ 1724 KBI_Oil_dis_status 0;
BA_ "GenSigSendType" SG_ 1724 KBI_Oil_dis_unit 0;
BA_ "GenSigSwitchedByIgnition" SG_ 1724 KBI_Oil_dis_unit 0;
BA_ "GenSigSendType" SG_ 1724 KBI_Oil_time 0;
BA_ "GenSigSwitchedByIgnition" SG_ 1724 KBI_Oil_time 0;
BA_ "GenSigSendType" SG_ 1724 KBI_Oil_time_status 0;
BA_ "GenSigSwitchedByIgnition" SG_ 1724 KBI_Oil_time_status 0;
BA_ "GenSigSendType" SG_ 1724 KBI_Warnung_ID 0;
BA_ "GenSigSwitchedByIgnition" SG_ 1724 KBI_Warnung_ID 0;
BA_ "GenSigSendType" SG_ 2589283471 KBI_Signatur_Wegstrecke_01 0;
BA_ "GenSigSwitchedByIgnition" SG_ 2589283471 KBI_Signatur_Wegstrecke_01 0;
BA_ "GenSigSendType" SG_ 2589283471 KBI_Signatur_Wegstrecke_02 0;
BA_ "GenSigSwitchedByIgnition" SG_ 2589283471 KBI_Signatur_Wegstrecke_02 0;
BA_ "GenSigSendType" SG_ 2589283471 KBI_Status_Aktive_Meldungen 3;
BA_ "GenSigSwitchedByIgnition" SG_ 2589283471 KBI_Status_Aktive_Meldungen 0;
BA_ "GenSigSendType" SG_ 2589283471 KBI_Status_Historie_Meldungen 3;
BA_ "GenSigSwitchedByIgnition" SG_ 2589283471 KBI_Status_Historie_Meldungen 0;
BA_ "GenSigSendType" SG_ 2589283471 KBI_Status_SK_Meldungen 3;
BA_ "GenSigSwitchedByIgnition" SG_ 2589283471 KBI_Status_SK_Meldungen 0;
BA_ "GenSigSendType" SG_ 2589283471 KBI_Wegstrecke 0;
BA_ "GenSigStartValue" SG_ 2589283471 KBI_Wegstrecke 1048575;
BA_ "GenSigSwitchedByIgnition" SG_ 2589283471 KBI_Wegstrecke 0;
BA_ "GenSigSendType" SG_ 2527679638 KBI_GZeit_HSek 3;
BA_ "GenSigSwitchedByIgnition" SG_ 2527679638 KBI_GZeit_HSek 0;
BA_ "GenSigSendType" SG_ 2527679638 KBI_GZeit_Min 3;
BA_ "GenSigSwitchedByIgnition" SG_ 2527679638 KBI_GZeit_Min 0;
BA_ "GenSigSendType" SG_ 2527679638 KBI_GZeit_Sek 3;
BA_ "GenSigSwitchedByIgnition" SG_ 2527679638 KBI_GZeit_Sek 0;
BA_ "GenSigSendType" SG_ 2527679638 KBI_GZeit_Std 3;
BA_ "GenSigSwitchedByIgnition" SG_ 2527679638 KBI_GZeit_Std 0;
BA_ "GenSigSendType" SG_ 2527679638 KBI_RZ_Nr 3;
BA_ "GenSigSwitchedByIgnition" SG_ 2527679638 KBI_RZ_Nr 0;
BA_ "GenSigSendType" SG_ 2527679638 KBI_RZeit_HSek 3;
BA_ "GenSigSwitchedByIgnition" SG_ 2527679638 KBI_RZeit_HSek 0;
BA_ "GenSigSendType" SG_ 2527679638 KBI_RZeit_Min 3;
BA_ "GenSigSwitchedByIgnition" SG_ 2527679638 KBI_RZeit_Min 0;
BA_ "GenSigSendType" SG_ 2527679638 KBI_RZeit_Sek 3;
BA_ "GenSigSwitchedByIgnition" SG_ 2527679638 KBI_RZeit_Sek 0;
BA_ "GenSigSendType" SG_ 2527679638 KBI_RZeit_Std 3;
BA_ "GenSigSwitchedByIgnition" SG_ 2527679638 KBI_RZeit_Std 0;
BA_ "GenSigSendType" SG_ 2527679638 KBI_Status_StoppUhr 3;
BA_ "GenSigSwitchedByIgnition" SG_ 2527679638 KBI_Status_StoppUhr 0;
BA_ "GenSigSendType" SG_ 2527679639 KBI_Jokerkey 3;
BA_ "GenSigSwitchedByIgnition" SG_ 2527679639 KBI_Jokerkey 0;
BA_ "GenSigSendType" SG_ 2527679639 KBI_RS_Druck_uebernehmen 3;
BA_ "GenSigSwitchedByIgnition" SG_ 2527679639 KBI_RS_Druck_uebernehmen 0;
BA_ "GenSigSendType" SG_ 2527679639 KBI_RS_Druckauswahl_Aktiv 3;
BA_ "GenSigSwitchedByIgnition" SG_ 2527679639 KBI_RS_Druckauswahl_Aktiv 0;
BA_ "GenSigSendType" SG_ 2527679639 KBI_RS_Mode_fortsetzen 3;
BA_ "GenSigSwitchedByIgnition" SG_ 2527679639 KBI_RS_Mode_fortsetzen 0;
BA_ "GenSigSendType" SG_ 2527679639 KBI_Rundstreckenmodus 3;
BA_ "GenSigSwitchedByIgnition" SG_ 2527679639 KBI_Rundstreckenmodus 0;
BA_ "GenSigSendType" SG_ 2527679639 KBI_Weg_Zaehler 3;
BA_ "GenSigSwitchedByIgnition" SG_ 2527679639 KBI_Weg_Zaehler 0;
BA_ "GenSigSendType" SG_ 2527679639 KBI_Weg_Zaehler_F 3;
BA_ "GenSigSwitchedByIgnition" SG_ 2527679639 KBI_Weg_Zaehler_F 0;
BA_ "Fehlerwert" SG_ 2527679639 KBI_Weg_Zaehler_F 1;
BA_ "GenSigSendType" SG_ 2589283631 KBI_BC_Reset_E1 0;
BA_ "GenSigStartValue" SG_ 2589283631 KBI_BC_Reset_E1 7;
BA_ "GenSigSwitchedByIgnition" SG_ 2589283631 KBI_BC_Reset_E1 0;
BA_ "GenSigSendType" SG_ 2589283631 KBI_BC_Reset_E2 0;
BA_ "GenSigStartValue" SG_ 2589283631 KBI_BC_Reset_E2 7;
BA_ "GenSigSwitchedByIgnition" SG_ 2589283631 KBI_BC_Reset_E2 0;
BA_ "GenSigSendType" SG_ 2589283631 KBI_BC_Reset_E3 0;
BA_ "GenSigStartValue" SG_ 2589283631 KBI_BC_Reset_E3 7;
BA_ "GenSigSwitchedByIgnition" SG_ 2589283631 KBI_BC_Reset_E3 0;
BA_ "GenSigSendType" SG_ 2589283631 KBI_Kilometerstand_HiRes 0;
BA_ "GenSigSwitchedByIgnition" SG_ 2589283631 KBI_Kilometerstand_HiRes 0;
BA_ "GenSigSendType" SG_ 2589283631 KBI_Tankinhalt_roh 0;
BA_ "GenSigStartValue" SG_ 2589283631 KBI_Tankinhalt_roh 2046;
BA_ "GenSigSwitchedByIgnition" SG_ 2589283631 KBI_Tankinhalt_roh 0;
BA_ "Fehlerwert" SG_ 2589283631 KBI_Tankinhalt_roh 2047;
BA_ "GenSigSendType" SG_ 2527679656 KBI_StartupAnimation 3;
BA_ "GenSigSwitchedByIgnition" SG_ 2527679656 KBI_StartupAnimation 0;
BA_ "GenSigSendType" SG_ 1614 KBI_HUD_Data_01 3;
BA_ "GenSigSwitchedByIgnition" SG_ 1614 KBI_HUD_Data_01 0;
BA_ "GenSigSendType" SG_ 1614 KBI_HUD_Data_02 3;
BA_ "GenSigSwitchedByIgnition" SG_ 1614 KBI_HUD_Data_02 0;
BA_ "GenSigSendType" SG_ 1614 KBI_HUD_Data_03 3;
BA_ "GenSigSwitchedByIgnition" SG_ 1614 KBI_HUD_Data_03 0;
BA_ "GenSigSendType" SG_ 1614 KBI_HUD_Data_04 3;
BA_ "GenSigSwitchedByIgnition" SG_ 1614 KBI_HUD_Data_04 0;
BA_ "GenSigSendType" SG_ 1614 KBI_HUD_Data_05 3;
BA_ "GenSigSwitchedByIgnition" SG_ 1614 KBI_HUD_Data_05 0;
BA_ "GenSigSendType" SG_ 1614 KBI_HUD_Data_06 3;
BA_ "GenSigSwitchedByIgnition" SG_ 1614 KBI_HUD_Data_06 0;
BA_ "GenSigSendType" SG_ 1614 KBI_HUD_Data_07 3;
BA_ "GenSigSwitchedByIgnition" SG_ 1614 KBI_HUD_Data_07 0;
BA_ "GenSigSendType" SG_ 1614 KBI_HUD_Data_08 3;
BA_ "GenSigSwitchedByIgnition" SG_ 1614 KBI_HUD_Data_08 0;
BA_ "GenSigSendType" SG_ 2549874964 KS_Kombi_Req_Data 3;
BA_ "GenSigFuncType" SG_ 2549874964 KS_Kombi_Req_Data 9;
BA_ "GenSigSwitchedByIgnition" SG_ 2549874964 KS_Kombi_Req_Data 0;
BA_ "GenSigSendType" SG_ 2550006036 KS_Kombi_Resp_Data 3;
BA_ "GenSigFuncType" SG_ 2550006036 KS_Kombi_Resp_Data 9;
BA_ "GenSigSwitchedByIgnition" SG_ 2550006036 KS_Kombi_Resp_Data 0;
BA_ "GenSigSendType" SG_ 701 LAE_Beta_confidence 0;
BA_ "GenSigSendType" SG_ 701 LAE_Beta_VZ 0;
BA_ "GenSigSendType" SG_ 701 LAE_BetaSlipAngle 0;
BA_ "GenSigStartValue" SG_ 701 LAE_BetaSlipAngle 254;
BA_ "GenSigSwitchedByIgnition" SG_ 701 LAE_BetaSlipAngle 0;
BA_ "Fehlerwert" SG_ 701 LAE_BetaSlipAngle 255;
BA_ "GenSigSendType" SG_ 701 LAE_BetaSlipAngle_02 0;
BA_ "GenSigStartValue" SG_ 701 LAE_BetaSlipAngle_02 32766;
BA_ "GenSigSwitchedByIgnition" SG_ 701 LAE_BetaSlipAngle_02 0;
BA_ "Fehlerwert" SG_ 701 LAE_BetaSlipAngle_02 32767;
BA_ "GenSigSendType" SG_ 701 LAE_mu 0;
BA_ "GenSigStartValue" SG_ 701 LAE_mu 62;
BA_ "Fehlerwert" SG_ 701 LAE_mu 63;
BA_ "GenSigSendType" SG_ 701 LAE_mu_confidence 0;
BA_ "GenSigSendType" SG_ 701 LAE_Vx 0;
BA_ "GenSigStartValue" SG_ 701 LAE_Vx 510;
BA_ "Fehlerwert" SG_ 701 LAE_Vx 511;
BA_ "GenSigSendType" SG_ 701 LAE_Vx_confidence 0;
BA_ "GenSigSendType" SG_ 701 LAE_Vx_VZ 0;
BA_ "GenSigSendType" SG_ 701 LAE_Vy 0;
BA_ "GenSigStartValue" SG_ 701 LAE_Vy 62;
BA_ "Fehlerwert" SG_ 701 LAE_Vy 63;
BA_ "GenSigSendType" SG_ 701 LAE_Vy_confidence 0;
BA_ "GenSigSendType" SG_ 2463978818 BTM_BrakeSystem_Status 3;
BA_ "Fehlerwert" SG_ 2463978818 BTM_BrakeSystem_Status 7;
BA_ "GenSigSendType" SG_ 2463978818 BTM_BrakeSystem_Text 3;
BA_ "GenSigSendType" SG_ 2463978818 BTM_BrakeSystem_Warnlampe 3;
BA_ "GenSigSendType" SG_ 2463978818 LCV_01_BZ 0;
BA_ "GenSigFuncType" SG_ 2463978818 LCV_01_BZ 1;
BA_ "GenSigSwitchedByIgnition" SG_ 2463978818 LCV_01_BZ 0;
BA_ "GenSigSendType" SG_ 2463978818 LCV_01_CRC 0;
BA_ "GenSigFuncType" SG_ 2463978818 LCV_01_CRC 2;
BA_ "GenSigSwitchedByIgnition" SG_ 2463978818 LCV_01_CRC 0;
BA_ "GenSigSendType" SG_ 2463978818 LCV_Aero_EngineBay_Cooling 3;
BA_ "GenSigSendType" SG_ 2463978818 LCV_Aero_Front_System_Status 3;
BA_ "GenSigSendType" SG_ 2463978818 LCV_Aero_Perf_Limit 3;
BA_ "GenSigSendType" SG_ 2463978818 LCV_Aero_Perf_Limit_Speed 3;
BA_ "GenSigStartValue" SG_ 2463978818 LCV_Aero_Perf_Limit_Speed 254;
BA_ "Fehlerwert" SG_ 2463978818 LCV_Aero_Perf_Limit_Speed 255;
BA_ "GenSigSendType" SG_ 2463978818 LCV_Aero_Rear_System_Status 3;
BA_ "GenSigSendType" SG_ 2463978818 LCV_Aero_Text 0;
BA_ "GenSigSwitchedByIgnition" SG_ 2463978818 LCV_Aero_Text 0;
BA_ "GenSigSendType" SG_ 2463978818 LCV_BrakeGongTemp 3;
BA_ "GenSigSendType" SG_ 2463978818 LCV_DR_Systemstatus 3;
BA_ "GenSigSwitchedByIgnition" SG_ 2463978818 LCV_DR_Systemstatus 0;
BA_ "GenSigSendType" SG_ 2463978818 LCV_DR_Text 3;
BA_ "GenSigSwitchedByIgnition" SG_ 2463978818 LCV_DR_Text 0;
BA_ "GenSigSendType" SG_ 2463978818 LCV_DR_Warnlampe 3;
BA_ "GenSigSwitchedByIgnition" SG_ 2463978818 LCV_DR_Warnlampe 0;
BA_ "GenSigSendType" SG_ 2463978818 LCV_ESP_Zuschaltung 3;
BA_ "GenSigSendType" SG_ 2463978818 LCV_HD_offen 3;
BA_ "GenSigSwitchedByIgnition" SG_ 2463978818 LCV_HD_offen 0;
BA_ "GenSigSendType" SG_ 2463978818 LCV_Lift_Status 3;
BA_ "GenSigSwitchedByIgnition" SG_ 2463978818 LCV_Lift_Status 0;
BA_ "Fehlerwert" SG_ 2463978818 LCV_Lift_Status 7;
BA_ "GenSigSendType" SG_ 2463978818 LCV_Lift_Text 3;
BA_ "GenSigSendType" SG_ 2463978818 LCV_Lift_Warnlampe_Status 3;
BA_ "GenSigSendType" SG_ 2527679780 LCV_Aero_BarMode_Activation 3;
BA_ "GenSigSendType" SG_ 2527679780 LCV_Aero_BarMode_Activation_02 3;
BA_ "GenSigSwitchedByIgnition" SG_ 2527679780 LCV_Aero_BarMode_Activation_02 0;
BA_ "GenSigSendType" SG_ 2527679780 LCV_Aero_Button_Default 3;
BA_ "GenSigSendType" SG_ 2527679780 LCV_Aero_Button_Range 3;
BA_ "GenSigSendType" SG_ 2527679780 LCV_Aero_Button_Select 3;
BA_ "GenSigSendType" SG_ 2527679780 LCV_Aero_Button_Tunable 3;
BA_ "GenSigSendType" SG_ 2527679780 LCV_BarMode_Allowed 3;
BA_ "GenSigSendType" SG_ 2527679780 LCV_DR_Button_Default 3;
BA_ "GenSigSendType" SG_ 2527679780 LCV_DR_Button_Range 3;
BA_ "GenSigSendType" SG_ 2527679780 LCV_DR_Button_Select 3;
BA_ "GenSigSendType" SG_ 2527679780 LCV_DR_Button_Tunable 3;
BA_ "GenSigSendType" SG_ 2463978684 BTM_BrakeDiscTemp_01 0;
BA_ "GenSigStartValue" SG_ 2463978684 BTM_BrakeDiscTemp_01 254;
BA_ "Fehlerwert" SG_ 2463978684 BTM_BrakeDiscTemp_01 255;
BA_ "GenSigSendType" SG_ 2463978684 BTM_BrakeDiscTemp_02 0;
BA_ "GenSigStartValue" SG_ 2463978684 BTM_BrakeDiscTemp_02 254;
BA_ "Fehlerwert" SG_ 2463978684 BTM_BrakeDiscTemp_02 255;
BA_ "GenSigSendType" SG_ 2463978684 BTM_BrakeDiscTemp_03 0;
BA_ "GenSigStartValue" SG_ 2463978684 BTM_BrakeDiscTemp_03 254;
BA_ "Fehlerwert" SG_ 2463978684 BTM_BrakeDiscTemp_03 255;
BA_ "GenSigSendType" SG_ 2463978684 BTM_BrakeDiscTemp_04 0;
BA_ "GenSigStartValue" SG_ 2463978684 BTM_BrakeDiscTemp_04 254;
BA_ "Fehlerwert" SG_ 2463978684 BTM_BrakeDiscTemp_04 255;
BA_ "GenSigSendType" SG_ 2463978684 BTM_BrakeFluidTemp_01 0;
BA_ "GenSigStartValue" SG_ 2463978684 BTM_BrakeFluidTemp_01 254;
BA_ "Fehlerwert" SG_ 2463978684 BTM_BrakeFluidTemp_01 255;
BA_ "GenSigSendType" SG_ 2463978684 BTM_BrakeFluidTemp_02 0;
BA_ "GenSigStartValue" SG_ 2463978684 BTM_BrakeFluidTemp_02 254;
BA_ "Fehlerwert" SG_ 2463978684 BTM_BrakeFluidTemp_02 255;
BA_ "GenSigSendType" SG_ 2463978684 BTM_BrakeFluidTemp_03 0;
BA_ "GenSigStartValue" SG_ 2463978684 BTM_BrakeFluidTemp_03 254;
BA_ "Fehlerwert" SG_ 2463978684 BTM_BrakeFluidTemp_03 255;
BA_ "GenSigSendType" SG_ 2463978684 BTM_BrakeFluidTemp_04 0;
BA_ "GenSigStartValue" SG_ 2463978684 BTM_BrakeFluidTemp_04 254;
BA_ "Fehlerwert" SG_ 2463978684 BTM_BrakeFluidTemp_04 255;
BA_ "GenSigSendType" SG_ 548 LCV_Aero_Front_Ratio 0;
BA_ "GenSigStartValue" SG_ 548 LCV_Aero_Front_Ratio 126;
BA_ "Fehlerwert" SG_ 548 LCV_Aero_Front_Ratio 127;
BA_ "GenSigSendType" SG_ 548 LCV_Aero_Long_Ratio 0;
BA_ "GenSigStartValue" SG_ 548 LCV_Aero_Long_Ratio 126;
BA_ "Fehlerwert" SG_ 548 LCV_Aero_Long_Ratio 127;
BA_ "GenSigSendType" SG_ 2589283974 BTM_BrakeDiscColour_01 0;
BA_ "GenSigSwitchedByIgnition" SG_ 2589283974 BTM_BrakeDiscColour_01 0;
BA_ "Fehlerwert" SG_ 2589283974 BTM_BrakeDiscColour_01 7;
BA_ "GenSigSendType" SG_ 2589283974 BTM_BrakeDiscColour_02 0;
BA_ "GenSigSwitchedByIgnition" SG_ 2589283974 BTM_BrakeDiscColour_02 0;
BA_ "Fehlerwert" SG_ 2589283974 BTM_BrakeDiscColour_02 7;
BA_ "GenSigSendType" SG_ 2589283974 BTM_BrakeDiscColour_03 0;
BA_ "GenSigSwitchedByIgnition" SG_ 2589283974 BTM_BrakeDiscColour_03 0;
BA_ "Fehlerwert" SG_ 2589283974 BTM_BrakeDiscColour_03 7;
BA_ "GenSigSendType" SG_ 2589283974 BTM_BrakeDiscColour_04 0;
BA_ "GenSigSwitchedByIgnition" SG_ 2589283974 BTM_BrakeDiscColour_04 0;
BA_ "Fehlerwert" SG_ 2589283974 BTM_BrakeDiscColour_04 7;
BA_ "GenSigSendType" SG_ 2589283974 BTM_BrakeFluidColour_01 0;
BA_ "GenSigSwitchedByIgnition" SG_ 2589283974 BTM_BrakeFluidColour_01 0;
BA_ "Fehlerwert" SG_ 2589283974 BTM_BrakeFluidColour_01 7;
BA_ "GenSigSendType" SG_ 2589283974 BTM_BrakeFluidColour_02 0;
BA_ "GenSigSwitchedByIgnition" SG_ 2589283974 BTM_BrakeFluidColour_02 0;
BA_ "Fehlerwert" SG_ 2589283974 BTM_BrakeFluidColour_02 7;
BA_ "GenSigSendType" SG_ 2589283974 BTM_BrakeFluidColour_03 0;
BA_ "GenSigSwitchedByIgnition" SG_ 2589283974 BTM_BrakeFluidColour_03 0;
BA_ "Fehlerwert" SG_ 2589283974 BTM_BrakeFluidColour_03 7;
BA_ "GenSigSendType" SG_ 2589283974 BTM_BrakeFluidColour_04 0;
BA_ "GenSigSwitchedByIgnition" SG_ 2589283974 BTM_BrakeFluidColour_04 0;
BA_ "Fehlerwert" SG_ 2589283974 BTM_BrakeFluidColour_04 7;
BA_ "GenSigSendType" SG_ 919 aLDW_FoD_Status 3;
BA_ "GenSigSwitchedByIgnition" SG_ 919 aLDW_FoD_Status 0;
BA_ "GenSigSendType" SG_ 919 EA_Warnblinken 0;
BA_ "GenSigSendType" SG_ 919 HC_Uss_Anforderung 0;
BA_ "GenSigSwitchedByIgnition" SG_ 919 HC_Uss_Anforderung 0;
BA_ "GenSigSendType" SG_ 919 LDW_Codierinfo_fuer_VLR 0;
BA_ "GenSigSendType" SG_ 919 LDW_DLC 0;
BA_ "GenSigStartValue" SG_ 919 LDW_DLC 250;
BA_ "GenSigSendType" SG_ 919 LDW_Frueh_Spaet 0;
BA_ "GenSigStartValue" SG_ 919 LDW_Frueh_Spaet 2;
BA_ "Fehlerwert" SG_ 919 LDW_Frueh_Spaet 3;
BA_ "GenSigSendType" SG_ 919 LDW_Gong 0;
BA_ "GenSigSendType" SG_ 919 LDW_Lernmodus 0;
BA_ "Fehlerwert" SG_ 919 LDW_Lernmodus 5;
BA_ "GenSigSendType" SG_ 919 LDW_Lernmodus_seitenabhaengig 3;
BA_ "GenSigSendType" SG_ 919 LDW_Seite_DLCTLC 0;
BA_ "GenSigSendType" SG_ 919 LDW_Status_LED_gelb 0;
BA_ "GenSigSendType" SG_ 919 LDW_Status_LED_gruen 0;
BA_ "GenSigSendType" SG_ 919 LDW_Texte 0;
BA_ "GenSigSendType" SG_ 919 LDW_TLC 0;
BA_ "GenSigStartValue" SG_ 919 LDW_TLC 31;
BA_ "GenSigSendType" SG_ 919 LKS_LED_an 0;
BA_ "GenSigSendType" SG_ 810 EPS_01_BZ 0;
BA_ "GenSigFuncType" SG_ 810 EPS_01_BZ 1;
BA_ "GenSigSwitchedByIgnition" SG_ 810 EPS_01_BZ 0;
BA_ "GenSigSendType" SG_ 810 EPS_01_CRC 0;
BA_ "GenSigFuncType" SG_ 810 EPS_01_CRC 2;
BA_ "GenSigSwitchedByIgnition" SG_ 810 EPS_01_CRC 0;
BA_ "GenSigSendType" SG_ 810 EPS_Anf_KL 0;
BA_ "GenSigSwitchedByIgnition" SG_ 810 EPS_Anf_KL 0;
BA_ "GenSigSendType" SG_ 810 EPS_ARA_Status 0;
BA_ "GenSigSwitchedByIgnition" SG_ 810 EPS_ARA_Status 0;
BA_ "GenSigSendType" SG_ 810 EPS_Charisma_FahrPr 0;
BA_ "GenSigSwitchedByIgnition" SG_ 810 EPS_Charisma_FahrPr 0;
BA_ "GenSigSendType" SG_ 810 EPS_Charisma_Status 0;
BA_ "GenSigSwitchedByIgnition" SG_ 810 EPS_Charisma_Status 0;
BA_ "GenSigSendType" SG_ 810 EPS_Endanschlag 0;
BA_ "Fehlerwert" SG_ 810 EPS_Endanschlag 3;
BA_ "GenSigSendType" SG_ 810 EPS_Fehlerlampe 0;
BA_ "GenSigSwitchedByIgnition" SG_ 810 EPS_Fehlerlampe 0;
BA_ "GenSigSendType" SG_ 810 EPS_Lenkerposition 0;
BA_ "GenSigFuncType" SG_ 810 EPS_Lenkerposition 8;
BA_ "GenSigSwitchedByIgnition" SG_ 810 EPS_Lenkerposition 0;
BA_ "GenSigSendType" SG_ 810 EPS_PLA_Status 0;
BA_ "GenSigSwitchedByIgnition" SG_ 810 EPS_PLA_Status 0;
BA_ "GenSigSendType" SG_ 810 EPS_PWR_Abbruch 0;
BA_ "GenSigSwitchedByIgnition" SG_ 810 EPS_PWR_Abbruch 0;
BA_ "GenSigSendType" SG_ 810 EPS_PWR_Fehler 0;
BA_ "GenSigSwitchedByIgnition" SG_ 810 EPS_PWR_Fehler 0;
BA_ "GenSigSendType" SG_ 810 EPS_SpannungsAnf 0;
BA_ "GenSigSwitchedByIgnition" SG_ 810 EPS_SpannungsAnf 0;
BA_ "GenSigSendType" SG_ 810 EPS_Warnungen 0;
BA_ "GenSigSwitchedByIgnition" SG_ 810 EPS_Warnungen 0;
BA_ "GenSigSendType" SG_ 981 BCM1_Abblendlicht_Anf 3;
BA_ "GenSigSwitchedByIgnition" SG_ 981 BCM1_Abblendlicht_Anf 0;
BA_ "GenSigSendType" SG_ 981 BCM1_Adaptive_Lichtvert_Anf 0;
BA_ "GenSigSwitchedByIgnition" SG_ 981 BCM1_Adaptive_Lichtvert_Anf 0;
BA_ "GenSigSendType" SG_ 981 BCM1_Allwetterlicht_Anf 0;
BA_ "GenSigSwitchedByIgnition" SG_ 981 BCM1_Allwetterlicht_Anf 0;
BA_ "GenSigSendType" SG_ 981 BCM1_Animationssperrung 0;
BA_ "GenSigStartValue" SG_ 981 BCM1_Animationssperrung 1;
BA_ "GenSigSwitchedByIgnition" SG_ 981 BCM1_Animationssperrung 0;
BA_ "GenSigSendType" SG_ 981 BCM1_Autobahnlicht_Anf 0;
BA_ "GenSigSwitchedByIgnition" SG_ 981 BCM1_Autobahnlicht_Anf 0;
BA_ "GenSigSendType" SG_ 981 BCM1_CH_aktiv 0;
BA_ "NWM-WakeupAllowed" SG_ 981 BCM1_CH_aktiv 1;
BA_ "GenSigSwitchedByIgnition" SG_ 981 BCM1_CH_aktiv 0;
BA_ "GenSigSendType" SG_ 981 BCM1_CH_LH_aktiv 0;
BA_ "GenSigSwitchedByIgnition" SG_ 981 BCM1_CH_LH_aktiv 0;
BA_ "GenSigSendType" SG_ 981 BCM1_Fernlicht_Anf 0;
BA_ "GenSigSwitchedByIgnition" SG_ 981 BCM1_Fernlicht_Anf 0;
BA_ "GenSigSendType" SG_ 981 BCM1_FOD_Sperrung_Animationen_HL 3;
BA_ "GenSigStartValue" SG_ 981 BCM1_FOD_Sperrung_Animationen_HL 2;
BA_ "GenSigSendType" SG_ 981 BCM1_FoD_Sperrung_WiBli 0;
BA_ "GenSigStartValue" SG_ 981 BCM1_FoD_Sperrung_WiBli 2;
BA_ "GenSigSendType" SG_ 981 BCM1_Gleitende_Leuchtw_Anf 0;
BA_ "GenSigSwitchedByIgnition" SG_ 981 BCM1_Gleitende_Leuchtw_Anf 0;
BA_ "GenSigSendType" SG_ 981 BCM1_GLW_Fernlicht_Anf 0;
BA_ "GenSigSwitchedByIgnition" SG_ 981 BCM1_GLW_Fernlicht_Anf 0;
BA_ "GenSigSendType" SG_ 981 BCM1_Kurvenlicht_links_Anf 0;
BA_ "GenSigSwitchedByIgnition" SG_ 981 BCM1_Kurvenlicht_links_Anf 0;
BA_ "GenSigSendType" SG_ 981 BCM1_Kurvenlicht_rechts_Anf 0;
BA_ "GenSigSwitchedByIgnition" SG_ 981 BCM1_Kurvenlicht_rechts_Anf 0;
BA_ "GenSigSendType" SG_ 981 BCM1_LH_aktiv 0;
BA_ "NWM-WakeupAllowed" SG_ 981 BCM1_LH_aktiv 1;
BA_ "GenSigSwitchedByIgnition" SG_ 981 BCM1_LH_aktiv 0;
BA_ "GenSigSendType" SG_ 981 BCM1_Nebellicht_Anf 0;
BA_ "GenSigSwitchedByIgnition" SG_ 981 BCM1_Nebellicht_Anf 0;
BA_ "GenSigSendType" SG_ 981 BCM1_Nebelschluss_Ahg_Anf 0;
BA_ "GenSigSwitchedByIgnition" SG_ 981 BCM1_Nebelschluss_Ahg_Anf 0;
BA_ "GenSigSendType" SG_ 981 BCM1_Nebelschluss_Fzg_Anf 0;
BA_ "GenSigSwitchedByIgnition" SG_ 981 BCM1_Nebelschluss_Fzg_Anf 0;
BA_ "GenSigSendType" SG_ 981 BCM1_Parklicht_li_Anf 0;
BA_ "GenSigSwitchedByIgnition" SG_ 981 BCM1_Parklicht_li_Anf 0;
BA_ "GenSigSendType" SG_ 981 BCM1_Parklicht_re_Anf 0;
BA_ "GenSigSwitchedByIgnition" SG_ 981 BCM1_Parklicht_re_Anf 0;
BA_ "GenSigSendType" SG_ 981 BCM1_Regenlicht_Anf 0;
BA_ "GenSigSwitchedByIgnition" SG_ 981 BCM1_Regenlicht_Anf 0;
BA_ "GenSigSendType" SG_ 981 BCM1_Schlusslicht_Anf 0;
BA_ "GenSigSwitchedByIgnition" SG_ 981 BCM1_Schlusslicht_Anf 0;
BA_ "GenSigSendType" SG_ 981 BCM1_Schlusslicht_Signatur 0;
BA_ "GenSigSwitchedByIgnition" SG_ 981 BCM1_Schlusslicht_Signatur 0;
BA_ "GenSigSendType" SG_ 981 BCM1_Signaturlicht_Anf 0;
BA_ "GenSigSwitchedByIgnition" SG_ 981 BCM1_Signaturlicht_Anf 0;
BA_ "GenSigSendType" SG_ 981 BCM1_Standlicht_Anf 3;
BA_ "GenSigSwitchedByIgnition" SG_ 981 BCM1_Standlicht_Anf 0;
BA_ "GenSigSendType" SG_ 981 BCM1_Tagfahrlicht_Anf 0;
BA_ "GenSigSwitchedByIgnition" SG_ 981 BCM1_Tagfahrlicht_Anf 0;
BA_ "GenSigSendType" SG_ 981 BCM1_Touristen_Licht_Anf 0;
BA_ "GenSigSwitchedByIgnition" SG_ 981 BCM1_Touristen_Licht_Anf 0;
BA_ "GenSigSendType" SG_ 981 BCM1_Umfeldleuchten_Anf 0;
BA_ "GenSigSwitchedByIgnition" SG_ 981 BCM1_Umfeldleuchten_Anf 0;
BA_ "GenSigSendType" SG_ 981 BCM_Rueckfahrlicht_Anf 0;
BA_ "GenSigSwitchedByIgnition" SG_ 981 BCM_Rueckfahrlicht_Anf 0;
BA_ "GenSigSendType" SG_ 981 Licht_Anf_01_BZ 0;
BA_ "GenSigFuncType" SG_ 981 Licht_Anf_01_BZ 1;
BA_ "GenSigSwitchedByIgnition" SG_ 981 Licht_Anf_01_BZ 0;
BA_ "GenSigSendType" SG_ 981 Licht_Anf_01_CRC 0;
BA_ "GenSigFuncType" SG_ 981 Licht_Anf_01_CRC 2;
BA_ "GenSigSwitchedByIgnition" SG_ 981 Licht_Anf_01_CRC 0;
BA_ "GenSigSendType" SG_ 982 BCM2_Bremsl_durch_ECD 0;
BA_ "GenSigSwitchedByIgnition" SG_ 982 BCM2_Bremsl_durch_ECD 0;
BA_ "GenSigSendType" SG_ 982 LH_3_Bremsl_def 0;
BA_ "GenSigSwitchedByIgnition" SG_ 982 LH_3_Bremsl_def 0;
BA_ "GenSigSendType" SG_ 982 LH_Aussenlicht_def 0;
BA_ "GenSigSwitchedByIgnition" SG_ 982 LH_Aussenlicht_def 0;
BA_ "GenSigSendType" SG_ 982 LH_Blinker_HL_akt 0;
BA_ "GenSigSwitchedByIgnition" SG_ 982 LH_Blinker_HL_akt 0;
BA_ "GenSigSendType" SG_ 982 LH_Blinker_HR_akt 0;
BA_ "GenSigSwitchedByIgnition" SG_ 982 LH_Blinker_HR_akt 0;
BA_ "GenSigSendType" SG_ 982 LH_Blinker_li_def 0;
BA_ "GenSigSwitchedByIgnition" SG_ 982 LH_Blinker_li_def 0;
BA_ "GenSigSendType" SG_ 982 LH_Blinker_re_def 0;
BA_ "GenSigSwitchedByIgnition" SG_ 982 LH_Blinker_re_def 0;
BA_ "GenSigSendType" SG_ 982 LH_Brems_Blk_li_def 0;
BA_ "GenSigSwitchedByIgnition" SG_ 982 LH_Brems_Blk_li_def 0;
BA_ "GenSigSendType" SG_ 982 LH_Brems_Blk_re_def 0;
BA_ "GenSigSwitchedByIgnition" SG_ 982 LH_Brems_Blk_re_def 0;
BA_ "GenSigSendType" SG_ 982 LH_Bremsl_li_def 0;
BA_ "GenSigSwitchedByIgnition" SG_ 982 LH_Bremsl_li_def 0;
BA_ "GenSigSendType" SG_ 982 LH_Bremsl_li_ges_def 0;
BA_ "GenSigSwitchedByIgnition" SG_ 982 LH_Bremsl_li_ges_def 0;
BA_ "GenSigSendType" SG_ 982 LH_Bremsl_mi_def 0;
BA_ "GenSigSwitchedByIgnition" SG_ 982 LH_Bremsl_mi_def 0;
BA_ "GenSigSendType" SG_ 982 LH_Bremsl_re_def 0;
BA_ "GenSigSwitchedByIgnition" SG_ 982 LH_Bremsl_re_def 0;
BA_ "GenSigSendType" SG_ 982 LH_Bremsl_re_ges_def 0;
BA_ "GenSigSwitchedByIgnition" SG_ 982 LH_Bremsl_re_ges_def 0;
BA_ "GenSigSendType" SG_ 982 LH_Bremslicht_H_aktiv 0;
BA_ "GenSigSwitchedByIgnition" SG_ 982 LH_Bremslicht_H_aktiv 0;
BA_ "GenSigSendType" SG_ 982 LH_Diag_LED_li_def 0;
BA_ "GenSigSwitchedByIgnition" SG_ 982 LH_Diag_LED_li_def 0;
BA_ "GenSigSendType" SG_ 982 LH_Diag_LED_re_def 0;
BA_ "GenSigSwitchedByIgnition" SG_ 982 LH_Diag_LED_re_def 0;
BA_ "GenSigSendType" SG_ 982 LH_Diag_Status_li_def 0;
BA_ "GenSigSwitchedByIgnition" SG_ 982 LH_Diag_Status_li_def 0;
BA_ "GenSigSendType" SG_ 982 LH_Diag_Status_re_def 0;
BA_ "GenSigSwitchedByIgnition" SG_ 982 LH_Diag_Status_re_def 0;
BA_ "GenSigSendType" SG_ 982 LH_Kennzl_def 0;
BA_ "GenSigSwitchedByIgnition" SG_ 982 LH_Kennzl_def 0;
BA_ "GenSigSendType" SG_ 982 LH_Nebel_li_def 0;
BA_ "GenSigSwitchedByIgnition" SG_ 982 LH_Nebel_li_def 0;
BA_ "GenSigSendType" SG_ 982 LH_Nebel_mi_def 0;
BA_ "GenSigSwitchedByIgnition" SG_ 982 LH_Nebel_mi_def 0;
BA_ "GenSigSendType" SG_ 982 LH_Nebel_re_def 0;
BA_ "GenSigSwitchedByIgnition" SG_ 982 LH_Nebel_re_def 0;
BA_ "GenSigSendType" SG_ 982 LH_Nebelschluss_aktiv 0;
BA_ "GenSigSwitchedByIgnition" SG_ 982 LH_Nebelschluss_aktiv 0;
BA_ "GenSigSendType" SG_ 982 LH_Parklicht_HL_aktiv 0;
BA_ "GenSigSwitchedByIgnition" SG_ 982 LH_Parklicht_HL_aktiv 0;
BA_ "GenSigSendType" SG_ 982 LH_Parklicht_HR_aktiv 0;
BA_ "GenSigSwitchedByIgnition" SG_ 982 LH_Parklicht_HR_aktiv 0;
BA_ "GenSigSendType" SG_ 982 LH_Rueckf_li_def 0;
BA_ "GenSigSwitchedByIgnition" SG_ 982 LH_Rueckf_li_def 0;
BA_ "GenSigSendType" SG_ 982 LH_Rueckf_mi_def 0;
BA_ "GenSigSwitchedByIgnition" SG_ 982 LH_Rueckf_mi_def 0;
BA_ "GenSigSendType" SG_ 982 LH_Rueckf_re_def 0;
BA_ "GenSigSwitchedByIgnition" SG_ 982 LH_Rueckf_re_def 0;
BA_ "GenSigSendType" SG_ 982 LH_Rueckfahrlicht_aktiv 0;
BA_ "GenSigSwitchedByIgnition" SG_ 982 LH_Rueckfahrlicht_aktiv 0;
BA_ "GenSigSendType" SG_ 982 LH_Schluss_Brems_li_def 0;
BA_ "GenSigSwitchedByIgnition" SG_ 982 LH_Schluss_Brems_li_def 0;
BA_ "GenSigSendType" SG_ 982 LH_Schluss_Brems_mi_def 0;
BA_ "GenSigSwitchedByIgnition" SG_ 982 LH_Schluss_Brems_mi_def 0;
BA_ "GenSigSendType" SG_ 982 LH_Schluss_Brems_Nebel_li_def 0;
BA_ "GenSigSwitchedByIgnition" SG_ 982 LH_Schluss_Brems_Nebel_li_def 0;
BA_ "GenSigSendType" SG_ 982 LH_Schluss_Brems_Nebel_re_def 0;
BA_ "GenSigSwitchedByIgnition" SG_ 982 LH_Schluss_Brems_Nebel_re_def 0;
BA_ "GenSigSendType" SG_ 982 LH_Schluss_Brems_re_def 0;
BA_ "GenSigSwitchedByIgnition" SG_ 982 LH_Schluss_Brems_re_def 0;
BA_ "GenSigSendType" SG_ 982 LH_Schluss_Nebel_li_def 0;
BA_ "GenSigSwitchedByIgnition" SG_ 982 LH_Schluss_Nebel_li_def 0;
BA_ "GenSigSendType" SG_ 982 LH_Schluss_Nebel_re_def 0;
BA_ "GenSigSwitchedByIgnition" SG_ 982 LH_Schluss_Nebel_re_def 0;
BA_ "GenSigSendType" SG_ 982 LH_Schlusslicht_li_def 0;
BA_ "GenSigSwitchedByIgnition" SG_ 982 LH_Schlusslicht_li_def 0;
BA_ "GenSigSendType" SG_ 982 LH_Schlusslicht_mi_def 0;
BA_ "GenSigSwitchedByIgnition" SG_ 982 LH_Schlusslicht_mi_def 0;
BA_ "GenSigSendType" SG_ 982 LH_Schlusslicht_re_def 0;
BA_ "GenSigSwitchedByIgnition" SG_ 982 LH_Schlusslicht_re_def 0;
BA_ "GenSigSendType" SG_ 982 LH_SL_BRL_BLK_li_def 0;
BA_ "GenSigSwitchedByIgnition" SG_ 982 LH_SL_BRL_BLK_li_def 0;
BA_ "GenSigSendType" SG_ 982 LH_SL_BRL_BLK_re_def 0;
BA_ "GenSigSwitchedByIgnition" SG_ 982 LH_SL_BRL_BLK_re_def 0;
BA_ "GenSigSendType" SG_ 982 LH_Standlicht_H_aktiv 0;
BA_ "GenSigSwitchedByIgnition" SG_ 982 LH_Standlicht_H_aktiv 0;
BA_ "GenSigSendType" SG_ 982 LH_Zusatzschlussl_def 0;
BA_ "GenSigSwitchedByIgnition" SG_ 982 LH_Zusatzschlussl_def 0;
BA_REL_ "GenSigTimeoutTime" BU_SG_REL_ Gateway SG_ 2549088283 HUD_Nachlauftyp 5000;
BA_REL_ "GenSigTimeoutTime" BU_SG_REL_ Gateway SG_ 2549088283 HUD_SNI 5000;
BA_REL_ "GenSigTimeoutTime" BU_SG_REL_ Gateway SG_ 2549088283 KN_HUD_ECUKnockOutTimer 5000;
BA_REL_ "GenSigTimeoutTime" BU_SG_REL_ Gateway SG_ 2549088283 KN_HUD_ECUKnockOut 5000;
BA_REL_ "GenSigTimeoutTime" BU_SG_REL_ Gateway SG_ 2549088283 KN_HUD_BusKnockOutTimer 5000;
BA_REL_ "GenSigTimeoutTime" BU_SG_REL_ Gateway SG_ 2549088283 KN_HUD_BusKnockOut 5000;
BA_REL_ "GenSigTimeoutTime" BU_SG_REL_ Gateway SG_ 2549088283 NM_HUD_Lokalaktiv 5000;
BA_REL_ "GenSigTimeoutTime" BU_SG_REL_ Gateway SG_ 2549088283 HUD_KD_Fehler 2500;
BA_REL_ "GenSigTimeoutTime" BU_SG_REL_ Gateway SG_ 2549088276 Kombi_Nachlauftyp 5000;
BA_REL_ "GenSigTimeoutTime" BU_SG_REL_ Gateway SG_ 2549088276 Kombi_SNI 5000;
BA_REL_ "GenSigTimeoutTime" BU_SG_REL_ Gateway SG_ 2549088276 KN_Kombi_ECUKnockOutTimer 5000;
BA_REL_ "GenSigTimeoutTime" BU_SG_REL_ Gateway SG_ 2549088276 KN_Kombi_BusKnockOut 5000;
BA_REL_ "GenSigTimeoutTime" BU_SG_REL_ Gateway SG_ 2549088276 KN_Kombi_BusKnockOutTimer 5000;
BA_REL_ "GenSigTimeoutTime" BU_SG_REL_ Gateway SG_ 2549088276 KN_Kombi_ECUKnockOut 5000;
BA_REL_ "GenSigTimeoutTime" BU_SG_REL_ Gateway SG_ 2549088276 NM_Kombi_Lokalaktiv 5000;
BA_REL_ "GenSigTimeoutTime" BU_SG_REL_ Gateway SG_ 2549088276 NM_Kombi_Subsystemaktiv 5000;
BA_REL_ "GenSigTimeoutTime" BU_SG_REL_ Gateway SG_ 2549088276 KBI_KD_Fehler 2500;
BA_REL_ "GenSigTimeoutTime" BU_SG_REL_ Gateway SG_ 2549088339 Waehlhebel_Nachlauftyp 5000;
BA_REL_ "GenSigTimeoutTime" BU_SG_REL_ Gateway SG_ 2549088339 Waehlhebel_SNI 5000;
BA_REL_ "GenSigTimeoutTime" BU_SG_REL_ Gateway SG_ 2549088339 KN_Waehlhebel_BusKnockOutTimer 5000;
BA_REL_ "GenSigTimeoutTime" BU_SG_REL_ Gateway SG_ 2549088339 NM_Waehlhebel_Lokalaktiv 5000;
BA_REL_ "GenSigTimeoutTime" BU_SG_REL_ Gateway SG_ 2549088339 WH_KD_Fehler 2500;
BA_REL_ "GenSigTimeoutTime" BU_SG_REL_ Gateway SG_ 779 KBI_angez_Geschw 500;
BA_REL_ "GenSigTimeoutTime" BU_SG_REL_ Gateway SG_ 1719 KBI_Kilometerstand 5000;
BA_REL_ "GenSigTimeoutTime" BU_SG_REL_ Gateway SG_ 1719 KBI_Standzeit_02 5000;
BA_REL_ "GenSigTimeoutTime" BU_SG_REL_ Gateway SG_ 1719 KBI_Inhalt_Tank 5000;
BA_REL_ "GenSigTimeoutTime" BU_SG_REL_ Gateway SG_ 1719 KBI_FStatus_Tank 5000;
BA_REL_ "GenSigTimeoutTime" BU_SG_REL_ Gateway SG_ 1719 KBI_FoD_PopUP_Quittiert 5000;
BA_REL_ "GenSigTimeoutTime" BU_SG_REL_ Gateway SG_ 1719 KBI_QBit_Aussen_Temp_gef 5000;
BA_REL_ "GenSigTimeoutTime" BU_SG_REL_ Gateway SG_ 1719 KBI_Aussen_Temp_gef 5000;
BA_REL_ "GenSigTimeoutTime" BU_SG_REL_ Gateway SG_ 1720 KBI_Reifenumfang 5000;
BA_REL_ "GenSigTimeoutTime" BU_SG_REL_ Gateway SG_ 1720 KBI_Tankfuellstand_Prozent 5000;
BA_REL_ "GenSigTimeoutTime" BU_SG_REL_ Gateway SG_ 1720 KBI_Nachtanken_erkannt 5000;
BA_REL_ "GenSigTimeoutTime" BU_SG_REL_ Gateway SG_ 1720 KBI_Tankinhalt_hochaufl 5000;
BA_REL_ "GenSigTimeoutTime" BU_SG_REL_ Gateway SG_ 1720 KBI_Max_Tankinhalt 5000;
BA_REL_ "GenSigTimeoutTime" BU_SG_REL_ Gateway SG_ 2589283471 KBI_Status_Aktive_Meldungen 5000;
BA_REL_ "GenSigTimeoutTime" BU_SG_REL_ Gateway SG_ 2589283471 KBI_Status_Historie_Meldungen 5000;
BA_REL_ "GenSigTimeoutTime" BU_SG_REL_ Gateway SG_ 2589283471 KBI_Status_SK_Meldungen 5000;
BA_REL_ "GenSigTimeoutTime" BU_SG_REL_ Gateway SG_ 2589283631 KBI_BC_Reset_E1 5000;
BA_REL_ "GenSigTimeoutTime" BU_SG_REL_ Gateway SG_ 2589283631 KBI_BC_Reset_E2 5000;
BA_REL_ "GenSigTimeoutTime" BU_SG_REL_ Gateway SG_ 2589283631 KBI_BC_Reset_E3 5000;
BA_REL_ "GenSigTimeoutTime" BU_SG_REL_ Gateway_PAG SG_ 2549088283 HUD_Nachlauftyp 5000;
BA_REL_ "GenSigTimeoutTime" BU_SG_REL_ Gateway_PAG SG_ 2549088283 HUD_SNI 5000;
BA_REL_ "GenSigTimeoutTime" BU_SG_REL_ Gateway_PAG SG_ 2549088283 KN_HUD_ECUKnockOutTimer 5000;
BA_REL_ "GenSigTimeoutTime" BU_SG_REL_ Gateway_PAG SG_ 2549088283 KN_HUD_ECUKnockOut 5000;
BA_REL_ "GenSigTimeoutTime" BU_SG_REL_ Gateway_PAG SG_ 2549088283 KN_HUD_BusKnockOutTimer 5000;
BA_REL_ "GenSigTimeoutTime" BU_SG_REL_ Gateway_PAG SG_ 2549088283 KN_HUD_BusKnockOut 5000;
BA_REL_ "GenSigTimeoutTime" BU_SG_REL_ Gateway_PAG SG_ 2549088283 NM_HUD_Lokalaktiv 5000;
BA_REL_ "GenSigTimeoutTime" BU_SG_REL_ Gateway_PAG SG_ 2549088283 HUD_KD_Fehler 2500;
BA_REL_ "GenSigTimeoutTime" BU_SG_REL_ Gateway_PAG SG_ 2549088276 Kombi_Nachlauftyp 5000;
BA_REL_ "GenSigTimeoutTime" BU_SG_REL_ Gateway_PAG SG_ 2549088276 Kombi_SNI 5000;
BA_REL_ "GenSigTimeoutTime" BU_SG_REL_ Gateway_PAG SG_ 2549088276 KN_Kombi_ECUKnockOutTimer 5000;
BA_REL_ "GenSigTimeoutTime" BU_SG_REL_ Gateway_PAG SG_ 2549088276 KN_Kombi_BusKnockOut 5000;
BA_REL_ "GenSigTimeoutTime" BU_SG_REL_ Gateway_PAG SG_ 2549088276 KN_Kombi_BusKnockOutTimer 5000;
BA_REL_ "GenSigTimeoutTime" BU_SG_REL_ Gateway_PAG SG_ 2549088276 KN_Kombi_ECUKnockOut 5000;
BA_REL_ "GenSigTimeoutTime" BU_SG_REL_ Gateway_PAG SG_ 2549088276 NM_Kombi_Lokalaktiv 5000;
BA_REL_ "GenSigTimeoutTime" BU_SG_REL_ Gateway_PAG SG_ 2549088276 NM_Kombi_Subsystemaktiv 5000;
BA_REL_ "GenSigTimeoutTime" BU_SG_REL_ Gateway_PAG SG_ 2549088276 KBI_KD_Fehler 2500;
BA_REL_ "GenSigTimeoutTime" BU_SG_REL_ Gateway_PAG SG_ 2549088339 Waehlhebel_Nachlauftyp 5000;
BA_REL_ "GenSigTimeoutTime" BU_SG_REL_ Gateway_PAG SG_ 2549088339 Waehlhebel_SNI 5000;
BA_REL_ "GenSigTimeoutTime" BU_SG_REL_ Gateway_PAG SG_ 2549088339 KN_Waehlhebel_BusKnockOutTimer 5000;
BA_REL_ "GenSigTimeoutTime" BU_SG_REL_ Gateway_PAG SG_ 2549088339 NM_Waehlhebel_Lokalaktiv 5000;
BA_REL_ "GenSigTimeoutTime" BU_SG_REL_ Gateway_PAG SG_ 2549088339 WH_KD_Fehler 2500;
BA_REL_ "GenSigTimeoutTime" BU_SG_REL_ Gateway_PAG SG_ 779 KBI_angez_Geschw 500;
BA_REL_ "GenSigTimeoutTime" BU_SG_REL_ Gateway_PAG SG_ 1719 KBI_Kilometerstand 5000;
BA_REL_ "GenSigTimeoutTime" BU_SG_REL_ Gateway_PAG SG_ 1719 KBI_Standzeit_02 5000;
BA_REL_ "GenSigTimeoutTime" BU_SG_REL_ Gateway_PAG SG_ 1719 KBI_Inhalt_Tank 5000;
BA_REL_ "GenSigTimeoutTime" BU_SG_REL_ Gateway_PAG SG_ 1719 KBI_FStatus_Tank 5000;
BA_REL_ "GenSigTimeoutTime" BU_SG_REL_ Gateway_PAG SG_ 1719 KBI_FoD_PopUP_Quittiert 5000;
BA_REL_ "GenSigTimeoutTime" BU_SG_REL_ Gateway_PAG SG_ 1719 KBI_QBit_Aussen_Temp_gef 5000;
BA_REL_ "GenSigTimeoutTime" BU_SG_REL_ Gateway_PAG SG_ 1719 KBI_Aussen_Temp_gef 5000;
BA_REL_ "GenSigTimeoutTime" BU_SG_REL_ Gateway_PAG SG_ 1720 KBI_Reifenumfang 5000;
BA_REL_ "GenSigTimeoutTime" BU_SG_REL_ Gateway_PAG SG_ 1720 KBI_Tankfuellstand_Prozent 5000;
BA_REL_ "GenSigTimeoutTime" BU_SG_REL_ Gateway_PAG SG_ 1720 KBI_Nachtanken_erkannt 5000;
BA_REL_ "GenSigTimeoutTime" BU_SG_REL_ Gateway_PAG SG_ 1720 KBI_Tankinhalt_hochaufl 5000;
BA_REL_ "GenSigTimeoutTime" BU_SG_REL_ Gateway_PAG SG_ 1720 KBI_Max_Tankinhalt 5000;
BA_REL_ "GenSigTimeoutTime" BU_SG_REL_ Gateway_PAG SG_ 2589283471 KBI_Status_Aktive_Meldungen 5000;
BA_REL_ "GenSigTimeoutTime" BU_SG_REL_ Gateway_PAG SG_ 2589283471 KBI_Status_Historie_Meldungen 5000;
BA_REL_ "GenSigTimeoutTime" BU_SG_REL_ Gateway_PAG SG_ 2589283471 KBI_Status_SK_Meldungen 5000;
BA_REL_ "GenSigTimeoutTime" BU_SG_REL_ Gateway_PAG SG_ 2589283631 KBI_BC_Reset_E1 5000;
BA_REL_ "GenSigTimeoutTime" BU_SG_REL_ Gateway_PAG SG_ 2589283631 KBI_BC_Reset_E2 5000;
BA_REL_ "GenSigTimeoutTime" BU_SG_REL_ Gateway_PAG SG_ 2589283631 KBI_BC_Reset_E3 5000;
BA_REL_ "GenSigTimeoutTime" BU_SG_REL_ HUD SG_ 779 KBI_Anzeigestatus_ACC 500;
BA_REL_ "GenSigTimeoutTime" BU_SG_REL_ HUD SG_ 779 KBI_MFA_v_Einheit_01 500;
BA_REL_ "GenSigTimeoutTime" BU_SG_REL_ HUD SG_ 779 KBI_V_Digital 500;
BA_REL_ "GenSigTimeoutTime" BU_SG_REL_ HUD SG_ 1719 KBI_aktive_Laengsfunktion 5000;
BA_REL_ "GenSigTimeoutTime" BU_SG_REL_ HUD SG_ 1720 KBI_Variante_USA 5000;
BA_REL_ "GenSigTimeoutTime" BU_SG_REL_ HUD SG_ 1720 KBI_Variante 5000;
BA_REL_ "GenSigTimeoutTime" BU_SG_REL_ HUD SG_ 2527679638 KBI_RZ_Nr 5000;
BA_REL_ "GenSigTimeoutTime" BU_SG_REL_ HUD SG_ 2527679638 KBI_Status_StoppUhr 5000;
BA_REL_ "GenSigTimeoutTime" BU_SG_REL_ HUD SG_ 2527679638 KBI_GZeit_HSek 5000;
BA_REL_ "GenSigTimeoutTime" BU_SG_REL_ HUD SG_ 2527679638 KBI_GZeit_Min 5000;
BA_REL_ "GenSigTimeoutTime" BU_SG_REL_ HUD SG_ 2527679638 KBI_GZeit_Std 5000;
BA_REL_ "GenSigTimeoutTime" BU_SG_REL_ HUD SG_ 2527679638 KBI_GZeit_Sek 5000;
BA_REL_ "GenSigTimeoutTime" BU_SG_REL_ HUD SG_ 2527679638 KBI_RZeit_HSek 5000;
BA_REL_ "GenSigTimeoutTime" BU_SG_REL_ HUD SG_ 2527679638 KBI_RZeit_Min 5000;
BA_REL_ "GenSigTimeoutTime" BU_SG_REL_ HUD SG_ 2527679638 KBI_RZeit_Sek 5000;
BA_REL_ "GenSigTimeoutTime" BU_SG_REL_ HUD SG_ 2527679638 KBI_RZeit_Std 5000;
BA_REL_ "GenSigTimeoutTime" BU_SG_REL_ HUD SG_ 1614 KBI_HUD_Data_01 5000;
BA_REL_ "GenSigTimeoutTime" BU_SG_REL_ HUD SG_ 1614 KBI_HUD_Data_02 5000;
BA_REL_ "GenSigTimeoutTime" BU_SG_REL_ HUD SG_ 1614 KBI_HUD_Data_03 5000;
BA_REL_ "GenSigTimeoutTime" BU_SG_REL_ HUD SG_ 1614 KBI_HUD_Data_04 5000;
BA_REL_ "GenSigTimeoutTime" BU_SG_REL_ HUD SG_ 1614 KBI_HUD_Data_05 5000;
BA_REL_ "GenSigTimeoutTime" BU_SG_REL_ HUD SG_ 1614 KBI_HUD_Data_06 5000;
BA_REL_ "GenSigTimeoutTime" BU_SG_REL_ HUD SG_ 1614 KBI_HUD_Data_07 5000;
BA_REL_ "GenSigTimeoutTime" BU_SG_REL_ HUD SG_ 1614 KBI_HUD_Data_08 5000;
BA_REL_ "GenSigTimeoutTime" BU_SG_REL_ HUD SG_ 919 LDW_Texte 800;
BA_REL_ "GenSigTimeoutTime" BU_SG_REL_ HUD SG_ 919 LDW_Lernmodus 800;
BA_REL_ "GenSigTimeoutTime" BU_SG_REL_ HUD SG_ 919 LDW_Lernmodus_seitenabhaengig 800;
BA_REL_ "GenSigTimeoutTime" BU_SG_REL_ HUD SG_ 919 aLDW_FoD_Status 800;
BA_REL_ "GenSigTimeoutTime" BU_SG_REL_ HUD SG_ 919 LDW_Status_LED_gelb 800;
BA_REL_ "GenSigTimeoutTime" BU_SG_REL_ HUD SG_ 919 LDW_Status_LED_gruen 800;
BA_REL_ "GenSigTimeoutTime" BU_SG_REL_ Kombi SG_ 1640 KL_LRH_Stufe 2000;
BA_REL_ "GenSigTimeoutTime" BU_SG_REL_ Kombi SG_ 1505 BCM1_Aussen_Temp_ungef 2000;
BA_REL_ "GenSigTimeoutTime" BU_SG_REL_ Kombi SG_ 1505 BCM1_FStatus_Aussentemp_ungef 2000;
BA_REL_ "GenSigTimeoutTime" BU_SG_REL_ Kombi SG_ 919 LDW_Gong 800;
BA_REL_ "GenSigTimeoutTime" BU_SG_REL_ Kombi SG_ 919 LDW_Texte 800;
BA_REL_ "GenSigTimeoutTime" BU_SG_REL_ Kombi SG_ 919 LDW_Lernmodus 800;
BA_REL_ "GenSigTimeoutTime" BU_SG_REL_ Kombi SG_ 919 LDW_Lernmodus_seitenabhaengig 800;
BA_REL_ "GenSigTimeoutTime" BU_SG_REL_ Kombi SG_ 919 aLDW_FoD_Status 800;
BA_REL_ "GenSigTimeoutTime" BU_SG_REL_ Kombi SG_ 919 LDW_Status_LED_gelb 800;
BA_REL_ "GenSigTimeoutTime" BU_SG_REL_ Kombi SG_ 919 LDW_Status_LED_gruen 800;
BA_REL_ "GenSigTimeoutTime" BU_SG_REL_ Kombi SG_ 810 EPS_01_CRC 500;
BA_REL_ "GenSigTimeoutTime" BU_SG_REL_ Kombi SG_ 810 EPS_01_BZ 500;
BA_REL_ "GenSigTimeoutTime" BU_SG_REL_ Kombi SG_ 810 EPS_Warnungen 500;
BA_REL_ "GenSigTimeoutTime" BU_SG_REL_ Kombi SG_ 981 BCM1_Nebelschluss_Fzg_Anf 5000;
BA_REL_ "GenSigTimeoutTime" BU_SG_REL_ Kombi SG_ 981 BCM1_Schlusslicht_Anf 5000;
BA_REL_ "GenSigTimeoutTime" BU_SG_REL_ Kombi SG_ 981 BCM_Rueckfahrlicht_Anf 5000;
BA_REL_ "GenSigTimeoutTime" BU_SG_REL_ Kombi SG_ 981 BCM1_Tagfahrlicht_Anf 5000;
BA_REL_ "GenSigTimeoutTime" BU_SG_REL_ Kombi SG_ 981 BCM1_Allwetterlicht_Anf 5000;
BA_REL_ "GenSigTimeoutTime" BU_SG_REL_ Kombi SG_ 982 LH_Aussenlicht_def 1000;
BA_REL_ "GenSigTimeoutTime" BU_SG_REL_ Kombi SG_ 982 LH_Bremslicht_H_aktiv 1000;
BA_REL_ "GenSigTimeoutTime" BU_SG_REL_ Kombi SG_ 982 LH_Blinker_HR_akt 1000;
BA_REL_ "GenSigTimeoutTime" BU_SG_REL_ Kombi SG_ 982 LH_Blinker_li_def 1000;
BA_REL_ "GenSigTimeoutTime" BU_SG_REL_ Kombi SG_ 982 LH_Bremsl_li_def 1000;
BA_REL_ "GenSigTimeoutTime" BU_SG_REL_ Kombi SG_ 982 LH_Schlusslicht_li_def 1000;
BA_REL_ "GenSigTimeoutTime" BU_SG_REL_ Kombi SG_ 982 LH_Rueckf_li_def 1000;
BA_REL_ "GenSigTimeoutTime" BU_SG_REL_ Kombi SG_ 982 LH_Nebel_li_def 1000;
BA_REL_ "GenSigTimeoutTime" BU_SG_REL_ Kombi SG_ 982 LH_Schluss_Brems_Nebel_li_def 1000;
BA_REL_ "GenSigTimeoutTime" BU_SG_REL_ Kombi SG_ 982 LH_Schluss_Brems_Nebel_re_def 1000;
BA_REL_ "GenSigTimeoutTime" BU_SG_REL_ Kombi SG_ 982 LH_Zusatzschlussl_def 1000;
BA_REL_ "GenSigTimeoutTime" BU_SG_REL_ Kombi SG_ 982 LH_Schluss_Brems_li_def 1000;
BA_REL_ "GenSigTimeoutTime" BU_SG_REL_ Kombi SG_ 982 LH_Schluss_Nebel_li_def 1000;
BA_REL_ "GenSigTimeoutTime" BU_SG_REL_ Kombi SG_ 982 LH_SL_BRL_BLK_li_def 1000;
BA_REL_ "GenSigTimeoutTime" BU_SG_REL_ Kombi SG_ 982 LH_Brems_Blk_li_def 1000;
BA_REL_ "GenSigTimeoutTime" BU_SG_REL_ Kombi SG_ 982 LH_Diag_Status_re_def 1000;
BA_REL_ "GenSigTimeoutTime" BU_SG_REL_ Kombi SG_ 982 LH_Diag_Status_li_def 1000;
BA_REL_ "GenSigTimeoutTime" BU_SG_REL_ Kombi SG_ 982 LH_Diag_LED_li_def 1000;
BA_REL_ "GenSigTimeoutTime" BU_SG_REL_ Kombi SG_ 982 LH_Diag_LED_re_def 1000;
BA_REL_ "GenSigTimeoutTime" BU_SG_REL_ Kombi SG_ 982 LH_Blinker_re_def 1000;
BA_REL_ "GenSigTimeoutTime" BU_SG_REL_ Kombi SG_ 982 LH_Bremsl_re_def 1000;
BA_REL_ "GenSigTimeoutTime" BU_SG_REL_ Kombi SG_ 982 LH_Schlusslicht_re_def 1000;
BA_REL_ "GenSigTimeoutTime" BU_SG_REL_ Kombi SG_ 982 LH_Rueckf_re_def 1000;
BA_REL_ "GenSigTimeoutTime" BU_SG_REL_ Kombi SG_ 982 LH_Nebel_re_def 1000;
BA_REL_ "GenSigTimeoutTime" BU_SG_REL_ Kombi SG_ 982 LH_Schluss_Brems_mi_def 1000;
BA_REL_ "GenSigTimeoutTime" BU_SG_REL_ Kombi SG_ 982 LH_Schluss_Brems_re_def 1000;
BA_REL_ "GenSigTimeoutTime" BU_SG_REL_ Kombi SG_ 982 LH_Schluss_Nebel_re_def 1000;
BA_REL_ "GenSigTimeoutTime" BU_SG_REL_ Kombi SG_ 982 LH_SL_BRL_BLK_re_def 1000;
BA_REL_ "GenSigTimeoutTime" BU_SG_REL_ Kombi SG_ 982 LH_Brems_Blk_re_def 1000;
BA_REL_ "GenSigTimeoutTime" BU_SG_REL_ Kombi SG_ 982 LH_Kennzl_def 1000;
BA_REL_ "GenSigTimeoutTime" BU_SG_REL_ Kombi SG_ 982 LH_3_Bremsl_def 1000;
BA_REL_ "GenSigTimeoutTime" BU_SG_REL_ Kombi SG_ 982 LH_Nebel_mi_def 1000;
BA_REL_ "GenSigTimeoutTime" BU_SG_REL_ Kombi SG_ 982 LH_Rueckf_mi_def 1000;
BA_REL_ "GenSigTimeoutTime" BU_SG_REL_ Kombi SG_ 982 LH_Schlusslicht_mi_def 1000;
BA_REL_ "GenSigTimeoutTime" BU_SG_REL_ Kombi SG_ 982 LH_Bremsl_mi_def 1000;
BA_REL_ "GenSigTimeoutTime" BU_SG_REL_ Kombi SG_ 982 LH_Bremsl_li_ges_def 1000;
BA_REL_ "GenSigTimeoutTime" BU_SG_REL_ Kombi SG_ 982 LH_Bremsl_re_ges_def 1000;
BA_REL_ "GenSigTimeoutTime" BU_SG_REL_ Kombi_LB SG_ 1640 KL_LRH_Stufe 2000;
BA_REL_ "GenSigTimeoutTime" BU_SG_REL_ Kombi_LB SG_ 1505 BCM1_Aussen_Temp_ungef 2000;
BA_REL_ "GenSigTimeoutTime" BU_SG_REL_ Kombi_LB SG_ 1505 BCM1_FStatus_Aussentemp_ungef 2000;
BA_REL_ "GenSigTimeoutTime" BU_SG_REL_ Kombi_LB SG_ 701 LAE_BetaSlipAngle_02 500;
BA_REL_ "GenSigTimeoutTime" BU_SG_REL_ Kombi_LB SG_ 701 LAE_Vx_VZ 500;
BA_REL_ "GenSigTimeoutTime" BU_SG_REL_ Kombi_LB SG_ 701 LAE_mu_confidence 500;
BA_REL_ "GenSigTimeoutTime" BU_SG_REL_ Kombi_LB SG_ 701 LAE_mu 500;
BA_REL_ "GenSigTimeoutTime" BU_SG_REL_ Kombi_LB SG_ 701 LAE_Vy 500;
BA_REL_ "GenSigTimeoutTime" BU_SG_REL_ Kombi_LB SG_ 701 LAE_Vy_confidence 500;
BA_REL_ "GenSigTimeoutTime" BU_SG_REL_ Kombi_LB SG_ 701 LAE_BetaSlipAngle 500;
BA_REL_ "GenSigTimeoutTime" BU_SG_REL_ Kombi_LB SG_ 701 LAE_Beta_VZ 500;
BA_REL_ "GenSigTimeoutTime" BU_SG_REL_ Kombi_LB SG_ 701 LAE_Beta_confidence 500;
BA_REL_ "GenSigTimeoutTime" BU_SG_REL_ Kombi_LB SG_ 701 LAE_Vx_confidence 500;
BA_REL_ "GenSigTimeoutTime" BU_SG_REL_ Kombi_LB SG_ 701 LAE_Vx 500;
BA_REL_ "GenSigTimeoutTime" BU_SG_REL_ Kombi_LB SG_ 2463978818 LCV_01_CRC 3200;
BA_REL_ "GenSigTimeoutTime" BU_SG_REL_ Kombi_LB SG_ 2463978818 LCV_01_BZ 3200;
BA_REL_ "GenSigTimeoutTime" BU_SG_REL_ Kombi_LB SG_ 2463978818 LCV_ESP_Zuschaltung 3200;
BA_REL_ "GenSigTimeoutTime" BU_SG_REL_ Kombi_LB SG_ 2463978818 LCV_BrakeGongTemp 3200;
BA_REL_ "GenSigTimeoutTime" BU_SG_REL_ Kombi_LB SG_ 2463978818 BTM_BrakeSystem_Status 3200;
BA_REL_ "GenSigTimeoutTime" BU_SG_REL_ Kombi_LB SG_ 2463978818 BTM_BrakeSystem_Text 3200;
BA_REL_ "GenSigTimeoutTime" BU_SG_REL_ Kombi_LB SG_ 2463978818 BTM_BrakeSystem_Warnlampe 3200;
BA_REL_ "GenSigTimeoutTime" BU_SG_REL_ Kombi_LB SG_ 2463978818 LCV_Aero_EngineBay_Cooling 3200;
BA_REL_ "GenSigTimeoutTime" BU_SG_REL_ Kombi_LB SG_ 2463978818 LCV_Aero_Front_System_Status 3200;
BA_REL_ "GenSigTimeoutTime" BU_SG_REL_ Kombi_LB SG_ 2463978818 LCV_Aero_Rear_System_Status 3200;
BA_REL_ "GenSigTimeoutTime" BU_SG_REL_ Kombi_LB SG_ 2463978818 LCV_DR_Systemstatus 3200;
BA_REL_ "GenSigTimeoutTime" BU_SG_REL_ Kombi_LB SG_ 2463978818 LCV_DR_Text 3200;
BA_REL_ "GenSigTimeoutTime" BU_SG_REL_ Kombi_LB SG_ 2463978818 LCV_DR_Warnlampe 3200;
BA_REL_ "GenSigTimeoutTime" BU_SG_REL_ Kombi_LB SG_ 2463978818 LCV_Lift_Status 3200;
BA_REL_ "GenSigTimeoutTime" BU_SG_REL_ Kombi_LB SG_ 2463978818 LCV_Lift_Text 3200;
BA_REL_ "GenSigTimeoutTime" BU_SG_REL_ Kombi_LB SG_ 2463978818 LCV_Lift_Warnlampe_Status 3200;
BA_REL_ "GenSigTimeoutTime" BU_SG_REL_ Kombi_LB SG_ 2463978818 LCV_Aero_Perf_Limit_Speed 3200;
BA_REL_ "GenSigTimeoutTime" BU_SG_REL_ Kombi_LB SG_ 2463978818 LCV_Aero_Perf_Limit 3200;
BA_REL_ "GenSigTimeoutTime" BU_SG_REL_ Kombi_LB SG_ 2463978818 LCV_HD_offen 3200;
BA_REL_ "GenSigTimeoutTime" BU_SG_REL_ Kombi_LB SG_ 2463978818 LCV_Aero_Text 3200;
BA_REL_ "GenSigTimeoutTime" BU_SG_REL_ Kombi_LB SG_ 2527679780 LCV_Aero_BarMode_Activation_02 5000;
BA_REL_ "GenSigTimeoutTime" BU_SG_REL_ Kombi_LB SG_ 2527679780 LCV_BarMode_Allowed 5000;
BA_REL_ "GenSigTimeoutTime" BU_SG_REL_ Kombi_LB SG_ 2527679780 LCV_Aero_Button_Default 5000;
BA_REL_ "GenSigTimeoutTime" BU_SG_REL_ Kombi_LB SG_ 2527679780 LCV_Aero_Button_Range 5000;
BA_REL_ "GenSigTimeoutTime" BU_SG_REL_ Kombi_LB SG_ 2527679780 LCV_Aero_Button_Select 5000;
BA_REL_ "GenSigTimeoutTime" BU_SG_REL_ Kombi_LB SG_ 2527679780 LCV_Aero_Button_Tunable 5000;
BA_REL_ "GenSigTimeoutTime" BU_SG_REL_ Kombi_LB SG_ 2527679780 LCV_DR_Button_Default 5000;
BA_REL_ "GenSigTimeoutTime" BU_SG_REL_ Kombi_LB SG_ 2527679780 LCV_DR_Button_Range 5000;
BA_REL_ "GenSigTimeoutTime" BU_SG_REL_ Kombi_LB SG_ 2527679780 LCV_DR_Button_Select 5000;
BA_REL_ "GenSigTimeoutTime" BU_SG_REL_ Kombi_LB SG_ 2527679780 LCV_DR_Button_Tunable 5000;
BA_REL_ "GenSigTimeoutTime" BU_SG_REL_ Kombi_LB SG_ 2463978684 BTM_BrakeDiscTemp_01 1000;
BA_REL_ "GenSigTimeoutTime" BU_SG_REL_ Kombi_LB SG_ 2463978684 BTM_BrakeDiscTemp_02 1000;
BA_REL_ "GenSigTimeoutTime" BU_SG_REL_ Kombi_LB SG_ 2463978684 BTM_BrakeDiscTemp_03 1000;
BA_REL_ "GenSigTimeoutTime" BU_SG_REL_ Kombi_LB SG_ 2463978684 BTM_BrakeDiscTemp_04 1000;
BA_REL_ "GenSigTimeoutTime" BU_SG_REL_ Kombi_LB SG_ 2463978684 BTM_BrakeFluidTemp_01 1000;
BA_REL_ "GenSigTimeoutTime" BU_SG_REL_ Kombi_LB SG_ 2463978684 BTM_BrakeFluidTemp_02 1000;
BA_REL_ "GenSigTimeoutTime" BU_SG_REL_ Kombi_LB SG_ 2463978684 BTM_BrakeFluidTemp_03 1000;
BA_REL_ "GenSigTimeoutTime" BU_SG_REL_ Kombi_LB SG_ 2463978684 BTM_BrakeFluidTemp_04 1000;
BA_REL_ "GenSigTimeoutTime" BU_SG_REL_ Kombi_LB SG_ 548 LCV_Aero_Front_Ratio 500;
BA_REL_ "GenSigTimeoutTime" BU_SG_REL_ Kombi_LB SG_ 548 LCV_Aero_Long_Ratio 500;
BA_REL_ "GenSigTimeoutTime" BU_SG_REL_ Kombi_LB SG_ 2589283974 BTM_BrakeDiscColour_01 5000;
BA_REL_ "GenSigTimeoutTime" BU_SG_REL_ Kombi_LB SG_ 2589283974 BTM_BrakeDiscColour_02 5000;
BA_REL_ "GenSigTimeoutTime" BU_SG_REL_ Kombi_LB SG_ 2589283974 BTM_BrakeDiscColour_03 5000;
BA_REL_ "GenSigTimeoutTime" BU_SG_REL_ Kombi_LB SG_ 2589283974 BTM_BrakeDiscColour_04 5000;
BA_REL_ "GenSigTimeoutTime" BU_SG_REL_ Kombi_LB SG_ 2589283974 BTM_BrakeFluidColour_01 5000;
BA_REL_ "GenSigTimeoutTime" BU_SG_REL_ Kombi_LB SG_ 2589283974 BTM_BrakeFluidColour_02 5000;
BA_REL_ "GenSigTimeoutTime" BU_SG_REL_ Kombi_LB SG_ 2589283974 BTM_BrakeFluidColour_03 5000;
BA_REL_ "GenSigTimeoutTime" BU_SG_REL_ Kombi_LB SG_ 2589283974 BTM_BrakeFluidColour_04 5000;
BA_REL_ "GenSigTimeoutTime" BU_SG_REL_ Kombi_LB SG_ 919 LDW_Gong 800;
BA_REL_ "GenSigTimeoutTime" BU_SG_REL_ Kombi_LB SG_ 919 LDW_Texte 800;
BA_REL_ "GenSigTimeoutTime" BU_SG_REL_ Kombi_LB SG_ 919 LDW_Lernmodus 800;
BA_REL_ "GenSigTimeoutTime" BU_SG_REL_ Kombi_LB SG_ 919 LDW_Lernmodus_seitenabhaengig 800;
BA_REL_ "GenSigTimeoutTime" BU_SG_REL_ Kombi_LB SG_ 919 aLDW_FoD_Status 800;
BA_REL_ "GenSigTimeoutTime" BU_SG_REL_ Kombi_LB SG_ 919 LDW_Status_LED_gelb 800;
BA_REL_ "GenSigTimeoutTime" BU_SG_REL_ Kombi_LB SG_ 919 LDW_Status_LED_gruen 800;
BA_REL_ "GenSigTimeoutTime" BU_SG_REL_ Kombi_LB SG_ 810 EPS_01_CRC 500;
BA_REL_ "GenSigTimeoutTime" BU_SG_REL_ Kombi_LB SG_ 810 EPS_01_BZ 500;
BA_REL_ "GenSigTimeoutTime" BU_SG_REL_ Kombi_LB SG_ 810 EPS_Warnungen 500;
BA_REL_ "GenSigTimeoutTime" BU_SG_REL_ Kombi_LB SG_ 810 EPS_Charisma_FahrPr 500;
BA_REL_ "GenSigTimeoutTime" BU_SG_REL_ Kombi_LB SG_ 982 LH_Aussenlicht_def 1000;
BA_REL_ "GenSigTimeoutTime" BU_SG_REL_ Kombi_LB SG_ 982 LH_Blinker_HR_akt 1000;
BA_REL_ "GenSigTimeoutTime" BU_SG_REL_ Kombi_LB SG_ 982 LH_Blinker_li_def 1000;
BA_REL_ "GenSigTimeoutTime" BU_SG_REL_ Kombi_LB SG_ 982 LH_Bremsl_li_def 1000;
BA_REL_ "GenSigTimeoutTime" BU_SG_REL_ Kombi_LB SG_ 982 LH_Schlusslicht_li_def 1000;
BA_REL_ "GenSigTimeoutTime" BU_SG_REL_ Kombi_LB SG_ 982 LH_Rueckf_li_def 1000;
BA_REL_ "GenSigTimeoutTime" BU_SG_REL_ Kombi_LB SG_ 982 LH_Nebel_li_def 1000;
BA_REL_ "GenSigTimeoutTime" BU_SG_REL_ Kombi_LB SG_ 982 LH_Schluss_Brems_Nebel_li_def 1000;
BA_REL_ "GenSigTimeoutTime" BU_SG_REL_ Kombi_LB SG_ 982 LH_Schluss_Brems_Nebel_re_def 1000;
BA_REL_ "GenSigTimeoutTime" BU_SG_REL_ Kombi_LB SG_ 982 LH_Zusatzschlussl_def 1000;
BA_REL_ "GenSigTimeoutTime" BU_SG_REL_ Kombi_LB SG_ 982 LH_Schluss_Brems_li_def 1000;
BA_REL_ "GenSigTimeoutTime" BU_SG_REL_ Kombi_LB SG_ 982 LH_Schluss_Nebel_li_def 1000;
BA_REL_ "GenSigTimeoutTime" BU_SG_REL_ Kombi_LB SG_ 982 LH_SL_BRL_BLK_li_def 1000;
BA_REL_ "GenSigTimeoutTime" BU_SG_REL_ Kombi_LB SG_ 982 LH_Brems_Blk_li_def 1000;
BA_REL_ "GenSigTimeoutTime" BU_SG_REL_ Kombi_LB SG_ 982 LH_Diag_Status_re_def 1000;
BA_REL_ "GenSigTimeoutTime" BU_SG_REL_ Kombi_LB SG_ 982 LH_Diag_Status_li_def 1000;
BA_REL_ "GenSigTimeoutTime" BU_SG_REL_ Kombi_LB SG_ 982 LH_Diag_LED_li_def 1000;
BA_REL_ "GenSigTimeoutTime" BU_SG_REL_ Kombi_LB SG_ 982 LH_Diag_LED_re_def 1000;
BA_REL_ "GenSigTimeoutTime" BU_SG_REL_ Kombi_LB SG_ 982 LH_Blinker_re_def 1000;
BA_REL_ "GenSigTimeoutTime" BU_SG_REL_ Kombi_LB SG_ 982 LH_Bremsl_re_def 1000;
BA_REL_ "GenSigTimeoutTime" BU_SG_REL_ Kombi_LB SG_ 982 LH_Schlusslicht_re_def 1000;
BA_REL_ "GenSigTimeoutTime" BU_SG_REL_ Kombi_LB SG_ 982 LH_Rueckf_re_def 1000;
BA_REL_ "GenSigTimeoutTime" BU_SG_REL_ Kombi_LB SG_ 982 LH_Nebel_re_def 1000;
BA_REL_ "GenSigTimeoutTime" BU_SG_REL_ Kombi_LB SG_ 982 LH_Schluss_Brems_mi_def 1000;
BA_REL_ "GenSigTimeoutTime" BU_SG_REL_ Kombi_LB SG_ 982 LH_Schluss_Brems_re_def 1000;
BA_REL_ "GenSigTimeoutTime" BU_SG_REL_ Kombi_LB SG_ 982 LH_Schluss_Nebel_re_def 1000;
BA_REL_ "GenSigTimeoutTime" BU_SG_REL_ Kombi_LB SG_ 982 LH_SL_BRL_BLK_re_def 1000;
BA_REL_ "GenSigTimeoutTime" BU_SG_REL_ Kombi_LB SG_ 982 LH_Brems_Blk_re_def 1000;
BA_REL_ "GenSigTimeoutTime" BU_SG_REL_ Kombi_LB SG_ 982 LH_Kennzl_def 1000;
BA_REL_ "GenSigTimeoutTime" BU_SG_REL_ Kombi_LB SG_ 982 LH_3_Bremsl_def 1000;
BA_REL_ "GenSigTimeoutTime" BU_SG_REL_ Kombi_LB SG_ 982 LH_Nebel_mi_def 1000;
BA_REL_ "GenSigTimeoutTime" BU_SG_REL_ Kombi_LB SG_ 982 LH_Rueckf_mi_def 1000;
BA_REL_ "GenSigTimeoutTime" BU_SG_REL_ Kombi_LB SG_ 982 LH_Schlusslicht_mi_def 1000;
BA_REL_ "GenSigTimeoutTime" BU_SG_REL_ Kombi_LB SG_ 982 LH_Bremsl_mi_def 1000;
BA_REL_ "GenSigTimeoutTime" BU_SG_REL_ Kombi_LB SG_ 982 LH_Bremsl_li_ges_def 1000;
BA_REL_ "GenSigTimeoutTime" BU_SG_REL_ Kombi_LB SG_ 982 LH_Bremsl_re_ges_def 1000;
BA_REL_ "GenSigTimeoutTime" BU_SG_REL_ Kombi_PAG SG_ 2463978701 KL_Leistungsreduktions_Hinweis 1000;
BA_REL_ "GenSigTimeoutTime" BU_SG_REL_ Kombi_PAG SG_ 1505 BCM1_Aussen_Temp_ungef 2000;
BA_REL_ "GenSigTimeoutTime" BU_SG_REL_ Kombi_PAG SG_ 1505 BCM1_FStatus_Aussentemp_ungef 2000;
BA_REL_ "GenSigTimeoutTime" BU_SG_REL_ Kombi_PAG SG_ 919 LDW_Gong 800;
BA_REL_ "GenSigTimeoutTime" BU_SG_REL_ Kombi_PAG SG_ 919 LDW_Texte 800;
BA_REL_ "GenSigTimeoutTime" BU_SG_REL_ Kombi_PAG SG_ 919 LDW_Lernmodus 800;
BA_REL_ "GenSigTimeoutTime" BU_SG_REL_ Kombi_PAG SG_ 919 LDW_Lernmodus_seitenabhaengig 800;
BA_REL_ "GenSigTimeoutTime" BU_SG_REL_ Kombi_PAG SG_ 919 LDW_Status_LED_gelb 800;
BA_REL_ "GenSigTimeoutTime" BU_SG_REL_ Kombi_PAG SG_ 919 LDW_Status_LED_gruen 800;
BA_REL_ "GenSigTimeoutTime" BU_SG_REL_ Kombi_PAG SG_ 810 EPS_01_CRC 500;
BA_REL_ "GenSigTimeoutTime" BU_SG_REL_ Kombi_PAG SG_ 810 EPS_01_BZ 500;
BA_REL_ "GenSigTimeoutTime" BU_SG_REL_ Kombi_PAG SG_ 810 EPS_Warnungen 500;
BA_REL_ "GenSigTimeoutTime" BU_SG_REL_ Kombi_PAG SG_ 981 Licht_Anf_01_CRC 5000;
BA_REL_ "GenSigTimeoutTime" BU_SG_REL_ Kombi_PAG SG_ 981 Licht_Anf_01_BZ 5000;
BA_REL_ "GenSigTimeoutTime" BU_SG_REL_ Kombi_PAG SG_ 981 BCM1_Abblendlicht_Anf 5000;
BA_REL_ "GenSigTimeoutTime" BU_SG_REL_ Kombi_PAG SG_ 982 LH_Aussenlicht_def 1000;
BA_REL_ "GenSigTimeoutTime" BU_SG_REL_ Kombi_PAG SG_ 982 LH_Bremslicht_H_aktiv 1000;
BA_REL_ "GenSigTimeoutTime" BU_SG_REL_ Kombi_PAG SG_ 982 LH_Blinker_li_def 1000;
BA_REL_ "GenSigTimeoutTime" BU_SG_REL_ Kombi_PAG SG_ 982 LH_Bremsl_li_def 1000;
BA_REL_ "GenSigTimeoutTime" BU_SG_REL_ Kombi_PAG SG_ 982 LH_Schlusslicht_li_def 1000;
BA_REL_ "GenSigTimeoutTime" BU_SG_REL_ Kombi_PAG SG_ 982 LH_Rueckf_li_def 1000;
BA_REL_ "GenSigTimeoutTime" BU_SG_REL_ Kombi_PAG SG_ 982 LH_Nebel_li_def 1000;
BA_REL_ "GenSigTimeoutTime" BU_SG_REL_ Kombi_PAG SG_ 982 LH_Schluss_Brems_Nebel_li_def 1000;
BA_REL_ "GenSigTimeoutTime" BU_SG_REL_ Kombi_PAG SG_ 982 LH_Schluss_Brems_Nebel_re_def 1000;
BA_REL_ "GenSigTimeoutTime" BU_SG_REL_ Kombi_PAG SG_ 982 LH_Zusatzschlussl_def 1000;
BA_REL_ "GenSigTimeoutTime" BU_SG_REL_ Kombi_PAG SG_ 982 LH_Schluss_Brems_li_def 1000;
BA_REL_ "GenSigTimeoutTime" BU_SG_REL_ Kombi_PAG SG_ 982 LH_Schluss_Nebel_li_def 1000;
BA_REL_ "GenSigTimeoutTime" BU_SG_REL_ Kombi_PAG SG_ 982 LH_SL_BRL_BLK_li_def 1000;
BA_REL_ "GenSigTimeoutTime" BU_SG_REL_ Kombi_PAG SG_ 982 LH_Brems_Blk_li_def 1000;
BA_REL_ "GenSigTimeoutTime" BU_SG_REL_ Kombi_PAG SG_ 982 LH_Diag_Status_re_def 1000;
BA_REL_ "GenSigTimeoutTime" BU_SG_REL_ Kombi_PAG SG_ 982 LH_Diag_Status_li_def 1000;
BA_REL_ "GenSigTimeoutTime" BU_SG_REL_ Kombi_PAG SG_ 982 LH_Diag_LED_li_def 1000;
BA_REL_ "GenSigTimeoutTime" BU_SG_REL_ Kombi_PAG SG_ 982 LH_Diag_LED_re_def 1000;
BA_REL_ "GenSigTimeoutTime" BU_SG_REL_ Kombi_PAG SG_ 982 LH_Blinker_re_def 1000;
BA_REL_ "GenSigTimeoutTime" BU_SG_REL_ Kombi_PAG SG_ 982 LH_Bremsl_re_def 1000;
BA_REL_ "GenSigTimeoutTime" BU_SG_REL_ Kombi_PAG SG_ 982 LH_Schlusslicht_re_def 1000;
BA_REL_ "GenSigTimeoutTime" BU_SG_REL_ Kombi_PAG SG_ 982 LH_Rueckf_re_def 1000;
BA_REL_ "GenSigTimeoutTime" BU_SG_REL_ Kombi_PAG SG_ 982 LH_Nebel_re_def 1000;
BA_REL_ "GenSigTimeoutTime" BU_SG_REL_ Kombi_PAG SG_ 982 LH_Schluss_Brems_re_def 1000;
BA_REL_ "GenSigTimeoutTime" BU_SG_REL_ Kombi_PAG SG_ 982 LH_Schluss_Nebel_re_def 1000;
BA_REL_ "GenSigTimeoutTime" BU_SG_REL_ Kombi_PAG SG_ 982 LH_SL_BRL_BLK_re_def 1000;
BA_REL_ "GenSigTimeoutTime" BU_SG_REL_ Kombi_PAG SG_ 982 LH_Brems_Blk_re_def 1000;
BA_REL_ "GenSigTimeoutTime" BU_SG_REL_ Kombi_PAG SG_ 982 LH_Kennzl_def 1000;
BA_REL_ "GenSigTimeoutTime" BU_SG_REL_ Kombi_PAG SG_ 982 LH_3_Bremsl_def 1000;
BA_REL_ "GenSigTimeoutTime" BU_SG_REL_ Kombi_PAG SG_ 982 LH_Nebel_mi_def 1000;
BA_REL_ "GenSigTimeoutTime" BU_SG_REL_ Kombi_PAG SG_ 982 LH_Rueckf_mi_def 1000;
BA_REL_ "GenSigTimeoutTime" BU_SG_REL_ Kombi_PAG SG_ 982 LH_Bremsl_li_ges_def 1000;
BA_REL_ "GenSigTimeoutTime" BU_SG_REL_ Kombi_PAG SG_ 982 LH_Bremsl_re_ges_def 1000;
VAL_ 1640 KL_LRH_Taster 0 "nicht_betaetigt" 1 "betaetigt" ;
VAL_ 1640 KL_LRH_Stufe 0 "Stufe_niedrig" 1 "Stufe_mittel" 2 "Stufe_hoch" 3 "AUS" ;
VAL_ 1640 HSH_Taster 0 "nicht_betaetigt" 1 "short_push" 2 "long_push" 3 "tbd" ;
VAL_ 1640 FSH_Taster 0 "nicht_betaetigt" 1 "betaetigt" ;
VAL_ 1640 KL_Zuheizer_Freigabe 0 "keine_Freigabe_Zuheizer" 1 "Zuheizerfreigabe" ;
VAL_ 1640 KL_Beschlagsgefahr 0 "keine_Beschlagsgefahr" 1 "Beschlagsgefahr" ;
VAL_ 1640 KRH_Soll_li 0 "aus" 1 "Stufe_1" 2 "Stufe_2" 3 "Stufe_3" ;
VAL_ 1640 KRH_Soll_re 0 "aus" 1 "Stufe_1" 2 "Stufe_2" 3 "Stufe_3" ;
VAL_ 1640 KL_Geblspng_Soll 0 "0V_Motorspannung" 252 "0V_sofort_Abschalten" 253 "0V_senken_mit_Rampe" 254 "reserviert" 255 "Fehler" ;
VAL_ 1640 KL_Geblspng_Fond_Soll 0 "0V_Motorspannung" 252 "0V_sofort_Abschalten" 253 "0V_senken_mit_Rampe" 254 "reserviert" 255 "Fehler" ;
VAL_ 1640 KL_I_Geblaese 255 "Fehler" ;
VAL_ 1640 KL_Kompressorstrom_soll 1022 "Init" 1023 "Fehler" ;
VAL_ 1640 KL_Umluftklappe_Status 0 "Frischluft" 1 "Teilumluft_10" 2 "Teilumluft_20" 3 "Teilumluft_30" 4 "Teilumluft_40" 5 "Teilumluft_50" 6 "Teilumluft_60" 7 "Teilumluft_70" 8 "Teilumluft_80" 9 "Teilumluft_90" 10 "Umluft" 14 "Init" 15 "Fehler" ;
VAL_ 1640 KL_PTC_Verbauinfo 0 "kein_PTC" 1 "600W_geschaltet" 2 "1000W_geschaltet" 3 "1400W_LIN" ;
VAL_ 2463978701 KL_Temp_Soll_vr_Prognose 30 "Klima_OFF" 31 "Init" ;
VAL_ 2463978701 KL_Leistungsreduktions_Hinweis 0 "kein_Hinweis_Anzeigen" 1 "Hinweis_Anzeigen" ;
VAL_ 2463978701 KL_AC_Schalter_Prognose 0 "aus" 1 "ein" 2 "automatisiertes_an_ab_schalten" ;
VAL_ 2463978701 KL_Temp_Soll_vl_Prognose 30 "Klima_Off" 31 "Init" ;
VAL_ 2463978701 KL_Sollklimamodus_FPR_1 0 "Klima_OFF" 1 "Normal" 2 "ECO_aktiv" 3 "ECO_aktiv_AC_toggeln" 4 "FANonly" ;
VAL_ 2463978701 KL_Temp_Soll_hr_Prognose 30 "Klima_OFF" 31 "Init" ;
VAL_ 2463978701 KL_Sollklimamodus_FPR_2 0 "Klima_OFF" 1 "Normal" 2 "ECO_aktiv" 3 "ECO_aktiv_AC_toggeln" 4 "FANonly" ;
VAL_ 2463978701 KL_Temp_Soll_hl_Prognose 30 "Klima_OFF" 31 "Init" ;
VAL_ 2463978701 KL_Sollklimamodus_FPR_3 0 "Klima_OFF" 1 "Normal" 2 "ECO_aktiv" 3 "ECO_aktiv_AC_toggeln" 4 "FANonly" ;
VAL_ 1505 BCM1_Aussen_Temp_ungef 253 "nicht_verbaut" 254 "Initwert" 255 "Fehler" ;
VAL_ 1505 BCM_Heizungsabsperrventil_Status 0 "HAV_offen" 1 "HAV_geschlossen" 2 "Init_oder_nicht_verbaut" 3 "Fehler" ;
VAL_ 1505 BCM_Heizungspumpe_Status 0 "Pumpe_aus" 1 "Pumpe_aktiv_und_Stauts_iO" 2 "Init_oder_nicht_verbaut" 3 "Fehler" ;
VAL_ 1505 BCM_Kompressorkupplung_Status 0 "Kupplung_offen" 1 "Kupplung_geschlossen" 2 "Init_oder_nicht_verbaut" 3 "Fehler" ;
VAL_ 1505 BCM1_PTC_stufig_Status 0 "Aus" 1 "Stufe_1_aktiv" 2 "Stufe_2_aktiv" 3 "Stufe_3_aktiv" 6 "Init_oder_nicht_verbaut" 7 "Fehler" ;
VAL_ 1505 BCM1_FStatus_Aussentemp_ungef 0 "iO" 1 "niO" ;
VAL_ 1505 BCM1_Kompressorstrom_ist 254 "Init, bzw. nicht verfuegbar" 255 "Fehler" ;
VAL_ 1505 BCM1_OBD_FStatus_ATemp 0 "kein Fehler / Init / nicht verbaut" 1 "KS- (Kurzschluss nach minus)" 2 "KS+ (Kurzschluss nach plus)" 3 "OC (Leitungsunterbrechung)" 4 "OOR+ (Signal zu gross)" 5 "OOR- (Signal zu klein)" 6 "RC+ (Signal unplausibel zu gross)" 7 "RC- (Signal unplausibel zu klein)" 8 "KS+/OC (Kurzschluss nach plus/Unterbrechung)" 9 "KS-/OC  (Kurzschluss nach minus/Unterbrechung)" 10 "KS-/KS+  (Kurzschluss nach minus/plus)" 11 "KS-/KS+/OC (Kurzschluss nach minus/plus/Unterbrechung)" 12 "frei" 13 "frei" 14 "frei" 15 "frei" ;
VAL_ 2549088272 Gateway_KompSchutz 0 "inaktiv" 1 "aktiv" ;
VAL_ 2549088272 Gateway_Abschaltstufe 0 "keine_Einschraenkung" 1 "Funktionseinschraenkung" ;
VAL_ 2549088272 Gateway_Transport_Mode 0 "keine_Einschraenkung" 1 "Funktionseinschraenkung" ;
VAL_ 2549088272 Gateway_Nachlauftyp 0 "Komm_bei_KL15_EIN" 1 "Komm_nach_KL15_AUS" 2 "Komm_bei_KL15_AUS" ;
VAL_ 2549088272 Gateway_SNI 16 "Gateway" ;
VAL_ 2549088272 NM_Gateway_Wakeup 0 "Peripherie_Wakeup__Ursache_nicht_bekannt" 1 "Bus_Wakeup" 2 "KL15_HW" 3 "ACAN_Wakeup" 4 "FCAN_Wakeup" 5 "KCAN_Wakeup" 6 "ICAN_Wakeup" 7 "DiagCAN_Wakeup" 8 "ECAN_Wakeup" 9 "Energie_LIN_Wakeup" 10 "Bedien_LIN_Wakeup" 11 "HybridCAN_Wakeup" 12 "Flexray_Wakeup" 13 "MFL_WakeUp" 14 "Ethernet" 15 "DCAN_Wakeup" 16 "K2CAN_Wakeup" 17 "CCAN" 18 "AFSCAN_Wakeup" 19 "LIN1" 20 "LIN2" 21 "LIN3" 22 "LIN4" 23 "LIN5" 24 "LIN6" 25 "FASCAN" 26 "FAS2CAN" 27 "MDKCAN" 32 "FlexRay_Branch1_WakeUp" 33 "FlexRay_Branch2_WakeUp" 34 "FlexRay_Branch3_WakeUp" 35 "FlexRay_Branch4_WakeUp" 36 "FlexRay_Branch5_WakeUp" 37 "FlexRay_Branch6_WakeUp" 38 "FlexRay_Branch7_WakeUp" 39 "FlexRay_Branch8_WakeUp" 40 "FlexRay_Branch9_WakeUp" 41 "FlexRay_Branch10_WakeUp" 42 "FlexRay_Branch11_WakeUp" 43 "FlexRay_Branch12_WakeUp" 44 "FlexRay_Branch13_WakeUp" 45 "FlexRay_Branch14_WakeUp" 46 "FlexRay_Branch15_WakeUp" 47 "FlexRay_Branch16_WakeUp" 128 "Energiemanagement" 129 "Funktionswakeup_OBDC" 130 "Hochvoltenergiemanagement" 131 "CWU_empfangen" 132 "Fuer_Bus_relevanten_FC_empfangen" 133 "OnlineDienst_empfangen" 134 "HV_Aktivieren" 135 "HV_Deaktivieren" 136 "VTS_Suche_DriverCard" 137 "VTS_Hupen_Blinken" 138 "Remote_Vehicle_Status" 139 "Plug_and_Charge" 140 "VTS_Wakeup_Infotainment" 141 "EMHLR" 142 "NFcGW_fordert_OTA_FC_an" 143 "Komponentenschutz" 144 "UserStateServer" 145 "Dimmung" 146 "Kessy" 147 "StandardAussenlicht" 148 "ParkKoordinator" 149 "HVLMDynamicChargingPOI" 150 "HVLMChargingManagementServer" 151 "HVLMExtendedChargingMonitoring" 152 "Zentralverriegelung" 153 "FunctionOnDemand" 154 "IAA" 155 "StandKlimatisierung" 156 "RealTimeMonitor" 157 "Klemmensteuerung" 158 "Fremdladung_erkannt" ;
VAL_ 2549088272 NM_Gateway_Lokalaktiv 0 "war_nicht_lokal_aktiv" 1 "war_lokal_aktiv" ;
VAL_ 2549088272 NM_Gateway_Subsystemaktiv 0 "Subsystem_war_nicht_lokalaktiv" 1 "war_lokalaktiv" ;
VAL_ 2549088272 GW_KD_Fehler 0 "kein_KD_Fehler" 1 "KD_Fehler" ;
VAL_ 2549088283 HUD_KompSchutz 0 "inaktiv" 1 "aktiv" ;
VAL_ 2549088283 HUD_Abschaltstufe 0 "keine_Einschraenkung" 1 "Funktionseinschraenkung" ;
VAL_ 2549088283 HUD_Transport_Mode 0 "keine_Einschraenkung" 1 "Funktionseinschraenkung" ;
VAL_ 2549088283 HUD_Nachlauftyp 0 "Komm_bei_KL15_EIN" 1 "Komm_nach_KL15_AUS" 2 "Komm_bei_KL15_AUS" ;
VAL_ 2549088283 HUD_SNI 27 "HUD" ;
VAL_ 2549088283 KN_HUD_ECUKnockOutTimer 63 "ECUKnockOut_deaktiviert" ;
VAL_ 2549088283 KN_HUD_ECUKnockOut 0 "Funktion_nicht_ausgeloest" 1 "Veto_war_aktiv" 2 "Funktion_ausgeloest" 3 "Funktion_deaktiviert" ;
VAL_ 2549088283 KN_HUD_BusKnockOutTimer 255 "BusKnockOut_deaktiviert" ;
VAL_ 2549088283 NM_HUD_Wakeup 0 "Peripherie_Wakeup_Ursache_nicht_bekannt" 1 "Bus_Wakeup" 2 "KL15_HW" ;
VAL_ 2549088283 KN_HUD_BusKnockOut 0 "Funktion_nicht_ausgeloest" 1 "Veto_aktiv" 2 "Funktion_ausgeloest" 3 "Funktion_deaktiviert" ;
VAL_ 2549088283 NM_HUD_Lokalaktiv 0 "war_nicht_lokal_aktiv" 1 "war_lokal_aktiv" ;
VAL_ 2549088283 NM_HUD_Subsystemaktiv 0 "war_nicht_lokal_aktiv" 1 "war_lokal_aktiv" ;
VAL_ 2549088283 HUD_KD_Fehler 0 "Kein_KD_Fehler" 1 "KD_Fehler" ;
VAL_ 2549088276 Kombi_KompSchutz 0 "inaktiv" 1 "aktiv" ;
VAL_ 2549088276 Kombi_Abschaltstufe 0 "keine_Einschraenkung" 1 "Funktionseinschraenkung" ;
VAL_ 2549088276 Kombi_Transport_Mode 0 "keine_Einschraenkung" 1 "Funktionseinschraenkung" ;
VAL_ 2549088276 Kombi_Nachlauftyp 0 "Komm_bei_KL15_EIN" 1 "Komm_nach_KL15_AUS" 2 "Komm_bei_KL15_AUS" ;
VAL_ 2549088276 Kombi_SNI 20 "Kombi" ;
VAL_ 2549088276 KN_Kombi_ECUKnockOutTimer 63 "ECUKnockOut_deaktiviert" ;
VAL_ 2549088276 KN_Kombi_BusKnockOut 0 "Funktion_nicht_ausgeloest" 1 "Veto_aktiv" 2 "Funktion_ausgeloest" 3 "Funktion_deaktiviert" ;
VAL_ 2549088276 KN_Kombi_BusKnockOutTimer 255 "BusKnockOut_deaktiviert" ;
VAL_ 2549088276 NM_Kombi_Wakeup 0 "Peripherie_Wakeup__Ursache_nicht_bekannt" 1 "Bus_Wakeup" 2 "KL15_HW" 3 "KL30_Reset" 128 "Timer_abgelaufen" ;
VAL_ 2549088276 KN_Kombi_ECUKnockOut 0 "Funktion_nicht_ausgeloest" 1 "Veto_war_aktiv" 2 "Funktion_ausgeloest" 3 "Funktion_deaktiviert" ;
VAL_ 2549088276 NM_Kombi_Lokalaktiv 0 "war_nicht_lokal_aktiv" 1 "war_lokal_aktiv" ;
VAL_ 2549088276 NM_Kombi_Subsystemaktiv 0 "Subsystem_war_nicht_lokalaktiv" 1 "war_lokalaktiv" ;
VAL_ 2549088276 KBI_KD_Fehler 0 "kein_KD_Fehler" 1 "KD_Fehler" ;
VAL_ 2549088339 Waehlhebel_KompSchutz 0 "inaktiv" 1 "aktiv" ;
VAL_ 2549088339 Waehlhebel_Abschaltstufe 0 "keine_Einschraenkung" 1 "Funktionseinschraenkung" ;
VAL_ 2549088339 Waehlhebel_Transport_Mode 0 "keine_Einschraenkung" 1 "Funktionseinschraenkung" ;
VAL_ 2549088339 Waehlhebel_Nachlauftyp 0 "Komm_bei_KL15_EIN" 1 "Komm_nach_KL15_AUS" 2 "Komm_bei_KL15_AUS" ;
VAL_ 2549088339 Waehlhebel_SNI 83 "Waehlhebel" ;
VAL_ 2549088339 KN_Waehlhebel_BusKnockOutTimer 255 "BusKnockOut_deaktiviert" ;
VAL_ 2549088339 NM_Waehlhebel_Wakeup 0 "Peripherie_Wakeup_Ursache_nicht_bekannt" 1 "Bus_Wakeup" 2 "KL15_HW" 3 "Fahrerwunsch_P" 4 "Ende_N_Haltephase" ;
VAL_ 2549088339 NM_Waehlhebel_Lokalaktiv 0 "war_nicht_lokal_aktiv" 1 "war_lokal_aktiv" ;
VAL_ 2549088339 NM_Waehlhebel_Subsystemaktiv 0 "war_nicht_lokal_aktiv" 1 "war_lokal_aktiv" ;
VAL_ 2549088339 WH_KD_Fehler 0 "kein_KD_Fehler" 1 "KD_Fehler" ;
VAL_ 779 KBI_ABS_Lampe 0 "ABS Lampe aus" 1 "ABS Lampe ein" ;
VAL_ 779 KBI_ESP_Lampe 0 "ESP Lampe aus" 1 "ESP Lampe ein" ;
VAL_ 779 KBI_BKL_Lampe 0 "BKL aus" 1 "BKL ein" ;
VAL_ 779 KBI_Airbag_Lampe 0 "Airbag Lampe aus" 1 "Airbag Lampe ein" ;
VAL_ 779 KBI_SILA_gueltig 0 "ungueltig" 1 "gueltig" ;
VAL_ 779 KBI_Vorglueh_System_Lampe 0 "Lampe aus" 1 "Lampe ein" ;
VAL_ 779 KBI_NV_in_Anzeige 0 "NV_nicht_in_Anzeige" 1 "NV_in_Anzeige" ;
VAL_ 779 KBI_Anzeigestatus_ACC 0 "keine_ACC_Anzeige" 1 "ACC_Anzeige_aktiv" ;
VAL_ 779 KBI_Anzeigestatus_GRA 0 "nicht_vorhanden" 1 "Anzeigemoeglichkeit_vorhanden" 2 "reserviert" 3 "Fehler" ;
VAL_ 779 KBI_Tankwarnung 0 "Lampe aus" 1 "Lampe ein" ;
VAL_ 779 KBI_MFA_v_Einheit_01 0 "kmh" 1 "mph" ;
VAL_ 779 KBI_im_Stellgliedtest 0 "kein Stellgliedtest" 1 "Kombi im Stellgliedtest" ;
VAL_ 779 KBI_Anzeigefehler_LDW 0 "nicht vorhanden bzw. unterstützt" 1 "Anzeige iO" 2 "Anzeigefehler" 3 "nicht definiert" ;
VAL_ 779 KBI_Tankwarnung_ungueltig 0 "KBI_Tankwarnung_gueltig" 1 "KBI_Tankwarnung_ungueltig" ;
VAL_ 779 KBI_Handbremse 0 "nicht_angezogen" 1 "angezogen" ;
VAL_ 779 KBI_PLA_in_Anzeige 0 "PLA_nicht_in_Anzeige" 1 "PLA_in_Anzeige" ;
VAL_ 779 KBI_Anzeigefehler_NV 0 "kein_Anzeigefehler" 1 "Anzeigefehler" ;
VAL_ 779 KBI_Anzeigestatus_LIM 0 "nicht_vorhanden" 1 "Anzeigemoeglichkeit_vorhanden" 2 "reserviert" 3 "Fehler" ;
VAL_ 779 KBI_ARA_in_Anzeige 0 "ARA nicht in Anzeige" 1 "ARA in Anzeige" ;
VAL_ 779 KBI_Taster_Lift 0 "nicht_betaetigt" 1 "betaetigt" ;
VAL_ 779 KBI_Taster_Fahrwerk 0 "nicht_betaetigt" 1 "betaetigt" ;
VAL_ 779 KBI_GRA_Hauptschalter 0 "Init" 1 "Hauptschalter_aus" 2 "Hauptschalter_ein" 3 "Fehler" ;
VAL_ 779 KBI_Bestaetigung_ESP_Off 0 "ESP_off_nicht_quittiert" 1 "ESP_off_quittiert" 2 "Abbruch" ;
VAL_ 779 KBI_Einheit_Tacho 0 "km/h" 1 "mph" ;
VAL_ 779 KBI_Konsistenz_ACC 0 "ACC Botschaft konsistent" 1 "ACC Botschaft inkonsistent" ;
VAL_ 779 KBI_Fehler_Anzeige_ACC 0 " iO" 1 "Anzeigefehler ACC" ;
VAL_ 779 KBI_Anzeigefehler_SWA 0 "nicht vorhanden bzw. unterstützt" 1 "Anzeige iO" 2 "Anzeigefehler" 3 "nicht definiert" ;
VAL_ 779 KBI_Systemstatus 0 "KBI_IO" 1 "KBI_System_Failure" ;
VAL_ 1719 KBI_Kilometerstand 1048574 "Init" 1048575 "Fehler" ;
VAL_ 1719 KBI_Standzeit_02 131069 "nicht_verfuegbar" 131070 "Init" 131071 "Fehler" ;
VAL_ 1719 KBI_LVDS_Lock 0 "Init_LVDS_nicht_gelockt" 1 "LVDS_gelockt" ;
VAL_ 1719 KBI_Reserve_Warnung_Sek 0 "Keine_Warnung" 1 "Sekundaere_Reservewarnung" ;
VAL_ 1719 KBI_RDK_Kalibrier_Anf 0 "keine_Kalibrieranforderung" 1 "Kalibrieranforderung" ;
VAL_ 1719 KBI_Inhalt_Tank 126 "Init" 127 "Fehler" ;
VAL_ 1719 KBI_FStatus_Tank 0 "Tankfüllstand i.O." 1 "Tankfüllstand n.i.O" ;
VAL_ 1719 KBI_aktive_Laengsfunktion 0 "Init" 1 "Speedlimiter" 2 "GRA_oder_ACC" 3 "PACCh" 4 "HDC" 5 "p_GRA" 6 "p_Lim" 7 "Umschaltung_GRA_Limiter" ;
VAL_ 1719 KBI_TA_gewaehlt_Fahrer 0 "TA_nicht_gewaehlt_Kombi" 1 "TA_gewaehlt_Kombi" ;
VAL_ 1719 KBI_FoD_PopUP_Quittiert 0 "nicht_quittiert" 1 "Meldung_quittiert" ;
VAL_ 1719 KBI_GRA_im_ACC 0 "GRA_im_ACC_nicht_ausgewaehlt" 1 "GRA_im_ACC_ausgewaehlt" ;
VAL_ 1719 KBI_Oelwechsel_durchgefuehrt 0 "Oelwechsel_nicht_durchgefuehrt" 1 "Oelwechsel_durchgefuehrt" ;
VAL_ 1719 KBI_QBit_Aussen_Temp_gef 0 "gueltiger_Wert" 1 "Ersatz_Init_oder_Fehlerwert" ;
VAL_ 1719 KBI_Aussen_Temp_gef 253 "nicht verbaut" 254 "Init" 255 "Fehler" ;
VAL_ 1720 KBI_Variante_USA 0 "keine USA-Variante" 1 "USA-Variante" ;
VAL_ 1720 KBI_Variante 0 "Zeiger Kombiinstrument" 1 "Volldisplay Kombiinstrument" ;
VAL_ 1720 KBI_GAP_Warn_Zeit_abgelaufen 0 "Zaehler_nicht_abgelaufen" 1 "Zaehler_abgelaufen" ;
VAL_ 1720 KBI_Quittierung_Naesse 0 "nicht_quittiert" 1 "quittiert" ;
VAL_ 1720 KBI_BCmE_aktiv 0 "Anzeige_nicht_aktiv" 1 "Anzeige_aktiv" ;
VAL_ 1720 KBI_Sparhinweis_quittiert 0 "nicht_quittiert" 1 "quittiert" ;
VAL_ 1720 KBI_Tankfuellstand_Prozent 126 "Init" 127 "Fehler" ;
VAL_ 1720 KBI_Nachtanken_erkannt 0 "Geberbetrieb" 1 "Nachtankmodus" ;
VAL_ 1720 KBI_Tankinhalt_hochaufl 16382 "Init" 16383 "Fehler" ;
VAL_ 1720 KBI_Max_Tankinhalt 254 "Init" 255 "Fehler" ;
VAL_ 1720 KBI_Quittierung_cAQP 0 "nicht_quittiert" 1 "quittiert" ;
VAL_ 1724 KBI_Oil_dis_status 0 "Funktion nicht verfügbar" 1 "kein Wert berechnet" 2 "Service in ..." 3 "Service seit ... " ;
VAL_ 1724 KBI_Oil_dis_unit 0 "km" 1 "Meilen" ;
VAL_ 1724 KBI_Oil_time_status 0 "Funktion nicht verfügbar" 1 "kein Wert berechnet" 2 "Service in ..." 3 "Service seit ... " ;
VAL_ 1724 KBI_Insp_dis_status 0 "Funktion nicht verfügbar" 1 "kein Wert berechnet" 2 "Service in ..." 3 "Service seit ... " ;
VAL_ 1724 KBI_Insp_dis_unit 0 "km" 1 "Meilen" ;
VAL_ 1724 KBI_Insp_time_status 0 "Funktion nicht verfügbar" 1 "kein Wert berechnet" 2 "Service in ..." 3 "Service seit ... " ;
VAL_ 2589283471 KBI_Signatur_Wegstrecke_01 0 "Init" ;
VAL_ 2589283471 KBI_Status_Aktive_Meldungen 0 "Keine_Aenderung_Init" 1 "Aenderung_aktiv" ;
VAL_ 2589283471 KBI_Status_Historie_Meldungen 0 "Keine_Aenderung_Init" 1 "Aenderung_aktiv" ;
VAL_ 2589283471 KBI_Status_SK_Meldungen 0 "Keine_Aenderung_Init" 1 "Aenderung_aktiv" ;
VAL_ 2589283471 KBI_Wegstrecke 1048575 "Init" ;
VAL_ 2589283471 KBI_Signatur_Wegstrecke_02 0 "Init" ;
VAL_ 2527679638 KBI_Status_StoppUhr 0 "init" 1 "not_running_reset" 2 "not_running_no_reset" 3 "running" ;
VAL_ 2527679639 KBI_Weg_Zaehler_F 0 "kein Fehler" 1 "Fehler" ;
VAL_ 2527679639 KBI_Jokerkey 0 "nicht_betaetigt" 1 "betaetigt" ;
VAL_ 2527679639 KBI_RS_Druck_uebernehmen 0 " Druck für Rundstreckenmodue nicht uebernehmen" 1 " Druck für Rundstreckenmodus uebernehmen" ;
VAL_ 2527679639 KBI_RS_Druckauswahl_Aktiv 0 "inaktiv" 1 "aktiv" ;
VAL_ 2527679639 KBI_RS_Mode_fortsetzen 0 "Rundstreckenmodus_nicht_fortsetzen" 1 "Rundstreckenmodus_fortsetzen" ;
VAL_ 2527679639 KBI_Rundstreckenmodus 0 "nicht_angefordert" 1 "angefordert" ;
VAL_ 2589283631 KBI_Tankinhalt_roh 2046 "Init" 2047 "Fehler" ;
VAL_ 2589283631 KBI_BC_Reset_E1 0 "SG_Reset" 1 "Reset_Zaehler" 2 "Reset_Zaehler" 3 "Reset_Zaehler" 4 "Reset_Zaehler" 5 "Reset_Zaehler" 6 "Reset_Zaehler" 7 "Init" ;
VAL_ 2589283631 KBI_BC_Reset_E2 0 "SG_Reset" 1 "Reset_Zaehler" 2 "Reset_Zaehler" 3 "Reset_Zaehler" 4 "Reset_Zaehler" 5 "Reset_Zaehler" 6 "Reset_Zaehler" 7 "Init" ;
VAL_ 2589283631 KBI_BC_Reset_E3 0 "SG_Reset" 1 "Reset_Zaehler" 2 "Reset_Zaehler" 3 "Reset_Zaehler" 4 "Reset_Zaehler" 5 "Reset_Zaehler" 6 "Reset_Zaehler" 7 "Init" ;
VAL_ 2527679656 KBI_StartupAnimation 0 "Init" 1 "StartMeasureDelay" 2 "RequestStartAnimation" 3 "RequestCancelAnimation" 4 "CIAnimationStarted" 5 "CIAnimationStopped" ;
VAL_ 1614 KBI_HUD_Data_01 0 "Init" ;
VAL_ 1614 KBI_HUD_Data_02 0 "Init" ;
VAL_ 1614 KBI_HUD_Data_03 0 "Init" ;
VAL_ 1614 KBI_HUD_Data_04 0 "Init" ;
VAL_ 1614 KBI_HUD_Data_05 0 "Init" ;
VAL_ 1614 KBI_HUD_Data_06 0 "Init" ;
VAL_ 1614 KBI_HUD_Data_07 0 "Init" ;
VAL_ 1614 KBI_HUD_Data_08 0 "Init" ;
VAL_ 701 LAE_BetaSlipAngle_02 32766 "Init" 32767 "Fehler" ;
VAL_ 701 LAE_Vx_VZ 0 "Positive" 1 "Negative" ;
VAL_ 701 LAE_mu_confidence 0 "Factor_0" 1 "Factor_1" 2 "Factor_2" 3 "Factor_3" 4 "Factor_4" 5 "Factor_5" 6 "Factor_6" 7 "Factor_7" ;
VAL_ 701 LAE_mu 62 "Init" 63 "Fehler" ;
VAL_ 701 LAE_Vy 62 "Init" 63 "Fehler" ;
VAL_ 701 LAE_Vy_confidence 0 "Factor_0" 1 "Factor_1" 2 "Factor_2" 3 "Factor_3" 4 "Factor_4" 5 "Factor_5" 6 "Factor_6" 7 "Factor_7" ;
VAL_ 701 LAE_BetaSlipAngle 254 "Init" 255 "Fehler" ;
VAL_ 701 LAE_Beta_VZ 0 "positive_links_von_der_nullst" 1 "negativ" ;
VAL_ 701 LAE_Beta_confidence 0 "Factor_0" 1 "Factor_1" 2 "Factor_2" 3 "Factor_3" 4 "Factor_4" 5 "Factor_5" 6 "Factor_6" 7 "Factor_7" ;
VAL_ 701 LAE_Vx_confidence 0 "Factor_0" 1 "Factor_1" 2 "Factor_2" 3 "Factor_3" 4 "Factor_4" 5 "Factor_5" 6 "Factor_6" 7 "Factor_7" ;
VAL_ 701 LAE_Vx 510 "Init" 511 "Fehler" ;
VAL_ 2463978818 LCV_ESP_Zuschaltung 0 "keine_ESP_Beeinflussung" 1 "ESP_Zwangszuschaltung_gefordert" ;
VAL_ 2463978818 LCV_BrakeGongTemp 0 "Not_Active" 1 "Active" ;
VAL_ 2463978818 BTM_BrakeSystem_Status 0 "Status_1" 1 "Status_2" 2 "Status_3" 3 "Status_4" 4 "Status_5" 5 "Status_6" 6 "Status_7" 7 "Fehler" ;
VAL_ 2463978818 BTM_BrakeSystem_Text 0 "No_text" 1 "Text_1" 2 "Text_2" 3 "Text_3" 4 "Text_4" 5 "Text_5" 6 "Text_6" 7 "Text_7" ;
VAL_ 2463978818 BTM_BrakeSystem_Warnlampe 0 "Lamp_Off" 1 "Lamp_On" ;
VAL_ 2463978818 LCV_Aero_EngineBay_Cooling 0 "Strategy_OFF" 1 "Strategy_ON" ;
VAL_ 2463978818 LCV_Aero_Front_System_Status 0 "Closed" 1 "Position_1" 2 "Position_2" 3 "Opening" 4 "Closing" 5 "Bar_Mode" 6 "Special_Position" 7 "Failure" ;
VAL_ 2463978818 LCV_Aero_Rear_System_Status 0 "Closed" 1 "Position_1" 2 "Position_2" 3 "Opening" 4 "Closing" 5 "Bar_Mode" 6 "Special_Position" 7 "Failure" ;
VAL_ 2463978818 LCV_DR_Systemstatus 0 "Init" 1 "Normal_Operation" 2 "Tune_1" 3 "Tune_2" 4 "Tune_3" 5 "Tune_4" 6 "Function_restriction_active" 7 "Failure" ;
VAL_ 2463978818 LCV_DR_Text 0 "No_Text" 1 "Text_1" 2 "Text_2" 3 "Text_3" 4 "Text_4" 5 "Text_5" 6 "Text_6" 7 "Text_7" ;
VAL_ 2463978818 LCV_DR_Warnlampe 0 "Lamp_Off" 1 "Lamp_On_1" 2 "Lamp_On_2" 3 "Failure_Lamp" ;
VAL_ 2463978818 LCV_Lift_Status 0 "Lowered" 1 "Lifted_front" 2 "Lifting_front" 3 "Lowering_front" 4 "Temporary_unavailable" 5 "Warning" 6 "TBD" 7 "Fehler" 8 "Lifted_four_corner" 9 "Lifting_four_corner" 10 "Lowering_four_corner" ;
VAL_ 2463978818 LCV_Lift_Text 0 "No_Text" 1 "Text_1" 2 "Text_2" 3 "Text_3" 4 "Text_4" 5 "Text_5" 6 "Text_6" 7 "Text_7" ;
VAL_ 2463978818 LCV_Lift_Warnlampe_Status 0 "Lamp_Off" 1 "Lamp_On_Static" 2 "Lamp_On_Blinking" 3 "Failure_Lamp" ;
VAL_ 2463978818 LCV_Aero_Perf_Limit_Speed 254 "init" 255 "Fehler" ;
VAL_ 2463978818 LCV_Aero_Perf_Limit 0 "Strategy_OFF" 1 "Strategy_ON" ;
VAL_ 2463978818 LCV_HD_offen 1 "Heckdeckel_auf" ;
VAL_ 2463978818 LCV_Aero_Text 0 "Text_1" 1 "Text_2" 2 "Text_3" 3 "Text_4" 4 "Text_5" 5 "Text_6" 6 "Text_7" 7 "Text_8" ;
VAL_ 2527679780 LCV_Aero_BarMode_Activation_02 0 "No_popup" 1 "Bar_Mode_not_Available" 2 "Bar_Mode_Opening" 3 "Bar_Mode_Closing" 4 "Bar_Mode_Active" ;
VAL_ 2527679780 LCV_Aero_BarMode_Activation 0 "Not_Active" 1 "Active" ;
VAL_ 2527679780 LCV_BarMode_Allowed 0 "Not_Active" 1 "Active" ;
VAL_ 2527679780 LCV_Aero_Button_Default 0 "None" 1 "Button_1" 2 "Button_2" 3 "Button_3" ;
VAL_ 2527679780 LCV_Aero_Button_Range 0 "none" 1 "first_two" 2 "last_two" 3 "all_three" ;
VAL_ 2527679780 LCV_Aero_Button_Select 0 "None" 1 "Button_1" 2 "Button_2" 3 "Button_3" ;
VAL_ 2527679780 LCV_Aero_Button_Tunable 0 "Not_tunable" 1 "Tunable" ;
VAL_ 2527679780 LCV_DR_Button_Default 0 "None" 1 "Button_1" 2 "Button_2" 3 "Button_3" ;
VAL_ 2527679780 LCV_DR_Button_Range 0 "none" 1 "first_two" 2 "last_two" 3 "all_three" ;
VAL_ 2527679780 LCV_DR_Button_Select 0 "Init" 1 "Button_1" 2 "Button_2" 3 "Button_3" 4 "None" ;
VAL_ 2527679780 LCV_DR_Button_Tunable 0 "Not_tunable" 1 "Tunable" ;
VAL_ 2463978684 BTM_BrakeDiscTemp_01 254 "Init" 255 "Fehler" ;
VAL_ 2463978684 BTM_BrakeDiscTemp_02 254 "Init" 255 "Fehler" ;
VAL_ 2463978684 BTM_BrakeDiscTemp_03 254 "Init" 255 "Fehler" ;
VAL_ 2463978684 BTM_BrakeDiscTemp_04 254 "Init" 255 "Fehler" ;
VAL_ 2463978684 BTM_BrakeFluidTemp_01 254 "Init" 255 "Fehler" ;
VAL_ 2463978684 BTM_BrakeFluidTemp_02 254 "Init" 255 "Fehler" ;
VAL_ 2463978684 BTM_BrakeFluidTemp_03 254 "Init" 255 "Fehler" ;
VAL_ 2463978684 BTM_BrakeFluidTemp_04 254 "Init" 255 "Fehler" ;
VAL_ 548 LCV_Aero_Front_Ratio 126 "init" 127 "Fehler" ;
VAL_ 548 LCV_Aero_Long_Ratio 126 "init" 127 "Fehler" ;
VAL_ 2589283974 BTM_BrakeDiscColour_01 0 "Colour_0" 1 "Colour_1" 2 "Colour_2" 3 "Colour_3" 4 "Colour_4" 5 "Colour_5" 6 "Colour_6" 7 "Fehler" ;
VAL_ 2589283974 BTM_BrakeDiscColour_02 0 "Colour_0" 1 "Colour_1" 2 "Colour_2" 3 "Colour_3" 4 "Colour_4" 5 "Colour_5" 6 "Colour_6" 7 "Fehler" ;
VAL_ 2589283974 BTM_BrakeDiscColour_03 0 "Colour_0" 1 "Colour_1" 2 "Colour_2" 3 "Colour_3" 4 "Colour_4" 5 "Colour_5" 6 "Colour_6" 7 "Fehler" ;
VAL_ 2589283974 BTM_BrakeDiscColour_04 0 "Colour_0" 1 "Colour_1" 2 "Colour_2" 3 "Colour_3" 4 "Colour_4" 5 "Colour_5" 6 "Colour_6" 7 "Fehler" ;
VAL_ 2589283974 BTM_BrakeFluidColour_01 0 "Colour_0" 1 "Colour_1" 2 "Colour_2" 3 "Colour_3" 4 "Colour_4" 5 "Colour_5" 6 "Colour_6" 7 "Fehler" ;
VAL_ 2589283974 BTM_BrakeFluidColour_02 0 "Colour_0" 1 "Colour_1" 2 "Colour_2" 3 "Colour_3" 4 "Colour_4" 5 "Colour_5" 6 "Colour_6" 7 "Fehler" ;
VAL_ 2589283974 BTM_BrakeFluidColour_03 0 "Colour_0" 1 "Colour_1" 2 "Colour_2" 3 "Colour_3" 4 "Colour_4" 5 "Colour_5" 6 "Colour_6" 7 "Fehler" ;
VAL_ 2589283974 BTM_BrakeFluidColour_04 0 "Colour_0" 1 "Colour_1" 2 "Colour_2" 3 "Colour_3" 4 "Colour_4" 5 "Colour_5" 6 "Colour_6" 7 "Fehler" ;
VAL_ 919 LDW_Gong 0 "kein akustisches Signal" 1 "Gong_1" 2 "Gong_2" 3 "Gong_3" ;
VAL_ 919 LDW_Frueh_Spaet 0 "frueh_frueh_aktiv" 1 "frueh_spaet_aktiv" 2 "spaet_spaet_aktiv" 3 "Fehler" ;
VAL_ 919 LDW_Texte 0 "keine_Anzeige" 1 "Laneassist_zur_Zeit_n_verfuegbar" 2 "Laneassist_Systemfehler" 3 "Laneassist_zur_Zeit_keine_SSicht" 4 "Laneassist_Fahreruebernahme" 5 "Laneassist_n_verfuegbar_FoD" 6 "Emergency_Alert_Fahreruebernahme" 7 "Laneassist_FahreruebernahmeLeise" 8 "Laneassist_FahreruebernahmeStumm" 9 "EA_Fahrstreifenwechsel" 10 "Laneassist_Deaktiviert" 11 "Laneassist_Fahreruebernahme_hoch" 12 "Laneassist_mittig_fahren" 13 "Laneassist_adaptiv_aktiv" 14 "Laneassist_adaptiv_deaktiv" 15 "Systgr_Fzgfueh_sofort_uebernehm" ;
VAL_ 919 LDW_Seite_DLCTLC 0 "links" 1 "rechts" ;
VAL_ 919 LDW_Lernmodus 0 "Init_keine_Anzeige" 1 "Lenkeingriff" 2 "Deaktiviert" 3 "Passiv" 4 "Aktiv" 5 "Fehler" 6 "nicht definiert" 7 "nicht definiert" ;
VAL_ 919 LDW_Lernmodus_seitenabhaengig 0 "links_aus__rechts_aus" 1 "HCCA_links_an__rechts_an" 2 "HCCA_links_an__rechts_Warnung" 3 "HCCA_links_Warnung__rechts_an" 4 "links_gestrichelt_rechts_Warnung" 5 "links_outlined__rechts_outlined" 6 "links_outlined__rechts_an" 7 "links_outlined__rechts_Warnung" 8 "links_Warnung_rechts_gestrichel" 9 "links_an__rechts_outlined" 10 "links_an__rechts_an" 11 "links_an__rechts_Warnung" 12 "links_und_rechts_gestrichelt" 13 "links_Warnung__rechts_outlined" 14 "links_Warnung__rechts_an" 15 "links_Warnung__rechts_Warnung" ;
VAL_ 919 LDW_TLC 31 "Init" ;
VAL_ 919 HC_Uss_Anforderung 0 "Ultraschallsensoren Aus" 1 "Ultraschallsensoren An" ;
VAL_ 919 EA_Warnblinken 0 "aus" 1 "Statisch" 2 "Taster" 3 "Statisch_ohne_WBT" ;
VAL_ 919 aLDW_FoD_Status 0 "Init" 1 "Funktion_inaktiv" 2 "Funktion_aktiv" ;
VAL_ 919 LDW_Codierinfo_fuer_VLR 0 "ohne VLR, ohne Akustik" 1 "HMI-Variante VLR" 2 "HMI-Variante VLR + Akustik" 3 "HMI-Variante Akustik" ;
VAL_ 919 LDW_Status_LED_gelb 0 "LDW-Status gelb aus" 1 "LDW-Status gelb aktiv" ;
VAL_ 919 LDW_Status_LED_gruen 0 "LDW-Status gruen aus" 1 "LDW-Status gruen aktiv" ;
VAL_ 919 LKS_LED_an 0 "LED_aus" 1 "LED_ein" ;
VAL_ 810 EPS_SpannungsAnf 0 "keine_Anforderung" 1 "Anforderung_Stufe1" 2 "Anforderung_Stufe2" 3 "Anforderung_Stufe3" ;
VAL_ 810 EPS_Endanschlag 0 "Init_bzw_Defaultlenkhub" 1 "Lenkhubaufweitung_1" 2 "EA_nicht_angelernt_bzw_Initialisierung_nicht_abgeschlossen" 3 "Fehler" ;
VAL_ 810 EPS_Fehlerlampe 0 "Lampe_aus" 1 "Lampe_ein" ;
VAL_ 810 EPS_Warnungen 0 "kein_Text" 1 "Text_1" 2 "Text_2" 3 "Text_3" 4 "Text_4" 5 "Text_5" ;
VAL_ 810 EPS_PWR_Abbruch 0 "Init/Invalid" 1 "PWR beendet durch EPS-SG wegen vFzg" 2 "PWR beendet durch EPS-SG wegen HM" 3 "Lenkwinkeldifferenz zu groß" 4 "Gradient der Zielanforderung zu groß" 5 "reserviert" 6 "reserviert" 7 "reserviert" 8 "Falscher PLA-Status" 9 "Falscher ARA-Status" 10 "reserviert" 11 "reserviert" 12 "reserviert" 13 "reserviert" 14 "reserviert" 15 "reserviert" ;
VAL_ 810 EPS_PWR_Fehler 0 "Init/Invalid" 1 "Unterstützungsleistung zu gering" 2 "reserviert" 3 "Rotorwinkel nicht initialisiert" 4 "BCM1/Rückfahrlicht veraltet" 5 "reserviert" 6 "reserviert" 7 "Fehler ESP(vFzg)" 8 "Fehler ESP(Raddrehzahlen)" 9 "reserviert" 10 "reserviert" 11 "reserviert" 12 "reserviert" 13 "reserviert" 14 "EPS_ARA_Satus == 6" 15 "EPS_PLA_Satus == 6" ;
VAL_ 810 EPS_PLA_Status 0 "EPS_PLA_Deaktiv" 1 "EPS_PLA_Init" 2 "EPS_PLA_Fehler_mit_Eintrag" 3 "reserviert" 4 "reserviert" 5 "reserviert" 6 "EPS_PLA_Lenkwinkel_aktiv" 7 "EPS_PLA_Abgewiesen" 8 "EPS_PLA_Funktionsbereit" 9 "reserviert" 10 "EPS_PLA_Abbruch" 11 "reserviert" 12 "reserviert" 13 "reserviert" 14 "reserviert" 15 "reserviert" ;
VAL_ 810 EPS_Charisma_FahrPr 0 "keine_Funktion" 1 "Programm_1" 2 "Programm_2" 3 "Programm_3" 4 "Programm_4" 5 "Programm_5" 6 "Programm_6" 7 "Programm_7" 8 "Programm_8" 9 "Programm_9" 10 "Programm_10" 11 "Programm_11" 12 "Programm_12" 13 "Programm_13" 14 "Programm_14" 15 "Programm_15" ;
VAL_ 810 EPS_Charisma_Status 0 "Init" 1 "verfuegbar" 2 "nicht_verfuegbar" 3 "asynchron_durch_Fahrerwunsch" ;
VAL_ 810 EPS_Lenkerposition 0 "unbekannt" 1 "Linkslenker" 2 "Rechtslenker" ;
VAL_ 810 EPS_Anf_KL 0 "keine_Anforderung" 1 "Anforderung_Kuehlung" ;
VAL_ 810 EPS_ARA_Status 0 "EPS_ARA_Deaktiv" 1 "EPS_ARA_Init" 2 "EPS_ARA_Fehler_mit_Eintrag" 3 "reserviert" 4 "reserviert" 5 "reserviert" 6 "EPS_ARA_Lenkwinkel_aktiv" 7 "EPS_ARA_Abgewiesen" 8 "EPS_ARA_Funktionsbereit" 9 "reserviert" 10 "EPS_ARA_Abbruch" 11 "reserviert" 12 "reserviert" 13 "reserviert" 14 "reserviert" 15 "reserviert" ;
VAL_ 981 BCM1_Kurvenlicht_links_Anf 0 "linkes_Kurvenlicht/Abbiegelicht_durch_BCM1_nicht_angesteuert" 1 "linkes_Kurven/Abbiegelicht_durch_BCM1_angesteuert" ;
VAL_ 981 BCM1_Kurvenlicht_rechts_Anf 0 "rechtes_Kurvenlicht/Abbiegelicht_durch_BCM1_nicht_angesteuert" 1 "rechtes_Kurvenlicht/Abbiegelicht_durch_BCM1_angesteuert" ;
VAL_ 981 BCM1_Standlicht_Anf 0 "Licht_nicht_angefordert" 1 "Licht ist einzuschalten" ;
VAL_ 981 BCM1_Abblendlicht_Anf 0 "Licht_nicht_angefordert" 1 "Licht ist einzuschalten" ;
VAL_ 981 BCM1_Fernlicht_Anf 0 "Licht_nicht_angefordert" 1 "Licht ist einzuschalten" ;
VAL_ 981 BCM1_Nebellicht_Anf 0 "Licht_nicht_angefordert" 1 "Licht ist einzuschalten" ;
VAL_ 981 BCM1_Parklicht_li_Anf 0 "Licht_nicht_angefordert" 1 "Licht ist einzuschalten" ;
VAL_ 981 BCM1_Parklicht_re_Anf 0 "Licht_nicht_angefordert" 1 "Licht ist einzuschalten" ;
VAL_ 981 BCM1_Nebelschluss_Ahg_Anf 0 "Licht_nicht_angefordert" 1 "Licht ist einzuschalten" ;
VAL_ 981 BCM1_Nebelschluss_Fzg_Anf 0 "Licht_nicht_angefordert" 1 "Licht_ist_einzuschalten" ;
VAL_ 981 BCM1_Schlusslicht_Anf 0 "Licht_nicht_angefordert" 1 "Licht ist einzuschalten" ;
VAL_ 981 BCM_Rueckfahrlicht_Anf 0 "Licht_nicht_angefordert" 1 "Licht_angefordert" ;
VAL_ 981 BCM1_Signaturlicht_Anf 0 "Licht_nicht_angefordert" 1 "Licht_ist_einzuschalten" ;
VAL_ 981 BCM1_Umfeldleuchten_Anf 0 "Licht_nicht_angefordert" 1 "Licht_ist_einzuschalten" ;
VAL_ 981 BCM1_Tagfahrlicht_Anf 0 "Licht_nicht_angefordert" 1 "Licht ist einzuschalten" ;
VAL_ 981 BCM1_Regenlicht_Anf 0 "Licht_nicht_angefordert" 1 "Licht ist einzuschalten" ;
VAL_ 981 BCM1_Autobahnlicht_Anf 0 "Licht_nicht_angefordert" 1 "Licht ist einzuschalten" ;
VAL_ 981 BCM1_Touristen_Licht_Anf 0 "Licht_nicht_angefordert" 1 "Anforderung von Touristenlicht" ;
VAL_ 981 BCM1_CH_aktiv 0 "Inaktiv" 1 "Aktiv" ;
VAL_ 981 BCM1_LH_aktiv 0 "Inaktiv" 1 "Aktiv" ;
VAL_ 981 BCM1_Gleitende_Leuchtw_Anf 0 "Aus" 1 "Ein" ;
VAL_ 981 BCM1_GLW_Fernlicht_Anf 0 "Aus" 1 "Ein" ;
VAL_ 981 BCM1_Adaptive_Lichtvert_Anf 0 "Aus" 1 "Ein" ;
VAL_ 981 BCM1_FoD_Sperrung_WiBli 0 "Freigabe_WiBli" 1 "Sperrung_WiBli" 2 "Init" ;
VAL_ 981 BCM1_FOD_Sperrung_Animationen_HL 0 "Freigabe_Animationen" 1 "Sperrung_Animationen" 2 "Init" ;
VAL_ 981 BCM1_Animationssperrung 0 "keine_Sperrung" 1 "Sperrung" ;
VAL_ 981 BCM1_CH_LH_aktiv 0 "Comming_Home_Bzw._Leaving_Home_nicht_aktiv" 1 "Comming Home bzw. Leaving Home aktiv" ;
VAL_ 981 BCM1_Allwetterlicht_Anf 0 "Licht_nicht_angefordert" 1 "Licht_ist_einzuschalten" ;
VAL_ 981 BCM1_Schlusslicht_Signatur 0 "keine_Signatur" 1 "Signatur_1" 2 "Signatur_2" 3 "Signatur_3" 4 "Signatur_4" 5 "Signatur_5" 6 "Signatur_6" 7 "Signatur_7" 8 "Signatur_8" 9 "Signatur_9" 10 "Signatur_10" 11 "Signatur_11" 12 "Signatur_12" 13 "Signatur_13" 14 "Signatur_14" 15 "Signatur_15" ;
VAL_ 982 BCM2_Bremsl_durch_ECD 0 "Bremslicht_ist_aus" 1 "Bremslicht_durch_ECD_aktiv" ;
VAL_ 982 LH_Aussenlicht_def 0 "OK" 1 "defekt" ;
VAL_ 982 LH_Standlicht_H_aktiv 1 "Standlicht hinten aktiv" ;
VAL_ 982 LH_Parklicht_HL_aktiv 0 "nicht aktiv" 1 "Parklicht hinten links aktiv" ;
VAL_ 982 LH_Parklicht_HR_aktiv 0 "nicht aktiv" 1 "Parklicht hinten rechts aktiv" ;
VAL_ 982 LH_Bremslicht_H_aktiv 1 "Bremslicht hinten aktiv" ;
VAL_ 982 LH_Nebelschluss_aktiv 0 "nicht aktiv" 1 "aktiv" ;
VAL_ 982 LH_Rueckfahrlicht_aktiv 0 "nicht_aktiv" 1 "aktiv" ;
VAL_ 982 LH_Blinker_HL_akt 1 "Blinker hinten links aktiv" ;
VAL_ 982 LH_Blinker_HR_akt 1 "Blinker hinten rechts aktiv" ;
VAL_ 982 LH_Blinker_li_def 0 "OK" 1 "Blinker hinten links defekt" ;
VAL_ 982 LH_Bremsl_li_def 0 "OK" 1 "mindestens ein Bremslicht hinten links defekt" ;
VAL_ 982 LH_Schlusslicht_li_def 0 "OK" 1 "mindestens ein Schlusslicht hinten links defekt" ;
VAL_ 982 LH_Rueckf_li_def 0 "OK" 1 "Rückfahrlicht hinten links defekt" ;
VAL_ 982 LH_Nebel_li_def 0 "OK" 1 " Nebelschlusslicht hinten links defekt" ;
VAL_ 982 LH_Schluss_Brems_Nebel_li_def 0 "iO" 1 "defekt" ;
VAL_ 982 LH_Schluss_Brems_Nebel_re_def 0 "iO" 1 "defekt" ;
VAL_ 982 LH_Zusatzschlussl_def 0 "OK" 1 "mindestens_ein_Zusatzschlusslicht_defekt" ;
VAL_ 982 LH_Schluss_Brems_li_def 0 "OK" 1 "defekt" ;
VAL_ 982 LH_Schluss_Nebel_li_def 0 "OK" 1 "defekt" ;
VAL_ 982 LH_SL_BRL_BLK_li_def 0 "OK" 1 "defekt" ;
VAL_ 982 LH_Brems_Blk_li_def 0 "OK" 1 "defekt" ;
VAL_ 982 LH_Diag_Status_re_def 0 "OK" 1 "Aussenlict_Diagnose_Systemstoerung_rechts" ;
VAL_ 982 LH_Diag_Status_li_def 0 "OK" 1 "Aussenlicht_Diagnose_Systemstoerung_links" ;
VAL_ 982 LH_Diag_LED_li_def 0 "OK" 1 "Heckleuchte_links_defekt" ;
VAL_ 982 LH_Diag_LED_re_def 0 "OK" 1 "Heckleuchte_rechts_defekt" ;
VAL_ 982 LH_Blinker_re_def 0 "OK" 1 "Blinker hinten rechts defekt" ;
VAL_ 982 LH_Bremsl_re_def 0 "OK" 1 "mindestens ein Bremslicht hinten rechts defekt" ;
VAL_ 982 LH_Schlusslicht_re_def 0 "OK" 1 "mindestens ein Schlusslicht hinten rechts defekt" ;
VAL_ 982 LH_Rueckf_re_def 0 "OK" 1 "Rückfahrlicht hinten rechts defekt" ;
VAL_ 982 LH_Nebel_re_def 0 "OK" 1 "Nebelschlusslicht hinten rechts defekt" ;
VAL_ 982 LH_Schluss_Brems_mi_def 0 "OK" 1 "Defekt" ;
VAL_ 982 LH_Schluss_Brems_re_def 0 "OK" 1 "defekt" ;
VAL_ 982 LH_Schluss_Nebel_re_def 0 "OK" 1 "defekt" ;
VAL_ 982 LH_SL_BRL_BLK_re_def 0 "OK" 1 "defekt" ;
VAL_ 982 LH_Brems_Blk_re_def 0 "OK" 1 "defekt" ;
VAL_ 982 LH_Kennzl_def 0 "OK" 1 "Kennzeichenbeleuchtung hinten defekt" ;
VAL_ 982 LH_3_Bremsl_def 0 "OK" 1 "hochgesetzte  Bremsleuchte defekt" ;
VAL_ 982 LH_Nebel_mi_def 0 "OK" 1 " Nebelschlusslicht hinten Mitte defekt" ;
VAL_ 982 LH_Rueckf_mi_def 0 "OK" 1 "Rückfahllicht Mitte defekt" ;
VAL_ 982 LH_Schlusslicht_mi_def 0 "OK" 1 "defekt" ;
VAL_ 982 LH_Bremsl_mi_def 0 "OK" 1 "defekt" ;
VAL_ 982 LH_Bremsl_li_ges_def 0 "OK" 1 "Alle Bremslichter hinten links defekt" ;
VAL_ 982 LH_Bremsl_re_ges_def 0 "OK" 1 "Alle Bremslichter hinten rechts defekt" ;
